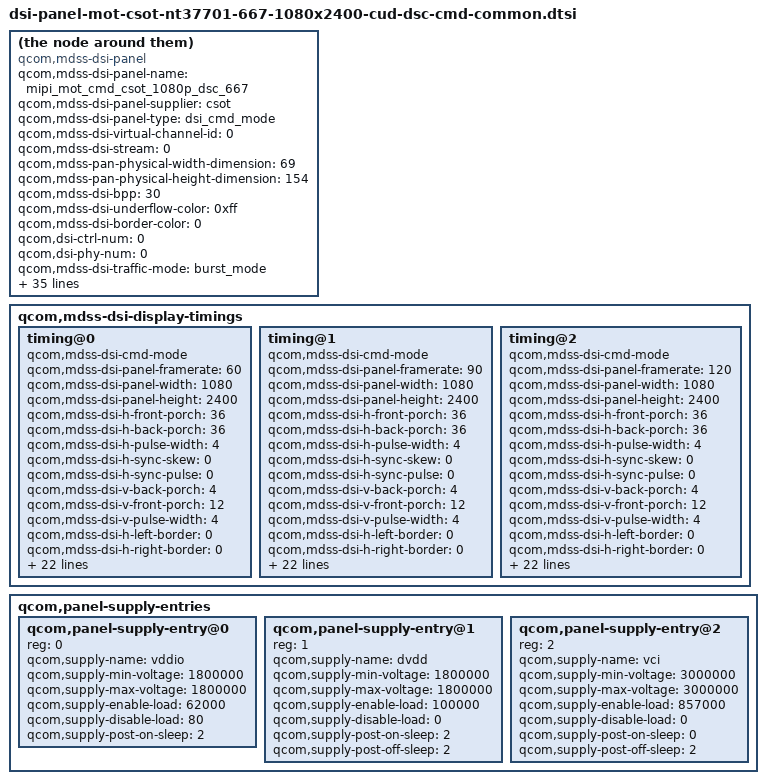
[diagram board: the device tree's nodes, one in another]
/* Copyright (c) 2019-2020, The Linux Foundation. All rights reserved.
 *
 * This program is free software; you can redistribute it and/or modify
 * it under the terms of the GNU General Public License version 2 and
 * only version 2 as published by the Free Software Foundation.
 *
 * This program is distributed in the hope that it will be useful,
 * but WITHOUT ANY WARRANTY; without even the implied warranty of
 * MERCHANTABILITY or FITNESS FOR A PARTICULAR PURPOSE.  See the
 * GNU General Public License for more details.
 */

compatible = "qcom,mdss-dsi-panel";
qcom,mdss-dsi-panel-name = "mipi_mot_cmd_csot_1080p_dsc_667";
qcom,mdss-dsi-panel-supplier = "csot";
qcom,mdss-dsi-panel-type = "dsi_cmd_mode";
qcom,mdss-dsi-virtual-channel-id = <0>;
qcom,mdss-dsi-stream = <0>;
qcom,mdss-pan-physical-width-dimension = <69>;
qcom,mdss-pan-physical-height-dimension = <154>;
qcom,mdss-dsi-bpp = <30>;
qcom,mdss-dsi-underflow-color = <0xff>;
qcom,mdss-dsi-border-color = <0>;

qcom,dsi-ctrl-num = <0>;
qcom,dsi-phy-num = <0>;

qcom,mdss-dsi-traffic-mode = "burst_mode";
qcom,mdss-dsi-bllp-eof-power-mode;
qcom,mdss-dsi-bllp-power-mode;
qcom,mdss-dsi-lane-0-state;
qcom,mdss-dsi-lane-1-state;
qcom,mdss-dsi-lane-2-state;
qcom,mdss-dsi-lane-3-state;

qcom,mdss-dsi-dma-trigger = "trigger_sw";
qcom,mdss-dsi-mdp-trigger = "none";
qcom,mdss-dsi-reset-sequence = <0 11>, <1 1>, <0 1>, <1 11>;
qcom,mdss-dsi-lp11-init;
qcom,mdss-dsi-tx-eot-append;
qcom,mdss-dsi-te-pin-select = <1>;
qcom,mdss-dsi-te-dcs-command = <1>;

qcom,mdss-dsi-te-using-te-pin;

//qcom,esd-check-enabled;
qcom,mdss-dsi-panel-status-check-mode = "te_chk_reg_rd";
qcom,mdss-dsi-panel-status-command = [06 01 00 01 00 00 01 0a];
qcom,mdss-dsi-panel-status-command-state = "dsi_lp_mode";
qcom,mdss-dsi-panel-status-value = <0x9c>;
qcom,mdss-dsi-panel-status-read-length = <1>;

qcom,bklt-dcs-2bytes-enabled;
qcom,mdss-dsi-bl-min-level = <3>;
qcom,mdss-dsi-bl-max-level = <2047>;
qcom,mdss-dsi-bl-default-level = <1024>;
qcom,mdss-brightness-max-level = <2047>;
qcom,mdss-dsi-bl-pmic-control-type = "bl_ctrl_dcs";

qcom,mdss-dsi-hbm-on-command = [
		39 01 00 00 00 00 03 51 0F FF];
qcom,mdss-dsi-hbm-off-command = [
		39 01 00 00 00 00 03 51 07 FF];

//qcom,mdss-dsi-acl-on-command = [
//		39 01 00 00 00 00 06 F0 55 AA 52 08 00
//		15 00 00 00 00 00 02 B0 0C
//		15 01 00 00 00 00 02 55 05];
//qcom,mdss-dsi-acl-off-command = [
//		15 01 00 00 00 00 02 55 00];

qcom,mdss-dsi-panel-hbm-is-51cmd;

qcom,mdss-dsi-display-timings {
	timing@0{
		/* 60 FPS */
		qcom,mdss-dsi-cmd-mode;
		qcom,mdss-dsi-panel-framerate = <60>;
		qcom,mdss-dsi-panel-width = <1080>;
		qcom,mdss-dsi-panel-height = <2400>;
		qcom,mdss-dsi-h-front-porch = <36>;
		qcom,mdss-dsi-h-back-porch = <36>;
		qcom,mdss-dsi-h-pulse-width = <4>;
		qcom,mdss-dsi-h-sync-skew = <0>;
		qcom,mdss-dsi-h-sync-pulse = <0>;
		qcom,mdss-dsi-v-back-porch = <4>;
		qcom,mdss-dsi-v-front-porch = <12>;
		qcom,mdss-dsi-v-pulse-width = <4>;
		qcom,mdss-dsi-h-left-border = <0>;
		qcom,mdss-dsi-h-right-border = <0>;
		qcom,mdss-dsi-v-top-border = <0>;
		qcom,mdss-dsi-v-bottom-border = <0>;
		qcom,mdss-dsi-panel-jitter = <0x20 0xa>;
		//qcom,mdss-mdp-transfer-time-us = <6000>;
		qcom,mdss-dsi-panel-clockrate = <458250000>;
		qcom,mdss-dsi-timing-switch-command = [
			39 01 00 00 00 00 06 F0 55 AA 52 08 02
			15 01 00 00 00 00 02 6F 03
			15 01 00 00 00 00 02 BF 02
			15 01 00 00 10 00 02 2F 01
		];
		qcom,mdss-dsi-on-command = [
			39 01 00 00 00 00 06 F0 55 AA 52 08 00
			15 01 00 00 00 00 02 6F 06
			39 01 00 00 00 00 04 B5 4E 19 50
			15 01 00 00 00 00 02 6F 0D
			15 01 00 00 00 00 02 B5 50
			15 01 00 00 00 00 02 6F 10
			39 01 00 00 00 00 06 B5 19 19 19 19 19

			//CUP enable
			15 01 00 00 00 00 02 99 10

			39 01 00 00 00 00 06 F0 55 AA 52 08 09
			//39 01 00 00 00 00 19 B0 00
			15 01 00 00 00 00 02 B0 01
			39 01 00 00 00 00 19 B1 00 00 00 00 00 00 00 00 00 00 00 00 00 00 00 00 00 00 00 00 00 00 00 00
			15 01 00 00 00 00 02 6F 18
			39 01 00 00 00 00 19 B1 00 00 00 00 00 00 00 00 00 00 00 00 00 00 00 00 00 00 00 00 00 00 00 00
			15 01 00 00 00 00 02 6F 30
			39 01 00 00 00 00 19 B1 00 00 00 00 00 00 00 00 00 00 00 00 00 00 00 00 00 00 00 00 00 00 00 00
			15 01 00 00 00 00 02 6F 48
			39 01 00 00 00 00 19 B1 00 00 00 00 00 00 00 00 00 00 00 00 00 00 00 00 00 00 00 00 00 00 00 00
			15 01 00 00 00 00 02 6F 60
			39 01 00 00 00 00 19 B1 00 00 00 00 00 00 00 00 00 00 00 00 00 00 00 00 00 00 00 00 00 00 00 00
			15 01 00 00 00 00 02 6F 78
			39 01 00 00 00 00 19 B1 00 00 00 00 00 00 00 00 00 00 00 00 00 00 00 00 00 00 00 00 00 00 00 00
			15 01 00 00 00 00 02 6F 90
			39 01 00 00 00 00 19 B1 00 00 00 00 00 00 00 00 00 00 00 00 00 00 00 00 00 00 00 00 00 00 00 00
			15 01 00 00 00 00 02 6F A8
			39 01 00 00 00 00 19 B1 00 00 00 00 00 00 00 00 00 00 00 00 00 00 00 00 00 00 00 00 00 00 00 00
			15 01 00 00 00 00 02 6F C0
			39 01 00 00 00 00 19 B1 00 00 00 00 00 00 00 00 00 00 00 00 00 00 00 00 00 00 00 00 00 00 00 00
			15 01 00 00 00 00 02 6F D8
			39 01 00 00 00 00 19 B1 00 00 00 00 00 00 00 00 00 00 00 00 00 00 00 00 00 00 00 00 00 00 00 00
			15 01 00 00 00 00 02 6F F0
			39 01 00 00 00 00 0D B1 00 00 00 00 00 00 00 00 00 00 00 00
			39 01 00 00 00 00 19 B2 00 00 00 00 00 00 00 00 00 00 00 00 00 00 00 00 00 00 00 00 00 00 00 00
			15 01 00 00 00 00 02 6F 18
			39 01 00 00 00 00 19 B2 00 00 00 00 00 00 00 00 00 00 00 00 00 00 00 00 00 00 00 00 00 00 00 00
			15 01 00 00 00 00 02 6F 30
			39 01 00 00 00 00 19 B2 00 00 00 00 00 00 00 00 00 00 00 00 00 00 00 00 00 00 00 00 00 00 00 00
			15 01 00 00 00 00 02 6F 48
			39 01 00 00 00 00 19 B2 00 00 00 00 00 00 00 00 00 00 00 00 00 00 00 00 00 00 00 00 00 00 00 00
			15 01 00 00 00 00 02 6F 60
			39 01 00 00 00 00 19 B2 00 00 00 00 00 00 00 00 00 00 00 00 00 00 00 00 00 00 00 00 00 00 00 00
			15 01 00 00 00 00 02 6F 78
			39 01 00 00 00 00 19 B2 00 00 00 00 00 00 00 00 00 00 00 00 00 00 00 00 00 00 00 00 00 00 00 00
			15 01 00 00 00 00 02 6F 90
			39 01 00 00 00 00 19 B2 00 00 00 00 00 00 00 00 00 00 00 00 00 00 00 00 00 00 00 00 00 00 00 00
			15 01 00 00 00 00 02 6F A8
			39 01 00 00 00 00 19 B2 00 00 00 00 00 00 00 00 00 00 00 00 00 00 00 00 00 00 00 00 00 00 00 00
			15 01 00 00 00 00 02 6F C0
			39 01 00 00 00 00 19 B2 00 00 00 00 00 00 00 00 00 00 00 00 00 00 00 00 00 00 00 00 00 00 00 00
			15 01 00 00 00 00 02 6F D8
			39 01 00 00 00 00 19 B2 00 00 00 00 00 00 00 00 00 00 00 00 00 00 00 00 00 00 00 00 00 00 00 00
			15 01 00 00 00 00 02 6F F0
			39 01 00 00 00 00 0D B2 00 00 00 00 00 00 00 00 00 00 00 00
			39 01 00 00 00 00 19 B3 00 00 00 00 00 00 00 00 00 00 00 00 00 00 00 00 00 00 00 00 00 00 00 00
			15 01 00 00 00 00 02 6F 18
			39 01 00 00 00 00 19 B3 00 00 00 00 00 00 00 00 00 00 00 00 00 00 00 00 00 00 00 00 00 00 00 00
			15 01 00 00 00 00 02 6F 30
			39 01 00 00 00 00 19 B3 00 00 00 00 00 00 00 00 00 00 00 00 00 00 00 00 00 00 00 00 00 00 00 00
			15 01 00 00 00 00 02 6F 48
			39 01 00 00 00 00 19 B3 00 00 00 00 00 00 00 00 00 00 00 00 00 00 00 00 00 00 00 00 00 00 00 00
			15 01 00 00 00 00 02 6F 60
			39 01 00 00 00 00 19 B3 00 00 00 00 00 00 00 00 00 00 00 00 00 00 00 00 00 00 00 00 00 00 00 00
			15 01 00 00 00 00 02 6F 78
			39 01 00 00 00 00 19 B3 00 00 00 00 00 00 00 00 00 00 00 00 00 00 00 00 00 00 00 00 00 00 00 00
			15 01 00 00 00 00 02 6F 90
			39 01 00 00 00 00 19 B3 00 00 00 00 00 00 00 00 00 00 00 00 00 00 00 00 00 00 00 00 00 00 00 00
			15 01 00 00 00 00 02 6F A8
			39 01 00 00 00 00 19 B3 00 00 00 00 00 00 00 00 00 00 00 00 00 00 00 00 00 00 00 00 00 00 00 00
			15 01 00 00 00 00 02 6F C0
			39 01 00 00 00 00 19 B3 00 00 00 00 00 00 00 00 00 00 00 00 00 00 00 00 00 00 00 00 00 00 00 00
			15 01 00 00 00 00 02 6F D8
			39 01 00 00 00 00 19 B3 00 00 00 00 00 00 00 00 00 00 00 00 00 00 00 00 00 00 00 00 00 00 00 00
			15 01 00 00 00 00 02 6F F0
			39 01 00 00 00 00 0D B3 00 00 00 00 00 00 00 00 00 00 00 00
			39 01 00 00 00 00 19 B4 00 00 00 00 00 00 00 00 00 00 00 00 00 00 00 00 00 00 00 00 00 00 00 00
			15 01 00 00 00 00 02 6F 18
			39 01 00 00 00 00 19 B4 00 00 00 00 00 00 00 00 00 00 00 00 00 00 00 00 00 00 00 00 00 00 00 00
			15 01 00 00 00 00 02 6F 30
			39 01 00 00 00 00 19 B4 00 00 00 00 00 00 00 00 00 00 00 00 00 00 00 00 00 00 00 00 00 00 00 00
			15 01 00 00 00 00 02 6F 48
			39 01 00 00 00 00 19 B4 00 00 00 00 00 00 00 00 00 00 00 00 00 00 00 00 00 00 00 00 00 00 00 00
			15 01 00 00 00 00 02 6F 60
			39 01 00 00 00 00 19 B4 00 00 00 00 00 00 00 00 00 00 00 00 00 00 00 00 00 00 00 00 00 00 00 00
			15 01 00 00 00 00 02 6F 78
			39 01 00 00 00 00 19 B4 00 00 00 00 00 00 00 00 00 00 00 00 00 00 00 00 00 00 00 00 00 00 00 00
			15 01 00 00 00 00 02 6F 90
			39 01 00 00 00 00 19 B4 00 00 00 00 00 00 00 00 00 00 00 00 00 00 00 00 00 00 00 00 00 00 00 00
			15 01 00 00 00 00 02 6F A8
			39 01 00 00 00 00 19 B4 00 00 00 00 00 00 00 00 00 00 00 00 00 00 00 00 00 00 00 00 00 00 00 00
			15 01 00 00 00 00 02 6F C0
			39 01 00 00 00 00 19 B4 00 00 00 00 00 00 00 00 00 00 00 00 00 00 00 00 00 00 00 00 00 00 00 00
			15 01 00 00 00 00 02 6F D8
			39 01 00 00 00 00 19 B4 00 00 00 00 00 00 00 00 00 00 00 00 00 00 00 00 00 00 00 00 00 00 00 00
			15 01 00 00 00 00 02 6F F0
			39 01 00 00 00 00 0D B4 00 00 00 00 00 00 00 00 00 00 00 00
			39 01 00 00 00 00 19 B5 00 00 00 00 00 00 00 00 00 00 00 00 00 00 00 00 00 00 00 00 00 00 00 00
			15 01 00 00 00 00 02 6F 18
			39 01 00 00 00 00 19 B5 00 00 00 00 00 00 00 00 00 00 00 00 00 00 00 00 00 00 00 00 00 00 00 00
			15 01 00 00 00 00 02 6F 30
			39 01 00 00 00 00 19 B5 00 00 00 00 00 00 00 00 00 00 00 00 00 00 00 00 00 00 00 00 00 00 00 00
			15 01 00 00 00 00 02 6F 48
			39 01 00 00 00 00 19 B5 00 00 00 00 00 00 00 00 00 00 00 00 00 00 00 00 00 00 00 00 00 00 00 00
			15 01 00 00 00 00 02 6F 60
			39 01 00 00 00 00 19 B5 00 00 00 00 00 00 00 00 00 00 00 00 00 00 00 00 00 00 00 00 00 00 00 00
			15 01 00 00 00 00 02 6F 78
			39 01 00 00 00 00 19 B5 00 00 00 00 00 00 00 00 00 00 00 00 00 00 00 00 00 00 00 00 00 00 00 00
			15 01 00 00 00 00 02 6F 90
			39 01 00 00 00 00 19 B5 00 00 00 00 00 00 00 00 00 00 00 00 00 00 00 00 00 00 00 00 00 00 00 00
			15 01 00 00 00 00 02 6F A8
			39 01 00 00 00 00 19 B5 00 00 00 00 00 00 00 00 00 00 00 00 00 00 00 00 00 00 00 00 00 00 00 00
			15 01 00 00 00 00 02 6F C0
			39 01 00 00 00 00 19 B5 00 00 00 00 00 00 00 00 00 00 00 00 00 00 00 00 00 00 00 00 00 00 00 00
			15 01 00 00 00 00 02 6F D8
			39 01 00 00 00 00 19 B5 00 00 00 00 00 00 00 00 00 00 00 00 00 00 00 00 00 00 00 00 00 00 00 00
			15 01 00 00 00 00 02 6F F0
			39 01 00 00 00 00 0D B5 00 00 00 00 00 00 00 00 00 00 00 00
			39 01 00 00 00 00 19 B6 00 00 00 00 00 00 00 00 00 00 00 00 00 00 00 00 00 00 00 00 00 00 00 00
			15 01 00 00 00 00 02 6F 18
			39 01 00 00 00 00 19 B6 00 00 00 00 00 00 00 00 00 00 00 00 00 00 00 00 00 00 00 00 00 00 00 00
			15 01 00 00 00 00 02 6F 30
			39 01 00 00 00 00 19 B6 00 00 00 00 00 00 00 00 00 00 00 00 00 00 00 00 00 00 00 00 00 00 00 00
			15 01 00 00 00 00 02 6F 48
			39 01 00 00 00 00 19 B6 00 00 00 00 00 00 00 00 00 00 00 00 00 00 00 00 00 00 00 00 00 00 00 00
			15 01 00 00 00 00 02 6F 60
			39 01 00 00 00 00 19 B6 00 00 00 00 00 00 00 00 00 00 00 00 00 00 00 00 00 00 00 00 00 00 00 00
			15 01 00 00 00 00 02 6F 78
			39 01 00 00 00 00 19 B6 00 00 00 00 00 00 00 00 00 00 00 00 00 00 00 00 00 00 00 00 00 00 00 00
			15 01 00 00 00 00 02 6F 90
			39 01 00 00 00 00 19 B6 00 00 00 00 00 00 00 00 00 00 00 00 00 00 00 00 00 00 00 00 00 00 00 00
			15 01 00 00 00 00 02 6F A8
			39 01 00 00 00 00 19 B6 00 00 00 00 00 00 00 00 00 00 00 00 00 00 00 00 00 00 00 00 00 00 00 00
			15 01 00 00 00 00 02 6F C0
			39 01 00 00 00 00 19 B6 00 00 00 00 00 00 00 00 00 00 00 00 00 00 00 00 00 00 00 00 00 00 00 00
			15 01 00 00 00 00 02 6F D8
			39 01 00 00 00 00 19 B6 00 00 00 00 00 00 00 00 00 00 00 00 00 00 00 00 00 00 00 00 00 00 00 00
			15 01 00 00 00 00 02 6F F0
			39 01 00 00 00 00 0D B6 00 00 00 00 00 00 00 00 00 00 00 00
			39 01 00 00 00 00 19 B7 00 00 00 00 00 00 00 00 00 00 00 00 00 00 00 00 00 00 00 00 00 00 00 00
			15 01 00 00 00 00 02 6F 18
			39 01 00 00 00 00 19 B7 00 00 00 00 00 00 00 00 00 00 00 00 00 00 00 00 00 00 00 00 00 00 00 00
			15 01 00 00 00 00 02 6F 30
			39 01 00 00 00 00 19 B7 00 00 00 00 00 00 00 00 00 00 00 00 00 00 00 00 00 00 00 00 00 00 00 00
			15 01 00 00 00 00 02 6F 48
			39 01 00 00 00 00 19 B7 00 00 00 00 00 00 00 00 00 00 00 00 00 00 00 00 00 00 00 00 00 00 00 00
			15 01 00 00 00 00 02 6F 60
			39 01 00 00 00 00 19 B7 00 00 00 00 00 00 00 00 00 00 00 00 00 00 00 00 00 00 00 00 00 00 00 00
			15 01 00 00 00 00 02 6F 78
			39 01 00 00 00 00 19 B7 00 00 00 00 00 00 00 00 00 00 00 00 00 00 00 00 00 00 00 00 00 00 00 00
			15 01 00 00 00 00 02 6F 90
			39 01 00 00 00 00 19 B7 00 00 00 00 00 00 00 00 00 00 00 00 00 00 00 00 00 00 00 00 00 00 00 00
			15 01 00 00 00 00 02 6F A8
			39 01 00 00 00 00 19 B7 00 00 00 00 00 00 00 00 00 00 00 00 00 00 00 00 00 00 00 00 00 00 00 00
			15 01 00 00 00 00 02 6F C0
			39 01 00 00 00 00 19 B7 00 00 00 00 00 00 00 00 00 00 00 00 00 00 00 00 00 00 00 00 00 00 00 00
			15 01 00 00 00 00 02 6F D8
			39 01 00 00 00 00 19 B7 00 00 00 00 00 00 00 00 00 00 00 00 00 00 00 00 00 00 00 00 00 00 00 00
			15 01 00 00 00 00 02 6F F0
			39 01 00 00 00 00 0D B7 00 00 00 00 00 00 00 00 00 00 00 00

			39 01 00 00 00 00 19 BA 00 00 00 00 00 00 00 00 00 00 00 00 00 00 00 00 00 00 00 00 00 00 00 00
			15 01 00 00 00 00 02 6F 18
			39 01 00 00 00 00 19 BA 00 00 00 00 00 00 00 00 00 00 00 00 00 00 00 00 00 00 00 00 00 00 00 00
			15 01 00 00 00 00 02 6F 30
			39 01 00 00 00 00 19 BA 00 00 00 00 00 00 00 00 00 00 00 00 00 00 00 00 00 00 00 00 00 00 00 00
			15 01 00 00 00 00 02 6F 48
			39 01 00 00 00 00 19 BA 00 00 00 00 00 00 00 00 00 00 00 00 00 00 00 00 00 00 00 00 00 00 00 00
			15 01 00 00 00 00 02 6F 60
			39 01 00 00 00 00 19 BA 00 00 00 00 00 00 00 00 00 00 00 00 00 00 00 00 00 00 00 00 00 00 00 00
			15 01 00 00 00 00 02 6F 78
			39 01 00 00 00 00 19 BA 00 00 00 00 00 00 00 00 00 00 00 00 00 00 00 00 00 00 00 00 00 00 00 00
			15 01 00 00 00 00 02 6F 90
			39 01 00 00 00 00 19 BA 00 00 00 00 00 00 00 00 00 00 00 00 00 00 00 00 00 00 00 00 00 00 00 00
			15 01 00 00 00 00 02 6F A8
			39 01 00 00 00 00 19 BA 00 00 00 00 00 00 00 00 00 00 00 00 00 00 00 00 00 00 00 00 00 00 00 00
			15 01 00 00 00 00 02 6F C0
			39 01 00 00 00 00 19 BA 00 00 00 00 00 00 00 00 00 00 00 00 00 00 00 00 00 00 00 00 00 00 00 00
			15 01 00 00 00 00 02 6F D8
			39 01 00 00 00 00 19 BA 00 00 00 00 00 00 00 00 00 00 00 00 00 00 00 00 00 00 00 00 00 00 00 00
			15 01 00 00 00 00 02 6F F0
			39 01 00 00 00 00 0D BA 00 00 00 00 00 00 00 00 00 00 00 00
			39 01 00 00 00 00 19 BB 00 00 00 00 00 00 00 00 00 00 00 00 00 00 00 00 00 00 00 00 00 00 00 00
			15 01 00 00 00 00 02 6F 18
			39 01 00 00 00 00 19 BB 00 00 00 00 00 00 00 00 00 00 00 00 00 00 00 00 00 00 00 00 00 00 00 00
			15 01 00 00 00 00 02 6F 30
			39 01 00 00 00 00 19 BB 00 00 00 00 00 00 00 00 00 00 00 00 00 00 00 00 00 00 00 00 00 00 00 00
			15 01 00 00 00 00 02 6F 48
			39 01 00 00 00 00 19 BB 00 00 00 00 00 00 00 00 00 00 00 00 00 00 00 00 00 00 00 00 00 00 00 00
			15 01 00 00 00 00 02 6F 60
			39 01 00 00 00 00 19 BB 00 00 00 00 00 00 00 00 00 00 00 00 00 00 00 00 00 00 00 00 00 00 00 00
			15 01 00 00 00 00 02 6F 78
			39 01 00 00 00 00 19 BB 00 00 00 00 00 00 00 00 00 00 00 00 00 00 00 00 00 00 00 00 00 00 00 00
			15 01 00 00 00 00 02 6F 90
			39 01 00 00 00 00 19 BB 00 00 00 00 00 00 00 00 00 00 00 00 00 00 00 00 00 00 00 00 00 00 00 00
			15 01 00 00 00 00 02 6F A8
			39 01 00 00 00 00 19 BB 00 00 00 00 00 00 00 00 00 00 00 00 00 00 00 00 00 00 00 00 00 00 00 00
			15 01 00 00 00 00 02 6F C0
			39 01 00 00 00 00 19 BB 00 00 00 00 00 00 00 00 00 00 00 00 00 00 00 00 00 00 00 00 00 00 00 00
			15 01 00 00 00 00 02 6F D8
			39 01 00 00 00 00 19 BB 00 00 00 00 00 00 00 00 00 00 00 00 00 00 00 00 00 00 00 00 00 00 00 00
			15 01 00 00 00 00 02 6F F0
			39 01 00 00 00 00 0D BB 00 00 00 00 00 00 00 00 00 00 00 00
			39 01 00 00 00 00 19 BC 00 00 00 00 00 00 00 00 00 00 00 00 00 00 00 00 00 00 00 00 00 00 00 00
			15 01 00 00 00 00 02 6F 18
			39 01 00 00 00 00 19 BC 00 00 00 00 00 00 00 00 00 00 00 00 00 00 00 00 00 00 00 00 00 00 00 00
			15 01 00 00 00 00 02 6F 30
			39 01 00 00 00 00 19 BC 00 00 00 00 00 00 00 00 00 00 00 00 00 00 00 00 00 00 00 00 00 00 00 00
			15 01 00 00 00 00 02 6F 48
			39 01 00 00 00 00 19 BC 00 00 00 00 00 00 00 00 00 00 00 00 00 00 00 00 00 00 00 00 00 00 00 00
			15 01 00 00 00 00 02 6F 60
			39 01 00 00 00 00 19 BC 00 00 00 00 00 00 00 00 00 00 00 00 00 00 00 00 00 00 00 00 00 00 00 00
			15 01 00 00 00 00 02 6F 78
			39 01 00 00 00 00 19 BC 00 00 00 00 00 00 00 00 00 00 00 00 00 00 00 00 00 00 00 00 00 00 00 00
			15 01 00 00 00 00 02 6F 90
			39 01 00 00 00 00 19 BC 00 00 00 00 00 00 00 00 00 00 00 00 00 00 00 00 00 00 00 00 00 00 00 00
			15 01 00 00 00 00 02 6F A8
			39 01 00 00 00 00 19 BC 00 00 00 00 00 00 00 00 00 00 00 00 00 00 00 00 00 00 00 00 00 00 00 00
			15 01 00 00 00 00 02 6F C0
			39 01 00 00 00 00 19 BC 00 00 00 00 00 00 00 00 00 00 00 00 00 00 00 00 00 00 00 00 00 00 00 00
			15 01 00 00 00 00 02 6F D8
			39 01 00 00 00 00 19 BC 00 00 00 00 00 00 00 00 00 00 00 00 00 00 00 00 00 00 00 00 00 00 00 00
			15 01 00 00 00 00 02 6F F0
			39 01 00 00 00 00 0D BC 00 00 00 00 00 00 00 00 00 00 00 00
			39 01 00 00 00 00 19 BD 00 00 00 00 00 00 00 00 00 00 00 00 00 00 00 00 00 00 00 00 00 00 00 00
			15 01 00 00 00 00 02 6F 18
			39 01 00 00 00 00 19 BD 00 00 00 00 00 00 00 00 00 00 00 00 00 00 00 00 00 00 00 00 00 00 00 00
			15 01 00 00 00 00 02 6F 30
			39 01 00 00 00 00 19 BD 00 00 00 00 00 00 00 00 00 00 00 00 00 00 00 00 00 00 00 00 00 00 00 00
			15 01 00 00 00 00 02 6F 48
			39 01 00 00 00 00 19 BD 00 00 00 00 00 00 00 00 00 00 00 00 00 00 00 00 00 00 00 00 00 00 00 00
			15 01 00 00 00 00 02 6F 60
			39 01 00 00 00 00 19 BD 00 00 00 00 00 00 00 00 00 00 00 00 00 00 00 00 00 00 00 00 00 00 00 00
			15 01 00 00 00 00 02 6F 78
			39 01 00 00 00 00 19 BD 00 00 00 00 00 00 00 00 00 00 00 00 00 00 00 00 00 00 00 00 00 00 00 00
			15 01 00 00 00 00 02 6F 90
			39 01 00 00 00 00 19 BD 00 00 00 00 00 00 00 00 00 00 00 00 00 00 00 00 00 00 00 00 00 00 00 00
			15 01 00 00 00 00 02 6F A8
			39 01 00 00 00 00 19 BD 00 00 00 00 00 00 00 00 00 00 00 00 00 00 00 00 00 00 00 00 00 00 00 00
			15 01 00 00 00 00 02 6F C0
			39 01 00 00 00 00 19 BD 00 00 00 00 00 00 00 00 00 00 00 00 00 00 00 00 00 00 00 00 00 00 00 00
			15 01 00 00 00 00 02 6F D8
			39 01 00 00 00 00 19 BD 00 00 00 00 00 00 00 00 00 00 00 00 00 00 00 00 00 00 00 00 00 00 00 00
			15 01 00 00 00 00 02 6F F0
			39 01 00 00 00 00 0D BD 00 00 00 00 00 00 00 00 00 00 00 00
			39 01 00 00 00 00 19 BE 00 00 00 00 00 00 00 00 00 00 00 00 00 00 00 00 00 00 00 00 00 00 00 00
			15 01 00 00 00 00 02 6F 18
			39 01 00 00 00 00 19 BE 00 00 00 00 00 00 00 00 00 00 00 00 00 00 00 00 00 00 00 00 00 00 00 00
			15 01 00 00 00 00 02 6F 30
			39 01 00 00 00 00 19 BE 00 00 00 00 00 00 00 00 00 00 00 00 00 00 00 00 00 00 00 00 00 00 00 00
			15 01 00 00 00 00 02 6F 48
			39 01 00 00 00 00 19 BE 00 00 00 00 00 00 00 00 00 00 00 00 00 00 00 00 00 00 00 00 00 00 00 00
			15 01 00 00 00 00 02 6F 60
			39 01 00 00 00 00 19 BE 00 00 00 00 00 00 00 00 00 00 00 00 00 00 00 00 00 00 00 00 00 00 00 00
			15 01 00 00 00 00 02 6F 78
			39 01 00 00 00 00 19 BE 00 00 00 00 00 00 00 00 00 00 00 00 00 00 00 00 00 00 00 00 00 00 00 00
			15 01 00 00 00 00 02 6F 90
			39 01 00 00 00 00 19 BE 00 00 00 00 00 00 00 00 00 00 00 00 00 00 00 00 00 00 00 00 00 00 00 00
			15 01 00 00 00 00 02 6F A8
			39 01 00 00 00 00 19 BE 00 00 00 00 00 00 00 00 00 00 00 00 00 00 00 00 00 00 00 00 00 00 00 00
			15 01 00 00 00 00 02 6F C0
			39 01 00 00 00 00 19 BE 00 00 00 00 00 00 00 00 00 00 00 00 00 00 00 00 00 00 00 00 00 00 00 00
			15 01 00 00 00 00 02 6F D8
			39 01 00 00 00 00 19 BE 00 00 00 00 00 00 00 00 00 00 00 00 00 00 00 00 00 00 00 00 00 00 00 00
			15 01 00 00 00 00 02 6F F0
			39 01 00 00 00 00 0D BE 00 00 00 00 00 00 00 00 00 00 00 00
			39 01 00 00 00 00 19 BF 00 00 00 00 00 00 00 00 00 00 00 00 00 00 00 00 00 00 00 00 00 00 00 00
			15 01 00 00 00 00 02 6F 18
			39 01 00 00 00 00 19 BF 00 00 00 00 00 00 00 00 00 00 00 00 00 00 00 00 00 00 00 00 00 00 00 00
			15 01 00 00 00 00 02 6F 30
			39 01 00 00 00 00 19 BF 00 00 00 00 00 00 00 00 00 00 00 00 00 00 00 00 00 00 00 00 00 00 00 00
			15 01 00 00 00 00 02 6F 48
			39 01 00 00 00 00 19 BF 00 00 00 00 00 00 00 00 00 00 00 00 00 00 00 00 00 00 00 00 00 00 00 00
			15 01 00 00 00 00 02 6F 60
			39 01 00 00 00 00 19 BF 00 00 00 00 00 00 00 00 00 00 00 00 00 00 00 00 00 00 00 00 00 00 00 00
			15 01 00 00 00 00 02 6F 78
			39 01 00 00 00 00 19 BF 00 00 00 00 00 00 00 00 00 00 00 00 00 00 00 00 00 00 00 00 00 00 00 00
			15 01 00 00 00 00 02 6F 90
			39 01 00 00 00 00 19 BF 00 00 00 00 00 00 00 00 00 00 00 00 00 00 00 00 00 00 00 00 00 00 00 00
			15 01 00 00 00 00 02 6F A8
			39 01 00 00 00 00 19 BF 00 00 00 00 00 00 00 00 00 00 00 00 00 00 00 00 00 00 00 00 00 00 00 00
			15 01 00 00 00 00 02 6F C0
			39 01 00 00 00 00 19 BF 00 00 00 00 00 00 00 00 00 00 00 00 00 00 00 00 00 00 00 00 00 00 00 00
			15 01 00 00 00 00 02 6F D8
			39 01 00 00 00 00 19 BF 00 00 00 00 00 00 00 00 00 00 00 00 00 00 00 00 00 00 00 00 00 00 00 00
			15 01 00 00 00 00 02 6F F0
			39 01 00 00 00 00 0D BF 00 00 00 00 00 00 00 00 00 00 00 00
			39 01 00 00 00 00 19 C0 00 00 00 00 00 00 00 00 00 00 00 00 00 00 00 00 00 00 00 00 00 00 00 00
			15 01 00 00 00 00 02 6F 18
			39 01 00 00 00 00 19 C0 00 00 00 00 00 00 00 00 00 00 00 00 00 00 00 00 00 00 00 00 00 00 00 00
			15 01 00 00 00 00 02 6F 30
			39 01 00 00 00 00 19 C0 00 00 00 00 00 00 00 00 00 00 00 00 00 00 00 00 00 00 00 00 00 00 00 00
			15 01 00 00 00 00 02 6F 48
			39 01 00 00 00 00 19 C0 00 00 00 00 00 00 00 00 00 00 00 00 00 00 00 00 00 00 00 00 00 00 00 00
			15 01 00 00 00 00 02 6F 60
			39 01 00 00 00 00 19 C0 00 00 00 00 00 00 00 00 00 00 00 00 00 00 00 00 00 00 00 00 00 00 00 00
			15 01 00 00 00 00 02 6F 78
			39 01 00 00 00 00 19 C0 00 00 00 00 00 00 00 00 00 00 00 00 00 00 00 00 00 00 00 00 00 00 00 00
			15 01 00 00 00 00 02 6F 90
			39 01 00 00 00 00 19 C0 00 00 00 00 00 00 00 00 00 00 00 00 00 00 00 00 00 00 00 00 00 00 00 00
			15 01 00 00 00 00 02 6F A8
			39 01 00 00 00 00 19 C0 00 00 00 00 00 00 00 00 00 00 00 00 00 00 00 00 00 00 00 00 00 00 00 00
			15 01 00 00 00 00 02 6F C0
			39 01 00 00 00 00 19 C0 00 00 00 00 00 00 00 00 00 00 00 00 00 00 00 00 00 00 00 00 00 00 00 00
			15 01 00 00 00 00 02 6F D8
			39 01 00 00 00 00 19 C0 00 00 00 00 00 00 00 00 00 00 00 00 00 00 00 00 00 00 00 00 00 00 00 00
			15 01 00 00 00 00 02 6F F0
			39 01 00 00 00 00 0D C0 00 00 00 00 00 00 00 00 00 00 00 00

			39 01 00 00 00 00 19 C3 00 00 00 60 90 00 00 00 00 00 10 1F 00 00 00 00 50 21 00 00 00 00 00 00
			15 01 00 00 00 00 02 6F 18
			39 01 00 00 00 00 19 C3 00 00 00 00 00 00 00 00 00 00 00 18 00 00 00 00 00 00 00 00 00 00 00 10
			15 01 00 00 00 00 02 6F 30
			39 01 00 00 00 00 19 C3 00 00 00 00 00 00 00 00 00 00 00 10 00 00 00 00 00 00 00 00 00 00 00 10
			15 01 00 00 00 00 02 6F 48
			39 01 00 00 00 00 19 C3 00 00 00 00 00 00 00 00 00 00 00 08 00 00 00 00 00 00 00 00 00 00 00 08
			15 01 00 00 00 00 02 6F 60
			39 01 00 00 00 00 19 C3 00 00 00 00 00 00 00 00 00 00 00 08 00 00 00 00 00 00 00 00 00 00 00 08
			15 01 00 00 00 00 02 6F 78
			39 01 00 00 00 00 19 C3 00 00 00 00 00 00 00 00 00 00 00 00 00 00 00 00 00 00 00 00 00 00 00 08
			15 01 00 00 00 00 02 6F 90
			39 01 00 00 00 00 19 C3 00 00 00 00 00 00 00 00 00 00 00 00 00 00 00 00 00 00 00 00 00 00 00 08
			15 01 00 00 00 00 02 6F A8
			39 01 00 00 00 00 19 C3 00 00 00 00 00 00 00 00 00 00 00 00 00 00 00 00 00 00 00 00 00 00 00 08
			15 01 00 00 00 00 02 6F C0
			39 01 00 00 00 00 19 C3 00 00 00 00 00 00 00 00 00 00 00 00 00 00 00 00 00 00 00 00 00 00 00 00
			15 01 00 00 00 00 02 6F D8
			39 01 00 00 00 00 19 C3 00 00 00 00 00 00 00 00 00 00 00 08 00 00 00 00 00 00 00 00 00 00 00 00
			15 01 00 00 00 00 02 6F F0
			39 01 00 00 00 00 0D C3 00 00 00 00 00 00 00 00 00 00 00 00
			39 01 00 00 00 00 19 C4 00 00 00 00 00 00 00 00 00 00 00 00 00 00 00 00 00 00 00 00 00 00 00 00
			15 01 00 00 00 00 02 6F 18
			39 01 00 00 00 00 19 C4 00 00 00 00 00 00 00 00 00 00 00 00 00 00 00 00 00 00 00 00 00 00 00 00
			15 01 00 00 00 00 02 6F 30
			39 01 00 00 00 00 19 C4 00 00 00 00 00 00 00 00 00 00 00 00 00 00 00 00 00 00 00 00 00 00 00 08
			15 01 00 00 00 00 02 6F 48
			39 01 00 00 00 00 19 C4 00 00 00 00 00 00 00 00 00 00 00 00 00 00 00 00 00 00 00 00 00 00 00 00
			15 01 00 00 00 00 02 6F 60
			39 01 00 00 00 00 19 C4 00 00 00 00 00 00 00 00 00 00 00 08 00 00 00 00 00 00 00 00 00 00 00 00
			15 01 00 00 00 00 02 6F 78
			39 01 00 00 00 00 19 C4 00 00 00 00 00 00 00 00 00 00 00 08 00 00 00 00 00 00 00 00 00 00 00 00
			15 01 00 00 00 00 02 6F 90
			39 01 00 00 00 00 19 C4 00 00 00 00 00 00 00 00 00 00 00 08 00 00 00 00 00 00 00 00 00 00 00 00
			15 01 00 00 00 00 02 6F A8
			39 01 00 00 00 00 19 C4 00 00 00 00 00 00 00 00 00 00 00 08 00 00 00 00 00 00 00 00 00 00 00 08
			15 01 00 00 00 00 02 6F C0
			39 01 00 00 00 00 19 C4 00 00 00 00 00 00 00 00 00 00 00 08 00 00 00 00 00 00 00 00 00 00 00 08
			15 01 00 00 00 00 02 6F D8
			39 01 00 00 00 00 19 C4 00 00 00 00 00 00 00 00 00 00 00 10 00 00 00 00 00 00 00 00 00 00 00 10
			15 01 00 00 00 00 02 6F F0
			39 01 00 00 00 00 0D C4 00 00 00 00 00 00 00 00 00 00 00 10
			39 01 00 00 00 00 19 C5 00 00 00 00 00 00 00 00 00 00 00 18 00 00 00 00 00 00 00 00 00 00 00 00
			15 01 00 00 00 00 02 6F 18
			39 01 00 00 00 00 19 C5 00 00 00 00 00 00 00 00 00 00 00 00 00 00 00 00 00 00 00 00 00 00 00 00
			15 01 00 00 00 00 02 6F 30
			39 01 00 00 00 00 19 C5 00 00 00 00 00 00 00 00 00 00 00 00 00 00 00 00 00 00 00 00 00 00 00 00
			15 01 00 00 00 00 02 6F 48
			39 01 00 00 00 00 19 C5 00 00 00 00 00 00 00 00 00 00 00 00 00 00 00 00 00 00 00 00 00 00 00 00
			15 01 00 00 00 00 02 6F 60
			39 01 00 00 00 00 19 C5 00 00 00 00 00 00 00 00 00 00 00 00 00 00 00 00 00 00 00 00 00 00 00 00
			15 01 00 00 00 00 02 6F 78
			39 01 00 00 00 00 19 C5 00 00 00 00 00 00 00 00 00 00 00 00 00 00 00 00 00 00 00 00 00 00 00 00
			15 01 00 00 00 00 02 6F 90
			39 01 00 00 00 00 19 C5 00 00 00 00 00 00 00 00 00 00 00 00 00 00 00 00 00 00 00 00 00 00 00 00
			15 01 00 00 00 00 02 6F A8
			39 01 00 00 00 00 19 C5 00 00 00 00 00 00 00 00 00 00 00 00 00 00 00 00 00 00 00 00 00 00 00 00
			15 01 00 00 00 00 02 6F C0
			39 01 00 00 00 00 19 C5 00 00 00 00 00 00 00 00 00 00 00 00 00 00 00 00 00 00 00 00 00 00 00 00
			15 01 00 00 00 00 02 6F D8
			39 01 00 00 00 00 19 C5 00 00 00 00 00 00 00 00 00 00 00 00 00 00 00 00 00 00 00 00 00 00 00 00
			15 01 00 00 00 00 02 6F F0
			39 01 00 00 00 00 0D C5 00 00 00 00 00 00 00 00 00 00 00 00
			39 01 00 00 00 00 19 C6 00 00 00 00 00 00 00 00 00 00 00 00 00 00 00 00 00 00 00 00 00 00 00 00
			15 01 00 00 00 00 02 6F 18
			39 01 00 00 00 00 19 C6 00 00 00 00 00 00 00 00 00 00 00 00 00 00 00 00 00 00 00 00 00 00 00 00
			15 01 00 00 00 00 02 6F 30
			39 01 00 00 00 00 19 C6 00 00 00 00 00 00 00 00 00 00 00 00 00 00 00 00 00 00 00 00 00 00 00 00
			15 01 00 00 00 00 02 6F 48
			39 01 00 00 00 00 19 C6 00 00 00 00 00 00 00 00 00 00 00 00 00 00 00 00 00 00 00 00 00 00 00 00
			15 01 00 00 00 00 02 6F 60
			39 01 00 00 00 00 19 C6 00 00 00 00 00 00 00 00 00 00 00 00 00 00 00 00 00 00 00 00 00 00 00 00
			15 01 00 00 00 00 02 6F 78
			39 01 00 00 00 00 19 C6 00 00 00 00 00 00 00 00 00 00 00 00 00 00 00 00 00 00 00 00 00 00 00 00
			15 01 00 00 00 00 02 6F 90
			39 01 00 00 00 00 19 C6 00 00 00 00 00 00 00 00 00 00 00 00 00 00 00 00 00 00 00 00 00 00 00 00
			15 01 00 00 00 00 02 6F A8
			39 01 00 00 00 00 19 C6 00 00 00 00 00 00 00 00 00 00 00 00 00 00 00 00 00 00 00 00 00 00 00 00
			15 01 00 00 00 00 02 6F C0
			39 01 00 00 00 00 19 C6 00 00 00 00 00 00 00 00 00 00 00 00 00 00 00 00 00 00 00 00 00 00 00 00
			15 01 00 00 00 00 02 6F D8
			39 01 00 00 00 00 19 C6 00 00 00 00 00 00 00 00 00 00 00 00 00 00 00 00 00 00 00 00 00 00 00 00
			15 01 00 00 00 00 02 6F F0
			39 01 00 00 00 00 0D C6 00 00 00 00 00 00 00 00 00 00 00 00
			39 01 00 00 00 00 19 C7 00 00 00 00 00 00 00 00 00 00 00 00 00 00 00 00 00 00 00 00 00 00 00 00
			15 01 00 00 00 00 02 6F 18
			39 01 00 00 00 00 19 C7 00 00 00 00 00 00 00 00 00 00 00 00 00 00 00 00 00 00 00 00 00 00 00 00
			15 01 00 00 00 00 02 6F 30
			39 01 00 00 00 00 19 C7 00 00 00 00 00 00 00 00 00 00 00 00 00 00 00 00 00 00 00 00 00 00 00 00
			15 01 00 00 00 00 02 6F 48
			39 01 00 00 00 00 19 C7 00 00 00 00 00 00 00 00 00 00 00 00 00 00 00 00 00 00 00 00 00 00 00 00
			15 01 00 00 00 00 02 6F 60
			39 01 00 00 00 00 19 C7 00 00 00 00 00 00 00 00 00 00 00 00 00 00 00 00 00 00 00 00 00 00 00 00
			15 01 00 00 00 00 02 6F 78
			39 01 00 00 00 00 19 C7 00 00 00 00 00 00 00 00 00 00 00 00 00 00 00 00 00 00 00 00 00 00 00 00
			15 01 00 00 00 00 02 6F 90
			39 01 00 00 00 00 19 C7 00 00 00 00 00 00 00 00 00 00 00 00 00 00 00 00 00 00 00 00 00 00 00 00
			15 01 00 00 00 00 02 6F A8
			39 01 00 00 00 00 19 C7 00 00 00 00 00 00 00 00 00 00 00 00 00 00 00 00 00 00 00 00 00 00 00 00
			15 01 00 00 00 00 02 6F C0
			39 01 00 00 00 00 19 C7 00 00 00 00 00 00 00 00 00 00 00 00 00 00 00 00 00 00 00 00 00 00 00 00
			15 01 00 00 00 00 02 6F D8
			39 01 00 00 00 00 19 C7 00 00 00 00 00 00 00 00 00 00 00 00 00 00 00 00 00 00 00 00 00 00 00 00
			15 01 00 00 00 00 02 6F F0
			39 01 00 00 00 00 0D C7 00 00 00 00 00 00 00 00 00 00 00 00
			39 01 00 00 00 00 19 C8 00 00 00 00 00 00 00 00 00 00 00 00 00 00 00 00 00 00 00 00 00 00 00 00
			15 01 00 00 00 00 02 6F 18
			39 01 00 00 00 00 19 C8 00 00 00 00 00 00 00 00 00 00 00 00 00 00 00 00 00 00 00 00 00 00 00 00
			15 01 00 00 00 00 02 6F 30
			39 01 00 00 00 00 19 C8 00 00 00 00 00 00 00 00 00 00 00 00 00 00 00 00 00 00 00 00 00 00 00 00
			15 01 00 00 00 00 02 6F 48
			39 01 00 00 00 00 19 C8 00 00 00 00 00 00 00 00 00 00 00 00 00 00 00 00 00 00 00 00 00 00 00 00
			15 01 00 00 00 00 02 6F 60
			39 01 00 00 00 00 19 C8 00 00 00 00 00 00 00 00 00 00 00 00 00 00 00 00 00 00 00 00 00 00 00 00
			15 01 00 00 00 00 02 6F 78
			39 01 00 00 00 00 19 C8 00 00 00 00 00 00 00 00 00 00 00 00 00 00 00 00 00 00 00 00 00 00 00 00
			15 01 00 00 00 00 02 6F 90
			39 01 00 00 00 00 19 C8 00 00 00 00 00 00 00 00 00 00 00 00 00 00 00 00 00 00 00 00 00 00 00 00
			15 01 00 00 00 00 02 6F A8
			39 01 00 00 00 00 19 C8 00 00 00 00 00 00 00 00 00 00 00 00 00 00 00 00 00 00 00 00 00 00 00 00
			15 01 00 00 00 00 02 6F C0
			39 01 00 00 00 00 19 C8 00 00 00 00 00 00 00 00 00 00 00 00 00 00 00 00 00 00 00 00 00 00 00 00
			15 01 00 00 00 00 02 6F D8
			39 01 00 00 00 00 19 C8 00 00 00 00 00 00 00 00 00 00 00 00 00 00 00 00 00 00 00 00 00 00 00 00
			15 01 00 00 00 00 02 6F F0
			39 01 00 00 00 00 0D C8 00 00 00 00 00 00 00 00 00 00 00 00
			39 01 00 00 00 00 19 C9 00 00 00 00 00 00 00 00 00 00 00 00 00 00 00 00 00 00 00 00 00 00 00 00
			15 01 00 00 00 00 02 6F 18
			39 01 00 00 00 00 19 C9 00 00 00 00 00 00 00 00 00 00 00 00 00 00 00 00 00 00 00 00 00 00 00 00
			15 01 00 00 00 00 02 6F 30
			39 01 00 00 00 00 19 C9 00 00 00 00 00 00 00 00 00 00 00 00 00 00 00 00 00 00 00 00 00 00 00 00
			15 01 00 00 00 00 02 6F 48
			39 01 00 00 00 00 19 C9 00 00 00 00 00 00 00 00 00 00 00 00 00 00 00 00 00 00 00 00 00 00 00 00
			15 01 00 00 00 00 02 6F 60
			39 01 00 00 00 00 19 C9 00 00 00 00 00 00 00 00 00 00 00 00 00 00 00 00 00 00 00 00 00 00 00 00
			15 01 00 00 00 00 02 6F 78
			39 01 00 00 00 00 19 C9 00 00 00 00 00 00 00 00 00 00 00 00 00 00 00 00 00 00 00 00 00 00 00 00
			15 01 00 00 00 00 02 6F 90
			39 01 00 00 00 00 19 C9 00 00 00 00 00 00 00 00 00 00 00 00 00 00 00 00 00 00 00 00 00 00 00 00
			15 01 00 00 00 00 02 6F A8
			39 01 00 00 00 00 19 C9 00 00 00 00 00 00 00 00 00 00 00 00 00 00 00 00 00 00 00 00 00 00 00 00
			15 01 00 00 00 00 02 6F C0
			39 01 00 00 00 00 19 C9 00 00 00 00 00 00 00 00 00 00 00 00 00 00 00 00 00 00 00 00 00 00 00 00
			15 01 00 00 00 00 02 6F D8
			39 01 00 00 00 00 19 C9 00 00 00 00 00 00 00 00 00 00 00 00 00 00 00 00 00 00 00 00 00 00 00 00
			15 01 00 00 00 00 02 6F F0
			39 01 00 00 00 00 0D C9 00 00 00 00 00 00 00 00 00 00 00 00

			39 01 00 00 00 00 19 CC 00 00 00 60 90 00 00 00 00 00 80 24 00 00 00 00 40 22 00 00 00 00 00 00
			15 01 00 00 00 00 02 6F 18
			39 01 00 00 00 00 19 CC 00 00 00 00 00 00 00 00 00 00 00 18 00 00 00 00 00 00 00 00 00 00 00 10
			15 01 00 00 00 00 02 6F 30
			39 01 00 00 00 00 19 CC 00 00 00 00 00 00 00 00 00 00 00 10 00 00 00 00 00 00 00 00 00 00 00 10
			15 01 00 00 00 00 02 6F 48
			39 01 00 00 00 00 19 CC 00 00 00 00 00 00 00 00 00 00 00 08 00 00 00 00 00 00 00 00 00 00 00 08
			15 01 00 00 00 00 02 6F 60
			39 01 00 00 00 00 19 CC 00 00 00 00 00 00 00 00 00 00 00 08 00 00 00 00 00 00 00 00 00 00 00 08
			15 01 00 00 00 00 02 6F 78
			39 01 00 00 00 00 19 CC 00 00 00 00 00 00 00 00 00 00 00 00 00 00 00 00 00 00 00 00 00 00 00 08
			15 01 00 00 00 00 02 6F 90
			39 01 00 00 00 00 19 CC 00 00 00 00 00 00 00 00 00 00 00 00 00 00 00 00 00 00 00 00 00 00 00 08
			15 01 00 00 00 00 02 6F A8
			39 01 00 00 00 00 19 CC 00 00 00 00 00 00 00 00 00 00 00 00 00 00 00 00 00 00 00 00 00 00 00 08
			15 01 00 00 00 00 02 6F C0
			39 01 00 00 00 00 19 CC 00 00 00 00 00 00 00 00 00 00 00 00 00 00 00 00 00 00 00 00 00 00 00 00
			15 01 00 00 00 00 02 6F D8
			39 01 00 00 00 00 19 CC 00 00 00 00 00 00 00 00 00 00 00 08 00 00 00 00 00 00 00 00 00 00 00 00
			15 01 00 00 00 00 02 6F F0
			39 01 00 00 00 00 0D CC 00 00 00 00 00 00 00 00 00 00 00 00
			39 01 00 00 00 00 19 CD 00 00 00 00 00 00 00 00 00 00 00 00 00 00 00 00 00 00 00 00 00 00 00 00
			15 01 00 00 00 00 02 6F 18
			39 01 00 00 00 00 19 CD 00 00 00 00 00 00 00 00 00 00 00 00 00 00 00 00 00 00 00 00 00 00 00 00
			15 01 00 00 00 00 02 6F 30
			39 01 00 00 00 00 19 CD 00 00 00 00 00 00 00 00 00 00 00 00 00 00 00 00 00 00 00 00 00 00 00 08
			15 01 00 00 00 00 02 6F 48
			39 01 00 00 00 00 19 CD 00 00 00 00 00 00 00 00 00 00 00 00 00 00 00 00 00 00 00 00 00 00 00 00
			15 01 00 00 00 00 02 6F 60
			39 01 00 00 00 00 19 CD 00 00 00 00 00 00 00 00 00 00 00 08 00 00 00 00 00 00 00 00 00 00 00 00
			15 01 00 00 00 00 02 6F 78
			39 01 00 00 00 00 19 CD 00 00 00 00 00 00 00 00 00 00 00 08 00 00 00 00 00 00 00 00 00 00 00 00
			15 01 00 00 00 00 02 6F 90
			39 01 00 00 00 00 19 CD 00 00 00 00 00 00 00 00 00 00 00 08 00 00 00 00 00 00 00 00 00 00 00 00
			15 01 00 00 00 00 02 6F A8
			39 01 00 00 00 00 19 CD 00 00 00 00 00 00 00 00 00 00 00 08 00 00 00 00 00 00 00 00 00 00 00 08
			15 01 00 00 00 00 02 6F C0
			39 01 00 00 00 00 19 CD 00 00 00 00 00 00 00 00 00 00 00 08 00 00 00 00 00 00 00 00 00 00 00 08
			15 01 00 00 00 00 02 6F D8
			39 01 00 00 00 00 19 CD 00 00 00 00 00 00 00 00 00 00 00 10 00 00 00 00 00 00 00 00 00 00 00 10
			15 01 00 00 00 00 02 6F F0
			39 01 00 00 00 00 0D CD 00 00 00 00 00 00 00 00 00 00 00 10
			39 01 00 00 00 00 19 CE 00 00 00 00 00 00 00 00 00 00 00 18 00 00 00 00 00 00 00 00 00 00 00 00
			15 01 00 00 00 00 02 6F 18
			39 01 00 00 00 00 19 CE 00 00 00 00 00 00 00 00 00 00 00 00 00 00 00 00 00 00 00 00 00 00 00 00
			15 01 00 00 00 00 02 6F 30
			39 01 00 00 00 00 19 CE 00 00 00 00 00 00 00 00 00 00 00 00 00 00 00 00 00 00 00 00 00 00 00 00
			15 01 00 00 00 00 02 6F 48
			39 01 00 00 00 00 19 CE 00 00 00 00 00 00 00 00 00 00 00 00 00 00 00 00 00 00 00 00 00 00 00 00
			15 01 00 00 00 00 02 6F 60
			39 01 00 00 00 00 19 CE 00 00 00 00 00 00 00 00 00 00 00 00 00 00 00 00 00 00 00 00 00 00 00 00
			15 01 00 00 00 00 02 6F 78
			39 01 00 00 00 00 19 CE 00 00 00 00 00 00 00 00 00 00 00 00 00 00 00 00 00 00 00 00 00 00 00 00
			15 01 00 00 00 00 02 6F 90
			39 01 00 00 00 00 19 CE 00 00 00 00 00 00 00 00 00 00 00 00 00 00 00 00 00 00 00 00 00 00 00 00
			15 01 00 00 00 00 02 6F A8
			39 01 00 00 00 00 19 CE 00 00 00 00 00 00 00 00 00 00 00 00 00 00 00 00 00 00 00 00 00 00 00 00
			15 01 00 00 00 00 02 6F C0
			39 01 00 00 00 00 19 CE 00 00 00 00 00 00 00 00 00 00 00 00 00 00 00 00 00 00 00 00 00 00 00 00
			15 01 00 00 00 00 02 6F D8
			39 01 00 00 00 00 19 CE 00 00 00 00 00 00 00 00 00 00 00 00 00 00 00 00 00 00 00 00 00 00 00 00
			15 01 00 00 00 00 02 6F F0
			39 01 00 00 00 00 0D CE 00 00 00 00 00 00 00 00 00 00 00 00
			39 01 00 00 00 00 19 CF 00 00 00 00 00 00 00 00 00 00 00 00 00 00 00 00 00 00 00 00 00 00 00 00
			15 01 00 00 00 00 02 6F 18
			39 01 00 00 00 00 19 CF 00 00 00 00 00 00 00 00 00 00 00 00 00 00 00 00 00 00 00 00 00 00 00 00
			15 01 00 00 00 00 02 6F 30
			39 01 00 00 00 00 19 CF 00 00 00 00 00 00 00 00 00 00 00 00 00 00 00 00 00 00 00 00 00 00 00 00
			15 01 00 00 00 00 02 6F 48
			39 01 00 00 00 00 19 CF 00 00 00 00 00 00 00 00 00 00 00 00 00 00 00 00 00 00 00 00 00 00 00 00
			15 01 00 00 00 00 02 6F 60
			39 01 00 00 00 00 19 CF 00 00 00 00 00 00 00 00 00 00 00 00 00 00 00 00 00 00 00 00 00 00 00 00
			15 01 00 00 00 00 02 6F 78
			39 01 00 00 00 00 19 CF 00 00 00 00 00 00 00 00 00 00 00 00 00 00 00 00 00 00 00 00 00 00 00 00
			15 01 00 00 00 00 02 6F 90
			39 01 00 00 00 00 19 CF 00 00 00 00 00 00 00 00 00 00 00 00 00 00 00 00 00 00 00 00 00 00 00 00
			15 01 00 00 00 00 02 6F A8
			39 01 00 00 00 00 19 CF 00 00 00 00 00 00 00 00 00 00 00 00 00 00 00 00 00 00 00 00 00 00 00 00
			15 01 00 00 00 00 02 6F C0
			39 01 00 00 00 00 19 CF 00 00 00 00 00 00 00 00 00 00 00 00 00 00 00 00 00 00 00 00 00 00 00 00
			15 01 00 00 00 00 02 6F D8
			39 01 00 00 00 00 19 CF 00 00 00 00 00 00 00 00 00 00 00 00 00 00 00 00 00 00 00 00 00 00 00 00
			15 01 00 00 00 00 02 6F F0
			39 01 00 00 00 00 0D CF 00 00 00 00 00 00 00 00 00 00 00 00
			39 01 00 00 00 00 19 D0 00 00 00 00 00 00 00 00 00 00 00 00 00 00 00 00 00 00 00 00 00 00 00 00
			15 01 00 00 00 00 02 6F 18
			39 01 00 00 00 00 19 D0 00 00 00 00 00 00 00 00 00 00 00 00 00 00 00 00 00 00 00 00 00 00 00 00
			15 01 00 00 00 00 02 6F 30
			39 01 00 00 00 00 19 D0 00 00 00 00 00 00 00 00 00 00 00 00 00 00 00 00 00 00 00 00 00 00 00 00
			15 01 00 00 00 00 02 6F 48
			39 01 00 00 00 00 19 D0 00 00 00 00 00 00 00 00 00 00 00 00 00 00 00 00 00 00 00 00 00 00 00 00
			15 01 00 00 00 00 02 6F 60
			39 01 00 00 00 00 19 D0 00 00 00 00 00 00 00 00 00 00 00 00 00 00 00 00 00 00 00 00 00 00 00 00
			15 01 00 00 00 00 02 6F 78
			39 01 00 00 00 00 19 D0 00 00 00 00 00 00 00 00 00 00 00 00 00 00 00 00 00 00 00 00 00 00 00 00
			15 01 00 00 00 00 02 6F 90
			39 01 00 00 00 00 19 D0 00 00 00 00 00 00 00 00 00 00 00 00 00 00 00 00 00 00 00 00 00 00 00 00
			15 01 00 00 00 00 02 6F A8
			39 01 00 00 00 00 19 D0 00 00 00 00 00 00 00 00 00 00 00 00 00 00 00 00 00 00 00 00 00 00 00 00
			15 01 00 00 00 00 02 6F C0
			39 01 00 00 00 00 19 D0 00 00 00 00 00 00 00 00 00 00 00 00 00 00 00 00 00 00 00 00 00 00 00 00
			15 01 00 00 00 00 02 6F D8
			39 01 00 00 00 00 19 D0 00 00 00 00 00 00 00 00 00 00 00 00 00 00 00 00 00 00 00 00 00 00 00 00
			15 01 00 00 00 00 02 6F F0
			39 01 00 00 00 00 0D D0 00 00 00 00 00 00 00 00 00 00 00 00
			39 01 00 00 00 00 19 D1 00 00 00 00 00 00 00 00 00 00 00 00 00 00 00 00 00 00 00 00 00 00 00 00
			15 01 00 00 00 00 02 6F 18
			39 01 00 00 00 00 19 D1 00 00 00 00 00 00 00 00 00 00 00 00 00 00 00 00 00 00 00 00 00 00 00 00
			15 01 00 00 00 00 02 6F 30
			39 01 00 00 00 00 19 D1 00 00 00 00 00 00 00 00 00 00 00 00 00 00 00 00 00 00 00 00 00 00 00 00
			15 01 00 00 00 00 02 6F 48
			39 01 00 00 00 00 19 D1 00 00 00 00 00 00 00 00 00 00 00 00 00 00 00 00 00 00 00 00 00 00 00 00
			15 01 00 00 00 00 02 6F 60
			39 01 00 00 00 00 19 D1 00 00 00 00 00 00 00 00 00 00 00 00 00 00 00 00 00 00 00 00 00 00 00 00
			15 01 00 00 00 00 02 6F 78
			39 01 00 00 00 00 19 D1 00 00 00 00 00 00 00 00 00 00 00 00 00 00 00 00 00 00 00 00 00 00 00 00
			15 01 00 00 00 00 02 6F 90
			39 01 00 00 00 00 19 D1 00 00 00 00 00 00 00 00 00 00 00 00 00 00 00 00 00 00 00 00 00 00 00 00
			15 01 00 00 00 00 02 6F A8
			39 01 00 00 00 00 19 D1 00 00 00 00 00 00 00 00 00 00 00 00 00 00 00 00 00 00 00 00 00 00 00 00
			15 01 00 00 00 00 02 6F C0
			39 01 00 00 00 00 19 D1 00 00 00 00 00 00 00 00 00 00 00 00 00 00 00 00 00 00 00 00 00 00 00 00
			15 01 00 00 00 00 02 6F D8
			39 01 00 00 00 00 19 D1 00 00 00 00 00 00 00 00 00 00 00 00 00 00 00 00 00 00 00 00 00 00 00 00
			15 01 00 00 00 00 02 6F F0
			39 01 00 00 00 00 0D D1 00 00 00 00 00 00 00 00 00 00 00 00
			39 01 00 00 00 00 19 D2 00 00 00 00 00 00 00 00 00 00 00 00 00 00 00 00 00 00 00 00 00 00 00 00
			15 01 00 00 00 00 02 6F 18
			39 01 00 00 00 00 19 D2 00 00 00 00 00 00 00 00 00 00 00 00 00 00 00 00 00 00 00 00 00 00 00 00
			15 01 00 00 00 00 02 6F 30
			39 01 00 00 00 00 19 D2 00 00 00 00 00 00 00 00 00 00 00 00 00 00 00 00 00 00 00 00 00 00 00 00
			15 01 00 00 00 00 02 6F 48
			39 01 00 00 00 00 19 D2 00 00 00 00 00 00 00 00 00 00 00 00 00 00 00 00 00 00 00 00 00 00 00 00
			15 01 00 00 00 00 02 6F 60
			39 01 00 00 00 00 19 D2 00 00 00 00 00 00 00 00 00 00 00 00 00 00 00 00 00 00 00 00 00 00 00 00
			15 01 00 00 00 00 02 6F 78
			39 01 00 00 00 00 19 D2 00 00 00 00 00 00 00 00 00 00 00 00 00 00 00 00 00 00 00 00 00 00 00 00
			15 01 00 00 00 00 02 6F 90
			39 01 00 00 00 00 19 D2 00 00 00 00 00 00 00 00 00 00 00 00 00 00 00 00 00 00 00 00 00 00 00 00
			15 01 00 00 00 00 02 6F A8
			39 01 00 00 00 00 19 D2 00 00 00 00 00 00 00 00 00 00 00 00 00 00 00 00 00 00 00 00 00 00 00 00
			15 01 00 00 00 00 02 6F C0
			39 01 00 00 00 00 19 D2 00 00 00 00 00 00 00 00 00 00 00 00 00 00 00 00 00 00 00 00 00 00 00 00
			15 01 00 00 00 00 02 6F D8
			39 01 00 00 00 00 19 D2 00 00 00 00 00 00 00 00 00 00 00 00 00 00 00 00 00 00 00 00 00 00 00 00
			15 01 00 00 00 00 02 6F F0
			39 01 00 00 00 00 0D D2 00 00 00 00 00 00 00 00 00 00 00 00

			15 01 00 00 00 00 02 B0 00
			39 01 00 00 00 00 19 D5 80 00 48 00 FF FF FF FF 00 00 00 00 00 00 00 00 00 00 00 00 00 00 00 00
			15 01 00 00 00 00 02 6F 18
			39 01 00 00 00 00 19 D5 00 00 00 00 00 00 00 00 00 0B 5E 00 0B 5E 00 0B 5E 00 0B 5E 00 0B 5E 00
			15 01 00 00 00 00 02 6F 30
			39 01 00 00 00 00 19 D5 0B 5E 00 0B 5E 00 0B 5E 00 69 3C 00 00 00 00 08 61 00 0B 5E 00 0B 5E 00
			15 01 00 00 00 00 02 6F 48
			39 01 00 00 00 00 19 D5 0B 5E 00 0B 5E 00 0B 5E 00 0B 5E 00 0B 5E 00 0B 5E 00 3C 00 08 61 46 64

			39 01 00 00 00 00 19 D6 55 55 55 55 55 55 55 55 55 55 55 55 55 55 55 55 55 55 55 55 55 55 55 55
			15 01 00 00 00 00 02 6F 18
			39 01 00 00 00 00 19 D6 55 55 55 55 55 55 55 55 55 55 55 55 55 55 55 55 55 55 55 55 55 55 55 55
			15 01 00 00 00 00 02 6F 30
			39 01 00 00 00 00 19 D6 55 55 55 55 55 55 55 55 55 55 55 55 55 55 55 55 80 80 80 00 00 00 FF FF
			15 01 00 00 00 00 02 6F 48
			39 01 00 00 00 00 19 D6 FF 45 45 45 45 45 45 45 45 45 45 45 45 45 45 45 45 45 45 45 45 45 00 00
			15 01 00 00 00 00 02 6F 60
			39 01 00 00 00 00 19 D6 00 3C 3C 3C 33 33 33 2B 2B 2B 22 22 22 19 19 19 11 11 11 08 08 08 00 00
			15 01 00 00 00 00 02 6F 78
			39 01 00 00 00 00 19 D6 00 00 00 00 00 00 00 00 00 00 00 00 00 00 00 00 00 00 00 00 00 00 00 00
			15 01 00 00 00 00 02 6F 90
			15 01 00 00 00 00 02 D6 00
			39 01 00 00 00 00 19 D7 55 55 55 55 55 55 55 55 55 55 55 55 55 55 55 55 54 54 00 00 54 54 00 00
			15 01 00 00 00 00 02 6F 18
			39 01 00 00 00 00 19 D7 54 54 AA AA 54 54 00 80 15 55 15 45 55 05 05 05 50 50 50 50 50 50 50 50
			15 01 00 00 00 00 02 6F 30
			39 01 00 00 00 00 19 D7 00 00 55 55 00 00 55 55 55 55 00 00 55 55 00 00 00 00 00 00 00 00 00 00
			15 01 00 00 00 00 02 6F 48
			39 01 00 00 00 00 19 D7 00 00 00 00 00 00 00 00 00 00 00 00 00 00 00 00 00 00 00 00 00 00 00 00
			15 01 00 00 00 00 02 6F 60
			39 01 00 00 00 00 19 D7 00 00 00 00 00 00 00 00 00 00 00 00 00 00 00 00 00 00 00 00 00 00 00 00
			15 01 00 00 00 00 02 6F 78
			39 01 00 00 00 00 09 D7 00 00 00 00 00 00 00 00
			39 01 00 00 00 00 19 D8 BD FF FD FF FD FF F7 FF F7 FF F7 FF FF FF FF FF FF FF 00 00 00 E6 E6 E6
			15 01 00 00 00 00 02 6F 18
			39 01 00 00 00 00 19 D8 00 00 00 00 00 00 00 00 00 00 00 00 F9 00 00 00 00 00 00 00 00 00 00 00
			15 01 00 00 00 00 02 6F 30
			39 01 00 00 00 00 19 D8 00 00 00 00 00 00 00 00 00 00 00 00 00 00 00 00 00 00 00 00 00 00 00 00
			15 01 00 00 00 00 02 6F 48
			39 01 00 00 00 00 19 D8 00 00 00 FF FF FF 00 00 00 00 00 00 00 00 00 00 00 00 00 00 00 00 00 00
			15 01 00 00 00 00 02 6F 60
			39 01 00 00 00 00 19 D8 00 00 00 00 00 00 00 00 00 00 00 00 00 00 00 00 00 00 00 00 00 00 00 00
			15 01 00 00 00 00 02 6F 78
			39 01 00 00 00 00 19 D8 00 00 00 00 00 00 00 00 00 00 00 00 00 00 00 00 00 00 00 00 00 00 00 00
			15 01 00 00 00 00 02 6F 90
			39 01 00 00 00 00 13 D8 00 00 00 00 00 00 00 00 00 00 00 00 00 00 00 00 00 00
			39 01 00 00 00 00 19 D9 FC 00 8A AA 1A AA AA 98 AA AA 9A AA AA 9A A8 AA AA 06 AA AA 62 AA 8A 8A
			15 01 00 00 00 00 02 6F 18
			39 01 00 00 00 00 19 D9 9A 9A 8A 8A 00 00 00 00 00 00 00 00 00 00 00 00 00 00 00 00 00 00 00 00
			15 01 00 00 00 00 02 6F 30
			39 01 00 00 00 00 09 D9 00 00 00 00 00 00 00 00

			//SPR setting for L area
			39 01 00 00 00 00 06 F0 55 AA 52 08 07
			15 01 00 00 00 00 02 BE 90
			15 01 00 00 00 00 02 6F 03
			39 01 00 00 00 00 07 BE 22 22 22 00 00 00
			15 01 00 00 00 00 02 6F 09
			39 01 00 00 00 00 0D BE 05 05 03 04 03 05 04 04 04 04 04 04

			15 01 00 00 00 00 02 90 01
			39 01 00 00 00 00 13 91 AB 28 00 0C C2 00 03 1C 01 7E 00 0F 08 BB 04 3D 10 F0
			15 01 00 00 00 00 02 03 01
			15 01 00 00 00 00 02 2C 00
			39 01 00 00 00 00 03 51 00 00
			15 01 00 00 00 00 02 53 20
			15 01 00 00 00 00 02 35 00
			39 01 00 00 00 00 05 2A 00 00 04 37
			39 01 00 00 00 00 05 2B 00 00 09 5F
			39 01 00 00 00 00 06 F0 55 AA 52 08 02
			15 01 00 00 00 00 02 6F 03
			15 01 00 00 00 00 02 BF 02
			15 01 00 00 00 00 02 2F 01
			05 01 00 00 78 00 01 11
			05 01 00 00 00 00 01 29];	/* display on */
		qcom,mdss-dsi-off-command = [
			05 01 00 00 00 00 01 28		/* display_off */
			05 01 00 00 78 00 01 10];	/* enter sleep mode */

		qcom,mdss-dsi-on-command-state = "dsi_lp_mode";
		qcom,mdss-dsi-off-command-state = "dsi_lp_mode";
		qcom,mdss-dsi-timing-switch-command-state = "dsi_lp_mode";

		qcom,compression-mode = "dsc";
		qcom,mdss-dsc-version = <0x11>;
		qcom,mdss-dsc-slice-height = <12>;
		qcom,mdss-dsc-slice-width = <1080>;
		qcom,mdss-dsc-slice-per-pkt = <1>;
		qcom,mdss-dsc-bit-per-component = <10>;
		qcom,mdss-dsc-bit-per-pixel = <10>;
		qcom,mdss-dsc-block-prediction-enable;
	};

	timing@1{
		/* 90 FPS */
		qcom,mdss-dsi-cmd-mode;
		qcom,mdss-dsi-panel-framerate = <90>;
		qcom,mdss-dsi-panel-width = <1080>;
		qcom,mdss-dsi-panel-height = <2400>;
		qcom,mdss-dsi-h-front-porch = <36>;
		qcom,mdss-dsi-h-back-porch = <36>;
		qcom,mdss-dsi-h-pulse-width = <4>;
		qcom,mdss-dsi-h-sync-skew = <0>;
		qcom,mdss-dsi-h-sync-pulse = <0>;
		qcom,mdss-dsi-v-back-porch = <4>;
		qcom,mdss-dsi-v-front-porch = <12>;
		qcom,mdss-dsi-v-pulse-width = <4>;
		qcom,mdss-dsi-h-left-border = <0>;
		qcom,mdss-dsi-h-right-border = <0>;
		qcom,mdss-dsi-v-top-border = <0>;
		qcom,mdss-dsi-v-bottom-border = <0>;
		qcom,mdss-dsi-panel-jitter = <0x20 0xa>;
		qcom,mdss-dsi-panel-clockrate = <687380000>;
		qcom,mdss-dsi-timing-switch-command = [
			39 01 00 00 00 00 06 F0 55 AA 52 08 02
			15 01 00 00 00 00 02 6F 03
			15 01 00 00 00 00 02 BF 05
			15 01 00 00 0B 00 02 2F 02
		];
		qcom,mdss-dsi-on-command = [
			39 01 00 00 00 00 06 F0 55 AA 52 08 00
			15 01 00 00 00 00 02 6F 06
			39 01 00 00 00 00 04 B5 4E 19 50
			15 01 00 00 00 00 02 6F 0D
			15 01 00 00 00 00 02 B5 50
			15 01 00 00 00 00 02 6F 10
			39 01 00 00 00 00 06 B5 19 19 19 19 19

			//CUP enable
			15 01 00 00 00 00 02 99 10

			39 01 00 00 00 00 06 F0 55 AA 52 08 09
			//39 01 00 00 00 00 19 B0 00
			15 01 00 00 00 00 02 B0 01
			39 01 00 00 00 00 19 B1 00 00 00 00 00 00 00 00 00 00 00 00 00 00 00 00 00 00 00 00 00 00 00 00
			15 01 00 00 00 00 02 6F 18
			39 01 00 00 00 00 19 B1 00 00 00 00 00 00 00 00 00 00 00 00 00 00 00 00 00 00 00 00 00 00 00 00
			15 01 00 00 00 00 02 6F 30
			39 01 00 00 00 00 19 B1 00 00 00 00 00 00 00 00 00 00 00 00 00 00 00 00 00 00 00 00 00 00 00 00
			15 01 00 00 00 00 02 6F 48
			39 01 00 00 00 00 19 B1 00 00 00 00 00 00 00 00 00 00 00 00 00 00 00 00 00 00 00 00 00 00 00 00
			15 01 00 00 00 00 02 6F 60
			39 01 00 00 00 00 19 B1 00 00 00 00 00 00 00 00 00 00 00 00 00 00 00 00 00 00 00 00 00 00 00 00
			15 01 00 00 00 00 02 6F 78
			39 01 00 00 00 00 19 B1 00 00 00 00 00 00 00 00 00 00 00 00 00 00 00 00 00 00 00 00 00 00 00 00
			15 01 00 00 00 00 02 6F 90
			39 01 00 00 00 00 19 B1 00 00 00 00 00 00 00 00 00 00 00 00 00 00 00 00 00 00 00 00 00 00 00 00
			15 01 00 00 00 00 02 6F A8
			39 01 00 00 00 00 19 B1 00 00 00 00 00 00 00 00 00 00 00 00 00 00 00 00 00 00 00 00 00 00 00 00
			15 01 00 00 00 00 02 6F C0
			39 01 00 00 00 00 19 B1 00 00 00 00 00 00 00 00 00 00 00 00 00 00 00 00 00 00 00 00 00 00 00 00
			15 01 00 00 00 00 02 6F D8
			39 01 00 00 00 00 19 B1 00 00 00 00 00 00 00 00 00 00 00 00 00 00 00 00 00 00 00 00 00 00 00 00
			15 01 00 00 00 00 02 6F F0
			39 01 00 00 00 00 0D B1 00 00 00 00 00 00 00 00 00 00 00 00
			39 01 00 00 00 00 19 B2 00 00 00 00 00 00 00 00 00 00 00 00 00 00 00 00 00 00 00 00 00 00 00 00
			15 01 00 00 00 00 02 6F 18
			39 01 00 00 00 00 19 B2 00 00 00 00 00 00 00 00 00 00 00 00 00 00 00 00 00 00 00 00 00 00 00 00
			15 01 00 00 00 00 02 6F 30
			39 01 00 00 00 00 19 B2 00 00 00 00 00 00 00 00 00 00 00 00 00 00 00 00 00 00 00 00 00 00 00 00
			15 01 00 00 00 00 02 6F 48
			39 01 00 00 00 00 19 B2 00 00 00 00 00 00 00 00 00 00 00 00 00 00 00 00 00 00 00 00 00 00 00 00
			15 01 00 00 00 00 02 6F 60
			39 01 00 00 00 00 19 B2 00 00 00 00 00 00 00 00 00 00 00 00 00 00 00 00 00 00 00 00 00 00 00 00
			15 01 00 00 00 00 02 6F 78
			39 01 00 00 00 00 19 B2 00 00 00 00 00 00 00 00 00 00 00 00 00 00 00 00 00 00 00 00 00 00 00 00
			15 01 00 00 00 00 02 6F 90
			39 01 00 00 00 00 19 B2 00 00 00 00 00 00 00 00 00 00 00 00 00 00 00 00 00 00 00 00 00 00 00 00
			15 01 00 00 00 00 02 6F A8
			39 01 00 00 00 00 19 B2 00 00 00 00 00 00 00 00 00 00 00 00 00 00 00 00 00 00 00 00 00 00 00 00
			15 01 00 00 00 00 02 6F C0
			39 01 00 00 00 00 19 B2 00 00 00 00 00 00 00 00 00 00 00 00 00 00 00 00 00 00 00 00 00 00 00 00
			15 01 00 00 00 00 02 6F D8
			39 01 00 00 00 00 19 B2 00 00 00 00 00 00 00 00 00 00 00 00 00 00 00 00 00 00 00 00 00 00 00 00
			15 01 00 00 00 00 02 6F F0
			39 01 00 00 00 00 0D B2 00 00 00 00 00 00 00 00 00 00 00 00
			39 01 00 00 00 00 19 B3 00 00 00 00 00 00 00 00 00 00 00 00 00 00 00 00 00 00 00 00 00 00 00 00
			15 01 00 00 00 00 02 6F 18
			39 01 00 00 00 00 19 B3 00 00 00 00 00 00 00 00 00 00 00 00 00 00 00 00 00 00 00 00 00 00 00 00
			15 01 00 00 00 00 02 6F 30
			39 01 00 00 00 00 19 B3 00 00 00 00 00 00 00 00 00 00 00 00 00 00 00 00 00 00 00 00 00 00 00 00
			15 01 00 00 00 00 02 6F 48
			39 01 00 00 00 00 19 B3 00 00 00 00 00 00 00 00 00 00 00 00 00 00 00 00 00 00 00 00 00 00 00 00
			15 01 00 00 00 00 02 6F 60
			39 01 00 00 00 00 19 B3 00 00 00 00 00 00 00 00 00 00 00 00 00 00 00 00 00 00 00 00 00 00 00 00
			15 01 00 00 00 00 02 6F 78
			39 01 00 00 00 00 19 B3 00 00 00 00 00 00 00 00 00 00 00 00 00 00 00 00 00 00 00 00 00 00 00 00
			15 01 00 00 00 00 02 6F 90
			39 01 00 00 00 00 19 B3 00 00 00 00 00 00 00 00 00 00 00 00 00 00 00 00 00 00 00 00 00 00 00 00
			15 01 00 00 00 00 02 6F A8
			39 01 00 00 00 00 19 B3 00 00 00 00 00 00 00 00 00 00 00 00 00 00 00 00 00 00 00 00 00 00 00 00
			15 01 00 00 00 00 02 6F C0
			39 01 00 00 00 00 19 B3 00 00 00 00 00 00 00 00 00 00 00 00 00 00 00 00 00 00 00 00 00 00 00 00
			15 01 00 00 00 00 02 6F D8
			39 01 00 00 00 00 19 B3 00 00 00 00 00 00 00 00 00 00 00 00 00 00 00 00 00 00 00 00 00 00 00 00
			15 01 00 00 00 00 02 6F F0
			39 01 00 00 00 00 0D B3 00 00 00 00 00 00 00 00 00 00 00 00
			39 01 00 00 00 00 19 B4 00 00 00 00 00 00 00 00 00 00 00 00 00 00 00 00 00 00 00 00 00 00 00 00
			15 01 00 00 00 00 02 6F 18
			39 01 00 00 00 00 19 B4 00 00 00 00 00 00 00 00 00 00 00 00 00 00 00 00 00 00 00 00 00 00 00 00
			15 01 00 00 00 00 02 6F 30
			39 01 00 00 00 00 19 B4 00 00 00 00 00 00 00 00 00 00 00 00 00 00 00 00 00 00 00 00 00 00 00 00
			15 01 00 00 00 00 02 6F 48
			39 01 00 00 00 00 19 B4 00 00 00 00 00 00 00 00 00 00 00 00 00 00 00 00 00 00 00 00 00 00 00 00
			15 01 00 00 00 00 02 6F 60
			39 01 00 00 00 00 19 B4 00 00 00 00 00 00 00 00 00 00 00 00 00 00 00 00 00 00 00 00 00 00 00 00
			15 01 00 00 00 00 02 6F 78
			39 01 00 00 00 00 19 B4 00 00 00 00 00 00 00 00 00 00 00 00 00 00 00 00 00 00 00 00 00 00 00 00
			15 01 00 00 00 00 02 6F 90
			39 01 00 00 00 00 19 B4 00 00 00 00 00 00 00 00 00 00 00 00 00 00 00 00 00 00 00 00 00 00 00 00
			15 01 00 00 00 00 02 6F A8
			39 01 00 00 00 00 19 B4 00 00 00 00 00 00 00 00 00 00 00 00 00 00 00 00 00 00 00 00 00 00 00 00
			15 01 00 00 00 00 02 6F C0
			39 01 00 00 00 00 19 B4 00 00 00 00 00 00 00 00 00 00 00 00 00 00 00 00 00 00 00 00 00 00 00 00
			15 01 00 00 00 00 02 6F D8
			39 01 00 00 00 00 19 B4 00 00 00 00 00 00 00 00 00 00 00 00 00 00 00 00 00 00 00 00 00 00 00 00
			15 01 00 00 00 00 02 6F F0
			39 01 00 00 00 00 0D B4 00 00 00 00 00 00 00 00 00 00 00 00
			39 01 00 00 00 00 19 B5 00 00 00 00 00 00 00 00 00 00 00 00 00 00 00 00 00 00 00 00 00 00 00 00
			15 01 00 00 00 00 02 6F 18
			39 01 00 00 00 00 19 B5 00 00 00 00 00 00 00 00 00 00 00 00 00 00 00 00 00 00 00 00 00 00 00 00
			15 01 00 00 00 00 02 6F 30
			39 01 00 00 00 00 19 B5 00 00 00 00 00 00 00 00 00 00 00 00 00 00 00 00 00 00 00 00 00 00 00 00
			15 01 00 00 00 00 02 6F 48
			39 01 00 00 00 00 19 B5 00 00 00 00 00 00 00 00 00 00 00 00 00 00 00 00 00 00 00 00 00 00 00 00
			15 01 00 00 00 00 02 6F 60
			39 01 00 00 00 00 19 B5 00 00 00 00 00 00 00 00 00 00 00 00 00 00 00 00 00 00 00 00 00 00 00 00
			15 01 00 00 00 00 02 6F 78
			39 01 00 00 00 00 19 B5 00 00 00 00 00 00 00 00 00 00 00 00 00 00 00 00 00 00 00 00 00 00 00 00
			15 01 00 00 00 00 02 6F 90
			39 01 00 00 00 00 19 B5 00 00 00 00 00 00 00 00 00 00 00 00 00 00 00 00 00 00 00 00 00 00 00 00
			15 01 00 00 00 00 02 6F A8
			39 01 00 00 00 00 19 B5 00 00 00 00 00 00 00 00 00 00 00 00 00 00 00 00 00 00 00 00 00 00 00 00
			15 01 00 00 00 00 02 6F C0
			39 01 00 00 00 00 19 B5 00 00 00 00 00 00 00 00 00 00 00 00 00 00 00 00 00 00 00 00 00 00 00 00
			15 01 00 00 00 00 02 6F D8
			39 01 00 00 00 00 19 B5 00 00 00 00 00 00 00 00 00 00 00 00 00 00 00 00 00 00 00 00 00 00 00 00
			15 01 00 00 00 00 02 6F F0
			39 01 00 00 00 00 0D B5 00 00 00 00 00 00 00 00 00 00 00 00
			39 01 00 00 00 00 19 B6 00 00 00 00 00 00 00 00 00 00 00 00 00 00 00 00 00 00 00 00 00 00 00 00
			15 01 00 00 00 00 02 6F 18
			39 01 00 00 00 00 19 B6 00 00 00 00 00 00 00 00 00 00 00 00 00 00 00 00 00 00 00 00 00 00 00 00
			15 01 00 00 00 00 02 6F 30
			39 01 00 00 00 00 19 B6 00 00 00 00 00 00 00 00 00 00 00 00 00 00 00 00 00 00 00 00 00 00 00 00
			15 01 00 00 00 00 02 6F 48
			39 01 00 00 00 00 19 B6 00 00 00 00 00 00 00 00 00 00 00 00 00 00 00 00 00 00 00 00 00 00 00 00
			15 01 00 00 00 00 02 6F 60
			39 01 00 00 00 00 19 B6 00 00 00 00 00 00 00 00 00 00 00 00 00 00 00 00 00 00 00 00 00 00 00 00
			15 01 00 00 00 00 02 6F 78
			39 01 00 00 00 00 19 B6 00 00 00 00 00 00 00 00 00 00 00 00 00 00 00 00 00 00 00 00 00 00 00 00
			15 01 00 00 00 00 02 6F 90
			39 01 00 00 00 00 19 B6 00 00 00 00 00 00 00 00 00 00 00 00 00 00 00 00 00 00 00 00 00 00 00 00
			15 01 00 00 00 00 02 6F A8
			39 01 00 00 00 00 19 B6 00 00 00 00 00 00 00 00 00 00 00 00 00 00 00 00 00 00 00 00 00 00 00 00
			15 01 00 00 00 00 02 6F C0
			39 01 00 00 00 00 19 B6 00 00 00 00 00 00 00 00 00 00 00 00 00 00 00 00 00 00 00 00 00 00 00 00
			15 01 00 00 00 00 02 6F D8
			39 01 00 00 00 00 19 B6 00 00 00 00 00 00 00 00 00 00 00 00 00 00 00 00 00 00 00 00 00 00 00 00
			15 01 00 00 00 00 02 6F F0
			39 01 00 00 00 00 0D B6 00 00 00 00 00 00 00 00 00 00 00 00
			39 01 00 00 00 00 19 B7 00 00 00 00 00 00 00 00 00 00 00 00 00 00 00 00 00 00 00 00 00 00 00 00
			15 01 00 00 00 00 02 6F 18
			39 01 00 00 00 00 19 B7 00 00 00 00 00 00 00 00 00 00 00 00 00 00 00 00 00 00 00 00 00 00 00 00
			15 01 00 00 00 00 02 6F 30
			39 01 00 00 00 00 19 B7 00 00 00 00 00 00 00 00 00 00 00 00 00 00 00 00 00 00 00 00 00 00 00 00
			15 01 00 00 00 00 02 6F 48
			39 01 00 00 00 00 19 B7 00 00 00 00 00 00 00 00 00 00 00 00 00 00 00 00 00 00 00 00 00 00 00 00
			15 01 00 00 00 00 02 6F 60
			39 01 00 00 00 00 19 B7 00 00 00 00 00 00 00 00 00 00 00 00 00 00 00 00 00 00 00 00 00 00 00 00
			15 01 00 00 00 00 02 6F 78
			39 01 00 00 00 00 19 B7 00 00 00 00 00 00 00 00 00 00 00 00 00 00 00 00 00 00 00 00 00 00 00 00
			15 01 00 00 00 00 02 6F 90
			39 01 00 00 00 00 19 B7 00 00 00 00 00 00 00 00 00 00 00 00 00 00 00 00 00 00 00 00 00 00 00 00
			15 01 00 00 00 00 02 6F A8
			39 01 00 00 00 00 19 B7 00 00 00 00 00 00 00 00 00 00 00 00 00 00 00 00 00 00 00 00 00 00 00 00
			15 01 00 00 00 00 02 6F C0
			39 01 00 00 00 00 19 B7 00 00 00 00 00 00 00 00 00 00 00 00 00 00 00 00 00 00 00 00 00 00 00 00
			15 01 00 00 00 00 02 6F D8
			39 01 00 00 00 00 19 B7 00 00 00 00 00 00 00 00 00 00 00 00 00 00 00 00 00 00 00 00 00 00 00 00
			15 01 00 00 00 00 02 6F F0
			39 01 00 00 00 00 0D B7 00 00 00 00 00 00 00 00 00 00 00 00

			39 01 00 00 00 00 19 BA 00 00 00 00 00 00 00 00 00 00 00 00 00 00 00 00 00 00 00 00 00 00 00 00
			15 01 00 00 00 00 02 6F 18
			39 01 00 00 00 00 19 BA 00 00 00 00 00 00 00 00 00 00 00 00 00 00 00 00 00 00 00 00 00 00 00 00
			15 01 00 00 00 00 02 6F 30
			39 01 00 00 00 00 19 BA 00 00 00 00 00 00 00 00 00 00 00 00 00 00 00 00 00 00 00 00 00 00 00 00
			15 01 00 00 00 00 02 6F 48
			39 01 00 00 00 00 19 BA 00 00 00 00 00 00 00 00 00 00 00 00 00 00 00 00 00 00 00 00 00 00 00 00
			15 01 00 00 00 00 02 6F 60
			39 01 00 00 00 00 19 BA 00 00 00 00 00 00 00 00 00 00 00 00 00 00 00 00 00 00 00 00 00 00 00 00
			15 01 00 00 00 00 02 6F 78
			39 01 00 00 00 00 19 BA 00 00 00 00 00 00 00 00 00 00 00 00 00 00 00 00 00 00 00 00 00 00 00 00
			15 01 00 00 00 00 02 6F 90
			39 01 00 00 00 00 19 BA 00 00 00 00 00 00 00 00 00 00 00 00 00 00 00 00 00 00 00 00 00 00 00 00
			15 01 00 00 00 00 02 6F A8
			39 01 00 00 00 00 19 BA 00 00 00 00 00 00 00 00 00 00 00 00 00 00 00 00 00 00 00 00 00 00 00 00
			15 01 00 00 00 00 02 6F C0
			39 01 00 00 00 00 19 BA 00 00 00 00 00 00 00 00 00 00 00 00 00 00 00 00 00 00 00 00 00 00 00 00
			15 01 00 00 00 00 02 6F D8
			39 01 00 00 00 00 19 BA 00 00 00 00 00 00 00 00 00 00 00 00 00 00 00 00 00 00 00 00 00 00 00 00
			15 01 00 00 00 00 02 6F F0
			39 01 00 00 00 00 0D BA 00 00 00 00 00 00 00 00 00 00 00 00
			39 01 00 00 00 00 19 BB 00 00 00 00 00 00 00 00 00 00 00 00 00 00 00 00 00 00 00 00 00 00 00 00
			15 01 00 00 00 00 02 6F 18
			39 01 00 00 00 00 19 BB 00 00 00 00 00 00 00 00 00 00 00 00 00 00 00 00 00 00 00 00 00 00 00 00
			15 01 00 00 00 00 02 6F 30
			39 01 00 00 00 00 19 BB 00 00 00 00 00 00 00 00 00 00 00 00 00 00 00 00 00 00 00 00 00 00 00 00
			15 01 00 00 00 00 02 6F 48
			39 01 00 00 00 00 19 BB 00 00 00 00 00 00 00 00 00 00 00 00 00 00 00 00 00 00 00 00 00 00 00 00
			15 01 00 00 00 00 02 6F 60
			39 01 00 00 00 00 19 BB 00 00 00 00 00 00 00 00 00 00 00 00 00 00 00 00 00 00 00 00 00 00 00 00
			15 01 00 00 00 00 02 6F 78
			39 01 00 00 00 00 19 BB 00 00 00 00 00 00 00 00 00 00 00 00 00 00 00 00 00 00 00 00 00 00 00 00
			15 01 00 00 00 00 02 6F 90
			39 01 00 00 00 00 19 BB 00 00 00 00 00 00 00 00 00 00 00 00 00 00 00 00 00 00 00 00 00 00 00 00
			15 01 00 00 00 00 02 6F A8
			39 01 00 00 00 00 19 BB 00 00 00 00 00 00 00 00 00 00 00 00 00 00 00 00 00 00 00 00 00 00 00 00
			15 01 00 00 00 00 02 6F C0
			39 01 00 00 00 00 19 BB 00 00 00 00 00 00 00 00 00 00 00 00 00 00 00 00 00 00 00 00 00 00 00 00
			15 01 00 00 00 00 02 6F D8
			39 01 00 00 00 00 19 BB 00 00 00 00 00 00 00 00 00 00 00 00 00 00 00 00 00 00 00 00 00 00 00 00
			15 01 00 00 00 00 02 6F F0
			39 01 00 00 00 00 0D BB 00 00 00 00 00 00 00 00 00 00 00 00
			39 01 00 00 00 00 19 BC 00 00 00 00 00 00 00 00 00 00 00 00 00 00 00 00 00 00 00 00 00 00 00 00
			15 01 00 00 00 00 02 6F 18
			39 01 00 00 00 00 19 BC 00 00 00 00 00 00 00 00 00 00 00 00 00 00 00 00 00 00 00 00 00 00 00 00
			15 01 00 00 00 00 02 6F 30
			39 01 00 00 00 00 19 BC 00 00 00 00 00 00 00 00 00 00 00 00 00 00 00 00 00 00 00 00 00 00 00 00
			15 01 00 00 00 00 02 6F 48
			39 01 00 00 00 00 19 BC 00 00 00 00 00 00 00 00 00 00 00 00 00 00 00 00 00 00 00 00 00 00 00 00
			15 01 00 00 00 00 02 6F 60
			39 01 00 00 00 00 19 BC 00 00 00 00 00 00 00 00 00 00 00 00 00 00 00 00 00 00 00 00 00 00 00 00
			15 01 00 00 00 00 02 6F 78
			39 01 00 00 00 00 19 BC 00 00 00 00 00 00 00 00 00 00 00 00 00 00 00 00 00 00 00 00 00 00 00 00
			15 01 00 00 00 00 02 6F 90
			39 01 00 00 00 00 19 BC 00 00 00 00 00 00 00 00 00 00 00 00 00 00 00 00 00 00 00 00 00 00 00 00
			15 01 00 00 00 00 02 6F A8
			39 01 00 00 00 00 19 BC 00 00 00 00 00 00 00 00 00 00 00 00 00 00 00 00 00 00 00 00 00 00 00 00
			15 01 00 00 00 00 02 6F C0
			39 01 00 00 00 00 19 BC 00 00 00 00 00 00 00 00 00 00 00 00 00 00 00 00 00 00 00 00 00 00 00 00
			15 01 00 00 00 00 02 6F D8
			39 01 00 00 00 00 19 BC 00 00 00 00 00 00 00 00 00 00 00 00 00 00 00 00 00 00 00 00 00 00 00 00
			15 01 00 00 00 00 02 6F F0
			39 01 00 00 00 00 0D BC 00 00 00 00 00 00 00 00 00 00 00 00
			39 01 00 00 00 00 19 BD 00 00 00 00 00 00 00 00 00 00 00 00 00 00 00 00 00 00 00 00 00 00 00 00
			15 01 00 00 00 00 02 6F 18
			39 01 00 00 00 00 19 BD 00 00 00 00 00 00 00 00 00 00 00 00 00 00 00 00 00 00 00 00 00 00 00 00
			15 01 00 00 00 00 02 6F 30
			39 01 00 00 00 00 19 BD 00 00 00 00 00 00 00 00 00 00 00 00 00 00 00 00 00 00 00 00 00 00 00 00
			15 01 00 00 00 00 02 6F 48
			39 01 00 00 00 00 19 BD 00 00 00 00 00 00 00 00 00 00 00 00 00 00 00 00 00 00 00 00 00 00 00 00
			15 01 00 00 00 00 02 6F 60
			39 01 00 00 00 00 19 BD 00 00 00 00 00 00 00 00 00 00 00 00 00 00 00 00 00 00 00 00 00 00 00 00
			15 01 00 00 00 00 02 6F 78
			39 01 00 00 00 00 19 BD 00 00 00 00 00 00 00 00 00 00 00 00 00 00 00 00 00 00 00 00 00 00 00 00
			15 01 00 00 00 00 02 6F 90
			39 01 00 00 00 00 19 BD 00 00 00 00 00 00 00 00 00 00 00 00 00 00 00 00 00 00 00 00 00 00 00 00
			15 01 00 00 00 00 02 6F A8
			39 01 00 00 00 00 19 BD 00 00 00 00 00 00 00 00 00 00 00 00 00 00 00 00 00 00 00 00 00 00 00 00
			15 01 00 00 00 00 02 6F C0
			39 01 00 00 00 00 19 BD 00 00 00 00 00 00 00 00 00 00 00 00 00 00 00 00 00 00 00 00 00 00 00 00
			15 01 00 00 00 00 02 6F D8
			39 01 00 00 00 00 19 BD 00 00 00 00 00 00 00 00 00 00 00 00 00 00 00 00 00 00 00 00 00 00 00 00
			15 01 00 00 00 00 02 6F F0
			39 01 00 00 00 00 0D BD 00 00 00 00 00 00 00 00 00 00 00 00
			39 01 00 00 00 00 19 BE 00 00 00 00 00 00 00 00 00 00 00 00 00 00 00 00 00 00 00 00 00 00 00 00
			15 01 00 00 00 00 02 6F 18
			39 01 00 00 00 00 19 BE 00 00 00 00 00 00 00 00 00 00 00 00 00 00 00 00 00 00 00 00 00 00 00 00
			15 01 00 00 00 00 02 6F 30
			39 01 00 00 00 00 19 BE 00 00 00 00 00 00 00 00 00 00 00 00 00 00 00 00 00 00 00 00 00 00 00 00
			15 01 00 00 00 00 02 6F 48
			39 01 00 00 00 00 19 BE 00 00 00 00 00 00 00 00 00 00 00 00 00 00 00 00 00 00 00 00 00 00 00 00
			15 01 00 00 00 00 02 6F 60
			39 01 00 00 00 00 19 BE 00 00 00 00 00 00 00 00 00 00 00 00 00 00 00 00 00 00 00 00 00 00 00 00
			15 01 00 00 00 00 02 6F 78
			39 01 00 00 00 00 19 BE 00 00 00 00 00 00 00 00 00 00 00 00 00 00 00 00 00 00 00 00 00 00 00 00
			15 01 00 00 00 00 02 6F 90
			39 01 00 00 00 00 19 BE 00 00 00 00 00 00 00 00 00 00 00 00 00 00 00 00 00 00 00 00 00 00 00 00
			15 01 00 00 00 00 02 6F A8
			39 01 00 00 00 00 19 BE 00 00 00 00 00 00 00 00 00 00 00 00 00 00 00 00 00 00 00 00 00 00 00 00
			15 01 00 00 00 00 02 6F C0
			39 01 00 00 00 00 19 BE 00 00 00 00 00 00 00 00 00 00 00 00 00 00 00 00 00 00 00 00 00 00 00 00
			15 01 00 00 00 00 02 6F D8
			39 01 00 00 00 00 19 BE 00 00 00 00 00 00 00 00 00 00 00 00 00 00 00 00 00 00 00 00 00 00 00 00
			15 01 00 00 00 00 02 6F F0
			39 01 00 00 00 00 0D BE 00 00 00 00 00 00 00 00 00 00 00 00
			39 01 00 00 00 00 19 BF 00 00 00 00 00 00 00 00 00 00 00 00 00 00 00 00 00 00 00 00 00 00 00 00
			15 01 00 00 00 00 02 6F 18
			39 01 00 00 00 00 19 BF 00 00 00 00 00 00 00 00 00 00 00 00 00 00 00 00 00 00 00 00 00 00 00 00
			15 01 00 00 00 00 02 6F 30
			39 01 00 00 00 00 19 BF 00 00 00 00 00 00 00 00 00 00 00 00 00 00 00 00 00 00 00 00 00 00 00 00
			15 01 00 00 00 00 02 6F 48
			39 01 00 00 00 00 19 BF 00 00 00 00 00 00 00 00 00 00 00 00 00 00 00 00 00 00 00 00 00 00 00 00
			15 01 00 00 00 00 02 6F 60
			39 01 00 00 00 00 19 BF 00 00 00 00 00 00 00 00 00 00 00 00 00 00 00 00 00 00 00 00 00 00 00 00
			15 01 00 00 00 00 02 6F 78
			39 01 00 00 00 00 19 BF 00 00 00 00 00 00 00 00 00 00 00 00 00 00 00 00 00 00 00 00 00 00 00 00
			15 01 00 00 00 00 02 6F 90
			39 01 00 00 00 00 19 BF 00 00 00 00 00 00 00 00 00 00 00 00 00 00 00 00 00 00 00 00 00 00 00 00
			15 01 00 00 00 00 02 6F A8
			39 01 00 00 00 00 19 BF 00 00 00 00 00 00 00 00 00 00 00 00 00 00 00 00 00 00 00 00 00 00 00 00
			15 01 00 00 00 00 02 6F C0
			39 01 00 00 00 00 19 BF 00 00 00 00 00 00 00 00 00 00 00 00 00 00 00 00 00 00 00 00 00 00 00 00
			15 01 00 00 00 00 02 6F D8
			39 01 00 00 00 00 19 BF 00 00 00 00 00 00 00 00 00 00 00 00 00 00 00 00 00 00 00 00 00 00 00 00
			15 01 00 00 00 00 02 6F F0
			39 01 00 00 00 00 0D BF 00 00 00 00 00 00 00 00 00 00 00 00
			39 01 00 00 00 00 19 C0 00 00 00 00 00 00 00 00 00 00 00 00 00 00 00 00 00 00 00 00 00 00 00 00
			15 01 00 00 00 00 02 6F 18
			39 01 00 00 00 00 19 C0 00 00 00 00 00 00 00 00 00 00 00 00 00 00 00 00 00 00 00 00 00 00 00 00
			15 01 00 00 00 00 02 6F 30
			39 01 00 00 00 00 19 C0 00 00 00 00 00 00 00 00 00 00 00 00 00 00 00 00 00 00 00 00 00 00 00 00
			15 01 00 00 00 00 02 6F 48
			39 01 00 00 00 00 19 C0 00 00 00 00 00 00 00 00 00 00 00 00 00 00 00 00 00 00 00 00 00 00 00 00
			15 01 00 00 00 00 02 6F 60
			39 01 00 00 00 00 19 C0 00 00 00 00 00 00 00 00 00 00 00 00 00 00 00 00 00 00 00 00 00 00 00 00
			15 01 00 00 00 00 02 6F 78
			39 01 00 00 00 00 19 C0 00 00 00 00 00 00 00 00 00 00 00 00 00 00 00 00 00 00 00 00 00 00 00 00
			15 01 00 00 00 00 02 6F 90
			39 01 00 00 00 00 19 C0 00 00 00 00 00 00 00 00 00 00 00 00 00 00 00 00 00 00 00 00 00 00 00 00
			15 01 00 00 00 00 02 6F A8
			39 01 00 00 00 00 19 C0 00 00 00 00 00 00 00 00 00 00 00 00 00 00 00 00 00 00 00 00 00 00 00 00
			15 01 00 00 00 00 02 6F C0
			39 01 00 00 00 00 19 C0 00 00 00 00 00 00 00 00 00 00 00 00 00 00 00 00 00 00 00 00 00 00 00 00
			15 01 00 00 00 00 02 6F D8
			39 01 00 00 00 00 19 C0 00 00 00 00 00 00 00 00 00 00 00 00 00 00 00 00 00 00 00 00 00 00 00 00
			15 01 00 00 00 00 02 6F F0
			39 01 00 00 00 00 0D C0 00 00 00 00 00 00 00 00 00 00 00 00

			39 01 00 00 00 00 19 C3 00 00 00 60 90 00 00 00 00 00 10 1F 00 00 00 00 50 21 00 00 00 00 00 00
			15 01 00 00 00 00 02 6F 18
			39 01 00 00 00 00 19 C3 00 00 00 00 00 00 00 00 00 00 00 18 00 00 00 00 00 00 00 00 00 00 00 10
			15 01 00 00 00 00 02 6F 30
			39 01 00 00 00 00 19 C3 00 00 00 00 00 00 00 00 00 00 00 10 00 00 00 00 00 00 00 00 00 00 00 10
			15 01 00 00 00 00 02 6F 48
			39 01 00 00 00 00 19 C3 00 00 00 00 00 00 00 00 00 00 00 08 00 00 00 00 00 00 00 00 00 00 00 08
			15 01 00 00 00 00 02 6F 60
			39 01 00 00 00 00 19 C3 00 00 00 00 00 00 00 00 00 00 00 08 00 00 00 00 00 00 00 00 00 00 00 08
			15 01 00 00 00 00 02 6F 78
			39 01 00 00 00 00 19 C3 00 00 00 00 00 00 00 00 00 00 00 00 00 00 00 00 00 00 00 00 00 00 00 08
			15 01 00 00 00 00 02 6F 90
			39 01 00 00 00 00 19 C3 00 00 00 00 00 00 00 00 00 00 00 00 00 00 00 00 00 00 00 00 00 00 00 08
			15 01 00 00 00 00 02 6F A8
			39 01 00 00 00 00 19 C3 00 00 00 00 00 00 00 00 00 00 00 00 00 00 00 00 00 00 00 00 00 00 00 08
			15 01 00 00 00 00 02 6F C0
			39 01 00 00 00 00 19 C3 00 00 00 00 00 00 00 00 00 00 00 00 00 00 00 00 00 00 00 00 00 00 00 00
			15 01 00 00 00 00 02 6F D8
			39 01 00 00 00 00 19 C3 00 00 00 00 00 00 00 00 00 00 00 08 00 00 00 00 00 00 00 00 00 00 00 00
			15 01 00 00 00 00 02 6F F0
			39 01 00 00 00 00 0D C3 00 00 00 00 00 00 00 00 00 00 00 00
			39 01 00 00 00 00 19 C4 00 00 00 00 00 00 00 00 00 00 00 00 00 00 00 00 00 00 00 00 00 00 00 00
			15 01 00 00 00 00 02 6F 18
			39 01 00 00 00 00 19 C4 00 00 00 00 00 00 00 00 00 00 00 00 00 00 00 00 00 00 00 00 00 00 00 00
			15 01 00 00 00 00 02 6F 30
			39 01 00 00 00 00 19 C4 00 00 00 00 00 00 00 00 00 00 00 00 00 00 00 00 00 00 00 00 00 00 00 08
			15 01 00 00 00 00 02 6F 48
			39 01 00 00 00 00 19 C4 00 00 00 00 00 00 00 00 00 00 00 00 00 00 00 00 00 00 00 00 00 00 00 00
			15 01 00 00 00 00 02 6F 60
			39 01 00 00 00 00 19 C4 00 00 00 00 00 00 00 00 00 00 00 08 00 00 00 00 00 00 00 00 00 00 00 00
			15 01 00 00 00 00 02 6F 78
			39 01 00 00 00 00 19 C4 00 00 00 00 00 00 00 00 00 00 00 08 00 00 00 00 00 00 00 00 00 00 00 00
			15 01 00 00 00 00 02 6F 90
			39 01 00 00 00 00 19 C4 00 00 00 00 00 00 00 00 00 00 00 08 00 00 00 00 00 00 00 00 00 00 00 00
			15 01 00 00 00 00 02 6F A8
			39 01 00 00 00 00 19 C4 00 00 00 00 00 00 00 00 00 00 00 08 00 00 00 00 00 00 00 00 00 00 00 08
			15 01 00 00 00 00 02 6F C0
			39 01 00 00 00 00 19 C4 00 00 00 00 00 00 00 00 00 00 00 08 00 00 00 00 00 00 00 00 00 00 00 08
			15 01 00 00 00 00 02 6F D8
			39 01 00 00 00 00 19 C4 00 00 00 00 00 00 00 00 00 00 00 10 00 00 00 00 00 00 00 00 00 00 00 10
			15 01 00 00 00 00 02 6F F0
			39 01 00 00 00 00 0D C4 00 00 00 00 00 00 00 00 00 00 00 10
			39 01 00 00 00 00 19 C5 00 00 00 00 00 00 00 00 00 00 00 18 00 00 00 00 00 00 00 00 00 00 00 00
			15 01 00 00 00 00 02 6F 18
			39 01 00 00 00 00 19 C5 00 00 00 00 00 00 00 00 00 00 00 00 00 00 00 00 00 00 00 00 00 00 00 00
			15 01 00 00 00 00 02 6F 30
			39 01 00 00 00 00 19 C5 00 00 00 00 00 00 00 00 00 00 00 00 00 00 00 00 00 00 00 00 00 00 00 00
			15 01 00 00 00 00 02 6F 48
			39 01 00 00 00 00 19 C5 00 00 00 00 00 00 00 00 00 00 00 00 00 00 00 00 00 00 00 00 00 00 00 00
			15 01 00 00 00 00 02 6F 60
			39 01 00 00 00 00 19 C5 00 00 00 00 00 00 00 00 00 00 00 00 00 00 00 00 00 00 00 00 00 00 00 00
			15 01 00 00 00 00 02 6F 78
			39 01 00 00 00 00 19 C5 00 00 00 00 00 00 00 00 00 00 00 00 00 00 00 00 00 00 00 00 00 00 00 00
			15 01 00 00 00 00 02 6F 90
			39 01 00 00 00 00 19 C5 00 00 00 00 00 00 00 00 00 00 00 00 00 00 00 00 00 00 00 00 00 00 00 00
			15 01 00 00 00 00 02 6F A8
			39 01 00 00 00 00 19 C5 00 00 00 00 00 00 00 00 00 00 00 00 00 00 00 00 00 00 00 00 00 00 00 00
			15 01 00 00 00 00 02 6F C0
			39 01 00 00 00 00 19 C5 00 00 00 00 00 00 00 00 00 00 00 00 00 00 00 00 00 00 00 00 00 00 00 00
			15 01 00 00 00 00 02 6F D8
			39 01 00 00 00 00 19 C5 00 00 00 00 00 00 00 00 00 00 00 00 00 00 00 00 00 00 00 00 00 00 00 00
			15 01 00 00 00 00 02 6F F0
			39 01 00 00 00 00 0D C5 00 00 00 00 00 00 00 00 00 00 00 00
			39 01 00 00 00 00 19 C6 00 00 00 00 00 00 00 00 00 00 00 00 00 00 00 00 00 00 00 00 00 00 00 00
			15 01 00 00 00 00 02 6F 18
			39 01 00 00 00 00 19 C6 00 00 00 00 00 00 00 00 00 00 00 00 00 00 00 00 00 00 00 00 00 00 00 00
			15 01 00 00 00 00 02 6F 30
			39 01 00 00 00 00 19 C6 00 00 00 00 00 00 00 00 00 00 00 00 00 00 00 00 00 00 00 00 00 00 00 00
			15 01 00 00 00 00 02 6F 48
			39 01 00 00 00 00 19 C6 00 00 00 00 00 00 00 00 00 00 00 00 00 00 00 00 00 00 00 00 00 00 00 00
			15 01 00 00 00 00 02 6F 60
			39 01 00 00 00 00 19 C6 00 00 00 00 00 00 00 00 00 00 00 00 00 00 00 00 00 00 00 00 00 00 00 00
			15 01 00 00 00 00 02 6F 78
			39 01 00 00 00 00 19 C6 00 00 00 00 00 00 00 00 00 00 00 00 00 00 00 00 00 00 00 00 00 00 00 00
			15 01 00 00 00 00 02 6F 90
			39 01 00 00 00 00 19 C6 00 00 00 00 00 00 00 00 00 00 00 00 00 00 00 00 00 00 00 00 00 00 00 00
			15 01 00 00 00 00 02 6F A8
			39 01 00 00 00 00 19 C6 00 00 00 00 00 00 00 00 00 00 00 00 00 00 00 00 00 00 00 00 00 00 00 00
			15 01 00 00 00 00 02 6F C0
			39 01 00 00 00 00 19 C6 00 00 00 00 00 00 00 00 00 00 00 00 00 00 00 00 00 00 00 00 00 00 00 00
			15 01 00 00 00 00 02 6F D8
			39 01 00 00 00 00 19 C6 00 00 00 00 00 00 00 00 00 00 00 00 00 00 00 00 00 00 00 00 00 00 00 00
			15 01 00 00 00 00 02 6F F0
			39 01 00 00 00 00 0D C6 00 00 00 00 00 00 00 00 00 00 00 00
			39 01 00 00 00 00 19 C7 00 00 00 00 00 00 00 00 00 00 00 00 00 00 00 00 00 00 00 00 00 00 00 00
			15 01 00 00 00 00 02 6F 18
			39 01 00 00 00 00 19 C7 00 00 00 00 00 00 00 00 00 00 00 00 00 00 00 00 00 00 00 00 00 00 00 00
			15 01 00 00 00 00 02 6F 30
			39 01 00 00 00 00 19 C7 00 00 00 00 00 00 00 00 00 00 00 00 00 00 00 00 00 00 00 00 00 00 00 00
			15 01 00 00 00 00 02 6F 48
			39 01 00 00 00 00 19 C7 00 00 00 00 00 00 00 00 00 00 00 00 00 00 00 00 00 00 00 00 00 00 00 00
			15 01 00 00 00 00 02 6F 60
			39 01 00 00 00 00 19 C7 00 00 00 00 00 00 00 00 00 00 00 00 00 00 00 00 00 00 00 00 00 00 00 00
			15 01 00 00 00 00 02 6F 78
			39 01 00 00 00 00 19 C7 00 00 00 00 00 00 00 00 00 00 00 00 00 00 00 00 00 00 00 00 00 00 00 00
			15 01 00 00 00 00 02 6F 90
			39 01 00 00 00 00 19 C7 00 00 00 00 00 00 00 00 00 00 00 00 00 00 00 00 00 00 00 00 00 00 00 00
			15 01 00 00 00 00 02 6F A8
			39 01 00 00 00 00 19 C7 00 00 00 00 00 00 00 00 00 00 00 00 00 00 00 00 00 00 00 00 00 00 00 00
			15 01 00 00 00 00 02 6F C0
			39 01 00 00 00 00 19 C7 00 00 00 00 00 00 00 00 00 00 00 00 00 00 00 00 00 00 00 00 00 00 00 00
			15 01 00 00 00 00 02 6F D8
			39 01 00 00 00 00 19 C7 00 00 00 00 00 00 00 00 00 00 00 00 00 00 00 00 00 00 00 00 00 00 00 00
			15 01 00 00 00 00 02 6F F0
			39 01 00 00 00 00 0D C7 00 00 00 00 00 00 00 00 00 00 00 00
			39 01 00 00 00 00 19 C8 00 00 00 00 00 00 00 00 00 00 00 00 00 00 00 00 00 00 00 00 00 00 00 00
			15 01 00 00 00 00 02 6F 18
			39 01 00 00 00 00 19 C8 00 00 00 00 00 00 00 00 00 00 00 00 00 00 00 00 00 00 00 00 00 00 00 00
			15 01 00 00 00 00 02 6F 30
			39 01 00 00 00 00 19 C8 00 00 00 00 00 00 00 00 00 00 00 00 00 00 00 00 00 00 00 00 00 00 00 00
			15 01 00 00 00 00 02 6F 48
			39 01 00 00 00 00 19 C8 00 00 00 00 00 00 00 00 00 00 00 00 00 00 00 00 00 00 00 00 00 00 00 00
			15 01 00 00 00 00 02 6F 60
			39 01 00 00 00 00 19 C8 00 00 00 00 00 00 00 00 00 00 00 00 00 00 00 00 00 00 00 00 00 00 00 00
			15 01 00 00 00 00 02 6F 78
			39 01 00 00 00 00 19 C8 00 00 00 00 00 00 00 00 00 00 00 00 00 00 00 00 00 00 00 00 00 00 00 00
			15 01 00 00 00 00 02 6F 90
			39 01 00 00 00 00 19 C8 00 00 00 00 00 00 00 00 00 00 00 00 00 00 00 00 00 00 00 00 00 00 00 00
			15 01 00 00 00 00 02 6F A8
			39 01 00 00 00 00 19 C8 00 00 00 00 00 00 00 00 00 00 00 00 00 00 00 00 00 00 00 00 00 00 00 00
			15 01 00 00 00 00 02 6F C0
			39 01 00 00 00 00 19 C8 00 00 00 00 00 00 00 00 00 00 00 00 00 00 00 00 00 00 00 00 00 00 00 00
			15 01 00 00 00 00 02 6F D8
			39 01 00 00 00 00 19 C8 00 00 00 00 00 00 00 00 00 00 00 00 00 00 00 00 00 00 00 00 00 00 00 00
			15 01 00 00 00 00 02 6F F0
			39 01 00 00 00 00 0D C8 00 00 00 00 00 00 00 00 00 00 00 00
			39 01 00 00 00 00 19 C9 00 00 00 00 00 00 00 00 00 00 00 00 00 00 00 00 00 00 00 00 00 00 00 00
			15 01 00 00 00 00 02 6F 18
			39 01 00 00 00 00 19 C9 00 00 00 00 00 00 00 00 00 00 00 00 00 00 00 00 00 00 00 00 00 00 00 00
			15 01 00 00 00 00 02 6F 30
			39 01 00 00 00 00 19 C9 00 00 00 00 00 00 00 00 00 00 00 00 00 00 00 00 00 00 00 00 00 00 00 00
			15 01 00 00 00 00 02 6F 48
			39 01 00 00 00 00 19 C9 00 00 00 00 00 00 00 00 00 00 00 00 00 00 00 00 00 00 00 00 00 00 00 00
			15 01 00 00 00 00 02 6F 60
			39 01 00 00 00 00 19 C9 00 00 00 00 00 00 00 00 00 00 00 00 00 00 00 00 00 00 00 00 00 00 00 00
			15 01 00 00 00 00 02 6F 78
			39 01 00 00 00 00 19 C9 00 00 00 00 00 00 00 00 00 00 00 00 00 00 00 00 00 00 00 00 00 00 00 00
			15 01 00 00 00 00 02 6F 90
			39 01 00 00 00 00 19 C9 00 00 00 00 00 00 00 00 00 00 00 00 00 00 00 00 00 00 00 00 00 00 00 00
			15 01 00 00 00 00 02 6F A8
			39 01 00 00 00 00 19 C9 00 00 00 00 00 00 00 00 00 00 00 00 00 00 00 00 00 00 00 00 00 00 00 00
			15 01 00 00 00 00 02 6F C0
			39 01 00 00 00 00 19 C9 00 00 00 00 00 00 00 00 00 00 00 00 00 00 00 00 00 00 00 00 00 00 00 00
			15 01 00 00 00 00 02 6F D8
			39 01 00 00 00 00 19 C9 00 00 00 00 00 00 00 00 00 00 00 00 00 00 00 00 00 00 00 00 00 00 00 00
			15 01 00 00 00 00 02 6F F0
			39 01 00 00 00 00 0D C9 00 00 00 00 00 00 00 00 00 00 00 00

			39 01 00 00 00 00 19 CC 00 00 00 60 90 00 00 00 00 00 80 24 00 00 00 00 40 22 00 00 00 00 00 00
			15 01 00 00 00 00 02 6F 18
			39 01 00 00 00 00 19 CC 00 00 00 00 00 00 00 00 00 00 00 18 00 00 00 00 00 00 00 00 00 00 00 10
			15 01 00 00 00 00 02 6F 30
			39 01 00 00 00 00 19 CC 00 00 00 00 00 00 00 00 00 00 00 10 00 00 00 00 00 00 00 00 00 00 00 10
			15 01 00 00 00 00 02 6F 48
			39 01 00 00 00 00 19 CC 00 00 00 00 00 00 00 00 00 00 00 08 00 00 00 00 00 00 00 00 00 00 00 08
			15 01 00 00 00 00 02 6F 60
			39 01 00 00 00 00 19 CC 00 00 00 00 00 00 00 00 00 00 00 08 00 00 00 00 00 00 00 00 00 00 00 08
			15 01 00 00 00 00 02 6F 78
			39 01 00 00 00 00 19 CC 00 00 00 00 00 00 00 00 00 00 00 00 00 00 00 00 00 00 00 00 00 00 00 08
			15 01 00 00 00 00 02 6F 90
			39 01 00 00 00 00 19 CC 00 00 00 00 00 00 00 00 00 00 00 00 00 00 00 00 00 00 00 00 00 00 00 08
			15 01 00 00 00 00 02 6F A8
			39 01 00 00 00 00 19 CC 00 00 00 00 00 00 00 00 00 00 00 00 00 00 00 00 00 00 00 00 00 00 00 08
			15 01 00 00 00 00 02 6F C0
			39 01 00 00 00 00 19 CC 00 00 00 00 00 00 00 00 00 00 00 00 00 00 00 00 00 00 00 00 00 00 00 00
			15 01 00 00 00 00 02 6F D8
			39 01 00 00 00 00 19 CC 00 00 00 00 00 00 00 00 00 00 00 08 00 00 00 00 00 00 00 00 00 00 00 00
			15 01 00 00 00 00 02 6F F0
			39 01 00 00 00 00 0D CC 00 00 00 00 00 00 00 00 00 00 00 00
			39 01 00 00 00 00 19 CD 00 00 00 00 00 00 00 00 00 00 00 00 00 00 00 00 00 00 00 00 00 00 00 00
			15 01 00 00 00 00 02 6F 18
			39 01 00 00 00 00 19 CD 00 00 00 00 00 00 00 00 00 00 00 00 00 00 00 00 00 00 00 00 00 00 00 00
			15 01 00 00 00 00 02 6F 30
			39 01 00 00 00 00 19 CD 00 00 00 00 00 00 00 00 00 00 00 00 00 00 00 00 00 00 00 00 00 00 00 08
			15 01 00 00 00 00 02 6F 48
			39 01 00 00 00 00 19 CD 00 00 00 00 00 00 00 00 00 00 00 00 00 00 00 00 00 00 00 00 00 00 00 00
			15 01 00 00 00 00 02 6F 60
			39 01 00 00 00 00 19 CD 00 00 00 00 00 00 00 00 00 00 00 08 00 00 00 00 00 00 00 00 00 00 00 00
			15 01 00 00 00 00 02 6F 78
			39 01 00 00 00 00 19 CD 00 00 00 00 00 00 00 00 00 00 00 08 00 00 00 00 00 00 00 00 00 00 00 00
			15 01 00 00 00 00 02 6F 90
			39 01 00 00 00 00 19 CD 00 00 00 00 00 00 00 00 00 00 00 08 00 00 00 00 00 00 00 00 00 00 00 00
			15 01 00 00 00 00 02 6F A8
			39 01 00 00 00 00 19 CD 00 00 00 00 00 00 00 00 00 00 00 08 00 00 00 00 00 00 00 00 00 00 00 08
			15 01 00 00 00 00 02 6F C0
			39 01 00 00 00 00 19 CD 00 00 00 00 00 00 00 00 00 00 00 08 00 00 00 00 00 00 00 00 00 00 00 08
			15 01 00 00 00 00 02 6F D8
			39 01 00 00 00 00 19 CD 00 00 00 00 00 00 00 00 00 00 00 10 00 00 00 00 00 00 00 00 00 00 00 10
			15 01 00 00 00 00 02 6F F0
			39 01 00 00 00 00 0D CD 00 00 00 00 00 00 00 00 00 00 00 10
			39 01 00 00 00 00 19 CE 00 00 00 00 00 00 00 00 00 00 00 18 00 00 00 00 00 00 00 00 00 00 00 00
			15 01 00 00 00 00 02 6F 18
			39 01 00 00 00 00 19 CE 00 00 00 00 00 00 00 00 00 00 00 00 00 00 00 00 00 00 00 00 00 00 00 00
			15 01 00 00 00 00 02 6F 30
			39 01 00 00 00 00 19 CE 00 00 00 00 00 00 00 00 00 00 00 00 00 00 00 00 00 00 00 00 00 00 00 00
			15 01 00 00 00 00 02 6F 48
			39 01 00 00 00 00 19 CE 00 00 00 00 00 00 00 00 00 00 00 00 00 00 00 00 00 00 00 00 00 00 00 00
			15 01 00 00 00 00 02 6F 60
			39 01 00 00 00 00 19 CE 00 00 00 00 00 00 00 00 00 00 00 00 00 00 00 00 00 00 00 00 00 00 00 00
			15 01 00 00 00 00 02 6F 78
			39 01 00 00 00 00 19 CE 00 00 00 00 00 00 00 00 00 00 00 00 00 00 00 00 00 00 00 00 00 00 00 00
			15 01 00 00 00 00 02 6F 90
			39 01 00 00 00 00 19 CE 00 00 00 00 00 00 00 00 00 00 00 00 00 00 00 00 00 00 00 00 00 00 00 00
			15 01 00 00 00 00 02 6F A8
			39 01 00 00 00 00 19 CE 00 00 00 00 00 00 00 00 00 00 00 00 00 00 00 00 00 00 00 00 00 00 00 00
			15 01 00 00 00 00 02 6F C0
			39 01 00 00 00 00 19 CE 00 00 00 00 00 00 00 00 00 00 00 00 00 00 00 00 00 00 00 00 00 00 00 00
			15 01 00 00 00 00 02 6F D8
			39 01 00 00 00 00 19 CE 00 00 00 00 00 00 00 00 00 00 00 00 00 00 00 00 00 00 00 00 00 00 00 00
			15 01 00 00 00 00 02 6F F0
			39 01 00 00 00 00 0D CE 00 00 00 00 00 00 00 00 00 00 00 00
			39 01 00 00 00 00 19 CF 00 00 00 00 00 00 00 00 00 00 00 00 00 00 00 00 00 00 00 00 00 00 00 00
			15 01 00 00 00 00 02 6F 18
			39 01 00 00 00 00 19 CF 00 00 00 00 00 00 00 00 00 00 00 00 00 00 00 00 00 00 00 00 00 00 00 00
			15 01 00 00 00 00 02 6F 30
			39 01 00 00 00 00 19 CF 00 00 00 00 00 00 00 00 00 00 00 00 00 00 00 00 00 00 00 00 00 00 00 00
			15 01 00 00 00 00 02 6F 48
			39 01 00 00 00 00 19 CF 00 00 00 00 00 00 00 00 00 00 00 00 00 00 00 00 00 00 00 00 00 00 00 00
			15 01 00 00 00 00 02 6F 60
			39 01 00 00 00 00 19 CF 00 00 00 00 00 00 00 00 00 00 00 00 00 00 00 00 00 00 00 00 00 00 00 00
			15 01 00 00 00 00 02 6F 78
			39 01 00 00 00 00 19 CF 00 00 00 00 00 00 00 00 00 00 00 00 00 00 00 00 00 00 00 00 00 00 00 00
			15 01 00 00 00 00 02 6F 90
			39 01 00 00 00 00 19 CF 00 00 00 00 00 00 00 00 00 00 00 00 00 00 00 00 00 00 00 00 00 00 00 00
			15 01 00 00 00 00 02 6F A8
			39 01 00 00 00 00 19 CF 00 00 00 00 00 00 00 00 00 00 00 00 00 00 00 00 00 00 00 00 00 00 00 00
			15 01 00 00 00 00 02 6F C0
			39 01 00 00 00 00 19 CF 00 00 00 00 00 00 00 00 00 00 00 00 00 00 00 00 00 00 00 00 00 00 00 00
			15 01 00 00 00 00 02 6F D8
			39 01 00 00 00 00 19 CF 00 00 00 00 00 00 00 00 00 00 00 00 00 00 00 00 00 00 00 00 00 00 00 00
			15 01 00 00 00 00 02 6F F0
			39 01 00 00 00 00 0D CF 00 00 00 00 00 00 00 00 00 00 00 00
			39 01 00 00 00 00 19 D0 00 00 00 00 00 00 00 00 00 00 00 00 00 00 00 00 00 00 00 00 00 00 00 00
			15 01 00 00 00 00 02 6F 18
			39 01 00 00 00 00 19 D0 00 00 00 00 00 00 00 00 00 00 00 00 00 00 00 00 00 00 00 00 00 00 00 00
			15 01 00 00 00 00 02 6F 30
			39 01 00 00 00 00 19 D0 00 00 00 00 00 00 00 00 00 00 00 00 00 00 00 00 00 00 00 00 00 00 00 00
			15 01 00 00 00 00 02 6F 48
			39 01 00 00 00 00 19 D0 00 00 00 00 00 00 00 00 00 00 00 00 00 00 00 00 00 00 00 00 00 00 00 00
			15 01 00 00 00 00 02 6F 60
			39 01 00 00 00 00 19 D0 00 00 00 00 00 00 00 00 00 00 00 00 00 00 00 00 00 00 00 00 00 00 00 00
			15 01 00 00 00 00 02 6F 78
			39 01 00 00 00 00 19 D0 00 00 00 00 00 00 00 00 00 00 00 00 00 00 00 00 00 00 00 00 00 00 00 00
			15 01 00 00 00 00 02 6F 90
			39 01 00 00 00 00 19 D0 00 00 00 00 00 00 00 00 00 00 00 00 00 00 00 00 00 00 00 00 00 00 00 00
			15 01 00 00 00 00 02 6F A8
			39 01 00 00 00 00 19 D0 00 00 00 00 00 00 00 00 00 00 00 00 00 00 00 00 00 00 00 00 00 00 00 00
			15 01 00 00 00 00 02 6F C0
			39 01 00 00 00 00 19 D0 00 00 00 00 00 00 00 00 00 00 00 00 00 00 00 00 00 00 00 00 00 00 00 00
			15 01 00 00 00 00 02 6F D8
			39 01 00 00 00 00 19 D0 00 00 00 00 00 00 00 00 00 00 00 00 00 00 00 00 00 00 00 00 00 00 00 00
			15 01 00 00 00 00 02 6F F0
			39 01 00 00 00 00 0D D0 00 00 00 00 00 00 00 00 00 00 00 00
			39 01 00 00 00 00 19 D1 00 00 00 00 00 00 00 00 00 00 00 00 00 00 00 00 00 00 00 00 00 00 00 00
			15 01 00 00 00 00 02 6F 18
			39 01 00 00 00 00 19 D1 00 00 00 00 00 00 00 00 00 00 00 00 00 00 00 00 00 00 00 00 00 00 00 00
			15 01 00 00 00 00 02 6F 30
			39 01 00 00 00 00 19 D1 00 00 00 00 00 00 00 00 00 00 00 00 00 00 00 00 00 00 00 00 00 00 00 00
			15 01 00 00 00 00 02 6F 48
			39 01 00 00 00 00 19 D1 00 00 00 00 00 00 00 00 00 00 00 00 00 00 00 00 00 00 00 00 00 00 00 00
			15 01 00 00 00 00 02 6F 60
			39 01 00 00 00 00 19 D1 00 00 00 00 00 00 00 00 00 00 00 00 00 00 00 00 00 00 00 00 00 00 00 00
			15 01 00 00 00 00 02 6F 78
			39 01 00 00 00 00 19 D1 00 00 00 00 00 00 00 00 00 00 00 00 00 00 00 00 00 00 00 00 00 00 00 00
			15 01 00 00 00 00 02 6F 90
			39 01 00 00 00 00 19 D1 00 00 00 00 00 00 00 00 00 00 00 00 00 00 00 00 00 00 00 00 00 00 00 00
			15 01 00 00 00 00 02 6F A8
			39 01 00 00 00 00 19 D1 00 00 00 00 00 00 00 00 00 00 00 00 00 00 00 00 00 00 00 00 00 00 00 00
			15 01 00 00 00 00 02 6F C0
			39 01 00 00 00 00 19 D1 00 00 00 00 00 00 00 00 00 00 00 00 00 00 00 00 00 00 00 00 00 00 00 00
			15 01 00 00 00 00 02 6F D8
			39 01 00 00 00 00 19 D1 00 00 00 00 00 00 00 00 00 00 00 00 00 00 00 00 00 00 00 00 00 00 00 00
			15 01 00 00 00 00 02 6F F0
			39 01 00 00 00 00 0D D1 00 00 00 00 00 00 00 00 00 00 00 00
			39 01 00 00 00 00 19 D2 00 00 00 00 00 00 00 00 00 00 00 00 00 00 00 00 00 00 00 00 00 00 00 00
			15 01 00 00 00 00 02 6F 18
			39 01 00 00 00 00 19 D2 00 00 00 00 00 00 00 00 00 00 00 00 00 00 00 00 00 00 00 00 00 00 00 00
			15 01 00 00 00 00 02 6F 30
			39 01 00 00 00 00 19 D2 00 00 00 00 00 00 00 00 00 00 00 00 00 00 00 00 00 00 00 00 00 00 00 00
			15 01 00 00 00 00 02 6F 48
			39 01 00 00 00 00 19 D2 00 00 00 00 00 00 00 00 00 00 00 00 00 00 00 00 00 00 00 00 00 00 00 00
			15 01 00 00 00 00 02 6F 60
			39 01 00 00 00 00 19 D2 00 00 00 00 00 00 00 00 00 00 00 00 00 00 00 00 00 00 00 00 00 00 00 00
			15 01 00 00 00 00 02 6F 78
			39 01 00 00 00 00 19 D2 00 00 00 00 00 00 00 00 00 00 00 00 00 00 00 00 00 00 00 00 00 00 00 00
			15 01 00 00 00 00 02 6F 90
			39 01 00 00 00 00 19 D2 00 00 00 00 00 00 00 00 00 00 00 00 00 00 00 00 00 00 00 00 00 00 00 00
			15 01 00 00 00 00 02 6F A8
			39 01 00 00 00 00 19 D2 00 00 00 00 00 00 00 00 00 00 00 00 00 00 00 00 00 00 00 00 00 00 00 00
			15 01 00 00 00 00 02 6F C0
			39 01 00 00 00 00 19 D2 00 00 00 00 00 00 00 00 00 00 00 00 00 00 00 00 00 00 00 00 00 00 00 00
			15 01 00 00 00 00 02 6F D8
			39 01 00 00 00 00 19 D2 00 00 00 00 00 00 00 00 00 00 00 00 00 00 00 00 00 00 00 00 00 00 00 00
			15 01 00 00 00 00 02 6F F0
			39 01 00 00 00 00 0D D2 00 00 00 00 00 00 00 00 00 00 00 00

			15 01 00 00 00 00 02 B0 00
			39 01 00 00 00 00 19 D5 80 00 48 00 FF FF FF FF 00 00 00 00 00 00 00 00 00 00 00 00 00 00 00 00
			15 01 00 00 00 00 02 6F 18
			39 01 00 00 00 00 19 D5 00 00 00 00 00 00 00 00 00 0B 5E 00 0B 5E 00 0B 5E 00 0B 5E 00 0B 5E 00
			15 01 00 00 00 00 02 6F 30
			39 01 00 00 00 00 19 D5 0B 5E 00 0B 5E 00 0B 5E 00 69 3C 00 00 00 00 08 61 00 0B 5E 00 0B 5E 00
			15 01 00 00 00 00 02 6F 48
			39 01 00 00 00 00 19 D5 0B 5E 00 0B 5E 00 0B 5E 00 0B 5E 00 0B 5E 00 0B 5E 00 3C 00 08 61 46 64

			39 01 00 00 00 00 19 D6 55 55 55 55 55 55 55 55 55 55 55 55 55 55 55 55 55 55 55 55 55 55 55 55
			15 01 00 00 00 00 02 6F 18
			39 01 00 00 00 00 19 D6 55 55 55 55 55 55 55 55 55 55 55 55 55 55 55 55 55 55 55 55 55 55 55 55
			15 01 00 00 00 00 02 6F 30
			39 01 00 00 00 00 19 D6 55 55 55 55 55 55 55 55 55 55 55 55 55 55 55 55 80 80 80 00 00 00 FF FF
			15 01 00 00 00 00 02 6F 48
			39 01 00 00 00 00 19 D6 FF 45 45 45 45 45 45 45 45 45 45 45 45 45 45 45 45 45 45 45 45 45 00 00
			15 01 00 00 00 00 02 6F 60
			39 01 00 00 00 00 19 D6 00 3C 3C 3C 33 33 33 2B 2B 2B 22 22 22 19 19 19 11 11 11 08 08 08 00 00
			15 01 00 00 00 00 02 6F 78
			39 01 00 00 00 00 19 D6 00 00 00 00 00 00 00 00 00 00 00 00 00 00 00 00 00 00 00 00 00 00 00 00
			15 01 00 00 00 00 02 6F 90
			15 01 00 00 00 00 02 D6 00
			39 01 00 00 00 00 19 D7 55 55 55 55 55 55 55 55 55 55 55 55 55 55 55 55 54 54 00 00 54 54 00 00
			15 01 00 00 00 00 02 6F 18
			39 01 00 00 00 00 19 D7 54 54 AA AA 54 54 00 80 15 55 15 45 55 05 05 05 50 50 50 50 50 50 50 50
			15 01 00 00 00 00 02 6F 30
			39 01 00 00 00 00 19 D7 00 00 55 55 00 00 55 55 55 55 00 00 55 55 00 00 00 00 00 00 00 00 00 00
			15 01 00 00 00 00 02 6F 48
			39 01 00 00 00 00 19 D7 00 00 00 00 00 00 00 00 00 00 00 00 00 00 00 00 00 00 00 00 00 00 00 00
			15 01 00 00 00 00 02 6F 60
			39 01 00 00 00 00 19 D7 00 00 00 00 00 00 00 00 00 00 00 00 00 00 00 00 00 00 00 00 00 00 00 00
			15 01 00 00 00 00 02 6F 78
			39 01 00 00 00 00 09 D7 00 00 00 00 00 00 00 00
			39 01 00 00 00 00 19 D8 BD FF FD FF FD FF F7 FF F7 FF F7 FF FF FF FF FF FF FF 00 00 00 E6 E6 E6
			15 01 00 00 00 00 02 6F 18
			39 01 00 00 00 00 19 D8 00 00 00 00 00 00 00 00 00 00 00 00 F9 00 00 00 00 00 00 00 00 00 00 00
			15 01 00 00 00 00 02 6F 30
			39 01 00 00 00 00 19 D8 00 00 00 00 00 00 00 00 00 00 00 00 00 00 00 00 00 00 00 00 00 00 00 00
			15 01 00 00 00 00 02 6F 48
			39 01 00 00 00 00 19 D8 00 00 00 FF FF FF 00 00 00 00 00 00 00 00 00 00 00 00 00 00 00 00 00 00
			15 01 00 00 00 00 02 6F 60
			39 01 00 00 00 00 19 D8 00 00 00 00 00 00 00 00 00 00 00 00 00 00 00 00 00 00 00 00 00 00 00 00
			15 01 00 00 00 00 02 6F 78
			39 01 00 00 00 00 19 D8 00 00 00 00 00 00 00 00 00 00 00 00 00 00 00 00 00 00 00 00 00 00 00 00
			15 01 00 00 00 00 02 6F 90
			39 01 00 00 00 00 13 D8 00 00 00 00 00 00 00 00 00 00 00 00 00 00 00 00 00 00
			39 01 00 00 00 00 19 D9 FC 00 8A AA 1A AA AA 98 AA AA 9A AA AA 9A A8 AA AA 06 AA AA 62 AA 8A 8A
			15 01 00 00 00 00 02 6F 18
			39 01 00 00 00 00 19 D9 9A 9A 8A 8A 00 00 00 00 00 00 00 00 00 00 00 00 00 00 00 00 00 00 00 00
			15 01 00 00 00 00 02 6F 30
			39 01 00 00 00 00 09 D9 00 00 00 00 00 00 00 00

			//SPR setting for L area
			39 01 00 00 00 00 06 F0 55 AA 52 08 07
			15 01 00 00 00 00 02 BE 90
			15 01 00 00 00 00 02 6F 03
			39 01 00 00 00 00 07 BE 22 22 22 00 00 00
			15 01 00 00 00 00 02 6F 09
			39 01 00 00 00 00 0D BE 05 05 03 04 03 05 04 04 04 04 04 04

			15 01 00 00 00 00 02 90 01
			39 01 00 00 00 00 13 91 AB 28 00 0C C2 00 03 1C 01 7E 00 0F 08 BB 04 3D 10 F0
			15 01 00 00 00 00 02 03 01
			15 01 00 00 00 00 02 2C 00
			39 01 00 00 00 00 03 51 00 00
			15 01 00 00 00 00 02 53 20
			15 01 00 00 00 00 02 35 00
			39 01 00 00 00 00 05 2A 00 00 04 37
			39 01 00 00 00 00 05 2B 00 00 09 5F
			39 01 00 00 00 00 06 F0 55 AA 52 08 02
			15 01 00 00 00 00 02 6F 03
			15 01 00 00 00 00 02 BF 05
			15 01 00 00 00 00 02 2F 02
			05 01 00 00 78 00 01 11
			05 01 00 00 00 00 01 29];	/* display on */
		qcom,mdss-dsi-off-command = [
			05 01 00 00 00 00 01 28		/* display_off */
			05 01 00 00 78 00 01 10];	/* enter sleep mode */

		qcom,mdss-dsi-on-command-state = "dsi_lp_mode";
		qcom,mdss-dsi-off-command-state = "dsi_lp_mode";
		qcom,mdss-dsi-timing-switch-command-state = "dsi_lp_mode";

		qcom,compression-mode = "dsc";
		qcom,mdss-dsc-version = <0x11>;
		qcom,mdss-dsc-slice-height = <12>;
		qcom,mdss-dsc-slice-width = <1080>;
		qcom,mdss-dsc-slice-per-pkt = <1>;
		qcom,mdss-dsc-bit-per-component = <10>;
		qcom,mdss-dsc-bit-per-pixel = <10>;
		qcom,mdss-dsc-block-prediction-enable;
	};

	timing@2{
		/* 120 FPS */
		qcom,mdss-dsi-cmd-mode;
		qcom,mdss-dsi-panel-framerate = <120>;
		qcom,mdss-dsi-panel-width = <1080>;
		qcom,mdss-dsi-panel-height = <2400>;
		qcom,mdss-dsi-h-front-porch = <36>;
		qcom,mdss-dsi-h-back-porch = <36>;
		qcom,mdss-dsi-h-pulse-width = <4>;
		qcom,mdss-dsi-h-sync-skew = <0>;
		qcom,mdss-dsi-h-sync-pulse = <0>;
		qcom,mdss-dsi-v-back-porch = <4>;
		qcom,mdss-dsi-v-front-porch = <12>;
		qcom,mdss-dsi-v-pulse-width = <4>;
		qcom,mdss-dsi-h-left-border = <0>;
		qcom,mdss-dsi-h-right-border = <0>;
		qcom,mdss-dsi-v-top-border = <0>;
		qcom,mdss-dsi-v-bottom-border = <0>;
		qcom,mdss-dsi-panel-jitter = <0x20 0xa>;
		qcom,mdss-dsi-panel-clockrate = <1099800000>;
		qcom,mdss-dsi-timing-switch-command = [
			39 01 00 00 00 00 06 F0 55 AA 52 08 02
			15 01 00 00 00 00 02 6F 03
			15 01 00 00 00 00 02 BF 03
			15 01 00 00 08 00 02 2F 03
		];
		qcom,mdss-dsi-on-command = [
			39 01 00 00 00 00 06 F0 55 AA 52 08 00
			15 01 00 00 00 00 02 6F 06
			39 01 00 00 00 00 04 B5 4E 19 50
			15 01 00 00 00 00 02 6F 0D
			15 01 00 00 00 00 02 B5 50
			15 01 00 00 00 00 02 6F 10
			39 01 00 00 00 00 06 B5 19 19 19 19 19

			//CUP enable
			15 01 00 00 00 00 02 99 10

			39 01 00 00 00 00 06 F0 55 AA 52 08 09
			//39 01 00 00 00 00 19 B0 00
			15 01 00 00 00 00 02 B0 01
			39 01 00 00 00 00 19 B1 00 00 00 00 00 00 00 00 00 00 00 00 00 00 00 00 00 00 00 00 00 00 00 00
			15 01 00 00 00 00 02 6F 18
			39 01 00 00 00 00 19 B1 00 00 00 00 00 00 00 00 00 00 00 00 00 00 00 00 00 00 00 00 00 00 00 00
			15 01 00 00 00 00 02 6F 30
			39 01 00 00 00 00 19 B1 00 00 00 00 00 00 00 00 00 00 00 00 00 00 00 00 00 00 00 00 00 00 00 00
			15 01 00 00 00 00 02 6F 48
			39 01 00 00 00 00 19 B1 00 00 00 00 00 00 00 00 00 00 00 00 00 00 00 00 00 00 00 00 00 00 00 00
			15 01 00 00 00 00 02 6F 60
			39 01 00 00 00 00 19 B1 00 00 00 00 00 00 00 00 00 00 00 00 00 00 00 00 00 00 00 00 00 00 00 00
			15 01 00 00 00 00 02 6F 78
			39 01 00 00 00 00 19 B1 00 00 00 00 00 00 00 00 00 00 00 00 00 00 00 00 00 00 00 00 00 00 00 00
			15 01 00 00 00 00 02 6F 90
			39 01 00 00 00 00 19 B1 00 00 00 00 00 00 00 00 00 00 00 00 00 00 00 00 00 00 00 00 00 00 00 00
			15 01 00 00 00 00 02 6F A8
			39 01 00 00 00 00 19 B1 00 00 00 00 00 00 00 00 00 00 00 00 00 00 00 00 00 00 00 00 00 00 00 00
			15 01 00 00 00 00 02 6F C0
			39 01 00 00 00 00 19 B1 00 00 00 00 00 00 00 00 00 00 00 00 00 00 00 00 00 00 00 00 00 00 00 00
			15 01 00 00 00 00 02 6F D8
			39 01 00 00 00 00 19 B1 00 00 00 00 00 00 00 00 00 00 00 00 00 00 00 00 00 00 00 00 00 00 00 00
			15 01 00 00 00 00 02 6F F0
			39 01 00 00 00 00 0D B1 00 00 00 00 00 00 00 00 00 00 00 00
			39 01 00 00 00 00 19 B2 00 00 00 00 00 00 00 00 00 00 00 00 00 00 00 00 00 00 00 00 00 00 00 00
			15 01 00 00 00 00 02 6F 18
			39 01 00 00 00 00 19 B2 00 00 00 00 00 00 00 00 00 00 00 00 00 00 00 00 00 00 00 00 00 00 00 00
			15 01 00 00 00 00 02 6F 30
			39 01 00 00 00 00 19 B2 00 00 00 00 00 00 00 00 00 00 00 00 00 00 00 00 00 00 00 00 00 00 00 00
			15 01 00 00 00 00 02 6F 48
			39 01 00 00 00 00 19 B2 00 00 00 00 00 00 00 00 00 00 00 00 00 00 00 00 00 00 00 00 00 00 00 00
			15 01 00 00 00 00 02 6F 60
			39 01 00 00 00 00 19 B2 00 00 00 00 00 00 00 00 00 00 00 00 00 00 00 00 00 00 00 00 00 00 00 00
			15 01 00 00 00 00 02 6F 78
			39 01 00 00 00 00 19 B2 00 00 00 00 00 00 00 00 00 00 00 00 00 00 00 00 00 00 00 00 00 00 00 00
			15 01 00 00 00 00 02 6F 90
			39 01 00 00 00 00 19 B2 00 00 00 00 00 00 00 00 00 00 00 00 00 00 00 00 00 00 00 00 00 00 00 00
			15 01 00 00 00 00 02 6F A8
			39 01 00 00 00 00 19 B2 00 00 00 00 00 00 00 00 00 00 00 00 00 00 00 00 00 00 00 00 00 00 00 00
			15 01 00 00 00 00 02 6F C0
			39 01 00 00 00 00 19 B2 00 00 00 00 00 00 00 00 00 00 00 00 00 00 00 00 00 00 00 00 00 00 00 00
			15 01 00 00 00 00 02 6F D8
			39 01 00 00 00 00 19 B2 00 00 00 00 00 00 00 00 00 00 00 00 00 00 00 00 00 00 00 00 00 00 00 00
			15 01 00 00 00 00 02 6F F0
			39 01 00 00 00 00 0D B2 00 00 00 00 00 00 00 00 00 00 00 00
			39 01 00 00 00 00 19 B3 00 00 00 00 00 00 00 00 00 00 00 00 00 00 00 00 00 00 00 00 00 00 00 00
			15 01 00 00 00 00 02 6F 18
			39 01 00 00 00 00 19 B3 00 00 00 00 00 00 00 00 00 00 00 00 00 00 00 00 00 00 00 00 00 00 00 00
			15 01 00 00 00 00 02 6F 30
			39 01 00 00 00 00 19 B3 00 00 00 00 00 00 00 00 00 00 00 00 00 00 00 00 00 00 00 00 00 00 00 00
			15 01 00 00 00 00 02 6F 48
			39 01 00 00 00 00 19 B3 00 00 00 00 00 00 00 00 00 00 00 00 00 00 00 00 00 00 00 00 00 00 00 00
			15 01 00 00 00 00 02 6F 60
			39 01 00 00 00 00 19 B3 00 00 00 00 00 00 00 00 00 00 00 00 00 00 00 00 00 00 00 00 00 00 00 00
			15 01 00 00 00 00 02 6F 78
			39 01 00 00 00 00 19 B3 00 00 00 00 00 00 00 00 00 00 00 00 00 00 00 00 00 00 00 00 00 00 00 00
			15 01 00 00 00 00 02 6F 90
			39 01 00 00 00 00 19 B3 00 00 00 00 00 00 00 00 00 00 00 00 00 00 00 00 00 00 00 00 00 00 00 00
			15 01 00 00 00 00 02 6F A8
			39 01 00 00 00 00 19 B3 00 00 00 00 00 00 00 00 00 00 00 00 00 00 00 00 00 00 00 00 00 00 00 00
			15 01 00 00 00 00 02 6F C0
			39 01 00 00 00 00 19 B3 00 00 00 00 00 00 00 00 00 00 00 00 00 00 00 00 00 00 00 00 00 00 00 00
			15 01 00 00 00 00 02 6F D8
			39 01 00 00 00 00 19 B3 00 00 00 00 00 00 00 00 00 00 00 00 00 00 00 00 00 00 00 00 00 00 00 00
			15 01 00 00 00 00 02 6F F0
			39 01 00 00 00 00 0D B3 00 00 00 00 00 00 00 00 00 00 00 00
			39 01 00 00 00 00 19 B4 00 00 00 00 00 00 00 00 00 00 00 00 00 00 00 00 00 00 00 00 00 00 00 00
			15 01 00 00 00 00 02 6F 18
			39 01 00 00 00 00 19 B4 00 00 00 00 00 00 00 00 00 00 00 00 00 00 00 00 00 00 00 00 00 00 00 00
			15 01 00 00 00 00 02 6F 30
			39 01 00 00 00 00 19 B4 00 00 00 00 00 00 00 00 00 00 00 00 00 00 00 00 00 00 00 00 00 00 00 00
			15 01 00 00 00 00 02 6F 48
			39 01 00 00 00 00 19 B4 00 00 00 00 00 00 00 00 00 00 00 00 00 00 00 00 00 00 00 00 00 00 00 00
			15 01 00 00 00 00 02 6F 60
			39 01 00 00 00 00 19 B4 00 00 00 00 00 00 00 00 00 00 00 00 00 00 00 00 00 00 00 00 00 00 00 00
			15 01 00 00 00 00 02 6F 78
			39 01 00 00 00 00 19 B4 00 00 00 00 00 00 00 00 00 00 00 00 00 00 00 00 00 00 00 00 00 00 00 00
			15 01 00 00 00 00 02 6F 90
			39 01 00 00 00 00 19 B4 00 00 00 00 00 00 00 00 00 00 00 00 00 00 00 00 00 00 00 00 00 00 00 00
			15 01 00 00 00 00 02 6F A8
			39 01 00 00 00 00 19 B4 00 00 00 00 00 00 00 00 00 00 00 00 00 00 00 00 00 00 00 00 00 00 00 00
			15 01 00 00 00 00 02 6F C0
			39 01 00 00 00 00 19 B4 00 00 00 00 00 00 00 00 00 00 00 00 00 00 00 00 00 00 00 00 00 00 00 00
			15 01 00 00 00 00 02 6F D8
			39 01 00 00 00 00 19 B4 00 00 00 00 00 00 00 00 00 00 00 00 00 00 00 00 00 00 00 00 00 00 00 00
			15 01 00 00 00 00 02 6F F0
			39 01 00 00 00 00 0D B4 00 00 00 00 00 00 00 00 00 00 00 00
			39 01 00 00 00 00 19 B5 00 00 00 00 00 00 00 00 00 00 00 00 00 00 00 00 00 00 00 00 00 00 00 00
			15 01 00 00 00 00 02 6F 18
			39 01 00 00 00 00 19 B5 00 00 00 00 00 00 00 00 00 00 00 00 00 00 00 00 00 00 00 00 00 00 00 00
			15 01 00 00 00 00 02 6F 30
			39 01 00 00 00 00 19 B5 00 00 00 00 00 00 00 00 00 00 00 00 00 00 00 00 00 00 00 00 00 00 00 00
			15 01 00 00 00 00 02 6F 48
			39 01 00 00 00 00 19 B5 00 00 00 00 00 00 00 00 00 00 00 00 00 00 00 00 00 00 00 00 00 00 00 00
			15 01 00 00 00 00 02 6F 60
			39 01 00 00 00 00 19 B5 00 00 00 00 00 00 00 00 00 00 00 00 00 00 00 00 00 00 00 00 00 00 00 00
			15 01 00 00 00 00 02 6F 78
			39 01 00 00 00 00 19 B5 00 00 00 00 00 00 00 00 00 00 00 00 00 00 00 00 00 00 00 00 00 00 00 00
			15 01 00 00 00 00 02 6F 90
			39 01 00 00 00 00 19 B5 00 00 00 00 00 00 00 00 00 00 00 00 00 00 00 00 00 00 00 00 00 00 00 00
			15 01 00 00 00 00 02 6F A8
			39 01 00 00 00 00 19 B5 00 00 00 00 00 00 00 00 00 00 00 00 00 00 00 00 00 00 00 00 00 00 00 00
			15 01 00 00 00 00 02 6F C0
			39 01 00 00 00 00 19 B5 00 00 00 00 00 00 00 00 00 00 00 00 00 00 00 00 00 00 00 00 00 00 00 00
			15 01 00 00 00 00 02 6F D8
			39 01 00 00 00 00 19 B5 00 00 00 00 00 00 00 00 00 00 00 00 00 00 00 00 00 00 00 00 00 00 00 00
			15 01 00 00 00 00 02 6F F0
			39 01 00 00 00 00 0D B5 00 00 00 00 00 00 00 00 00 00 00 00
			39 01 00 00 00 00 19 B6 00 00 00 00 00 00 00 00 00 00 00 00 00 00 00 00 00 00 00 00 00 00 00 00
			15 01 00 00 00 00 02 6F 18
			39 01 00 00 00 00 19 B6 00 00 00 00 00 00 00 00 00 00 00 00 00 00 00 00 00 00 00 00 00 00 00 00
			15 01 00 00 00 00 02 6F 30
			39 01 00 00 00 00 19 B6 00 00 00 00 00 00 00 00 00 00 00 00 00 00 00 00 00 00 00 00 00 00 00 00
			15 01 00 00 00 00 02 6F 48
			39 01 00 00 00 00 19 B6 00 00 00 00 00 00 00 00 00 00 00 00 00 00 00 00 00 00 00 00 00 00 00 00
			15 01 00 00 00 00 02 6F 60
			39 01 00 00 00 00 19 B6 00 00 00 00 00 00 00 00 00 00 00 00 00 00 00 00 00 00 00 00 00 00 00 00
			15 01 00 00 00 00 02 6F 78
			39 01 00 00 00 00 19 B6 00 00 00 00 00 00 00 00 00 00 00 00 00 00 00 00 00 00 00 00 00 00 00 00
			15 01 00 00 00 00 02 6F 90
			39 01 00 00 00 00 19 B6 00 00 00 00 00 00 00 00 00 00 00 00 00 00 00 00 00 00 00 00 00 00 00 00
			15 01 00 00 00 00 02 6F A8
			39 01 00 00 00 00 19 B6 00 00 00 00 00 00 00 00 00 00 00 00 00 00 00 00 00 00 00 00 00 00 00 00
			15 01 00 00 00 00 02 6F C0
			39 01 00 00 00 00 19 B6 00 00 00 00 00 00 00 00 00 00 00 00 00 00 00 00 00 00 00 00 00 00 00 00
			15 01 00 00 00 00 02 6F D8
			39 01 00 00 00 00 19 B6 00 00 00 00 00 00 00 00 00 00 00 00 00 00 00 00 00 00 00 00 00 00 00 00
			15 01 00 00 00 00 02 6F F0
			39 01 00 00 00 00 0D B6 00 00 00 00 00 00 00 00 00 00 00 00
			39 01 00 00 00 00 19 B7 00 00 00 00 00 00 00 00 00 00 00 00 00 00 00 00 00 00 00 00 00 00 00 00
			15 01 00 00 00 00 02 6F 18
			39 01 00 00 00 00 19 B7 00 00 00 00 00 00 00 00 00 00 00 00 00 00 00 00 00 00 00 00 00 00 00 00
			15 01 00 00 00 00 02 6F 30
			39 01 00 00 00 00 19 B7 00 00 00 00 00 00 00 00 00 00 00 00 00 00 00 00 00 00 00 00 00 00 00 00
			15 01 00 00 00 00 02 6F 48
			39 01 00 00 00 00 19 B7 00 00 00 00 00 00 00 00 00 00 00 00 00 00 00 00 00 00 00 00 00 00 00 00
			15 01 00 00 00 00 02 6F 60
			39 01 00 00 00 00 19 B7 00 00 00 00 00 00 00 00 00 00 00 00 00 00 00 00 00 00 00 00 00 00 00 00
			15 01 00 00 00 00 02 6F 78
			39 01 00 00 00 00 19 B7 00 00 00 00 00 00 00 00 00 00 00 00 00 00 00 00 00 00 00 00 00 00 00 00
			15 01 00 00 00 00 02 6F 90
			39 01 00 00 00 00 19 B7 00 00 00 00 00 00 00 00 00 00 00 00 00 00 00 00 00 00 00 00 00 00 00 00
			15 01 00 00 00 00 02 6F A8
			39 01 00 00 00 00 19 B7 00 00 00 00 00 00 00 00 00 00 00 00 00 00 00 00 00 00 00 00 00 00 00 00
			15 01 00 00 00 00 02 6F C0
			39 01 00 00 00 00 19 B7 00 00 00 00 00 00 00 00 00 00 00 00 00 00 00 00 00 00 00 00 00 00 00 00
			15 01 00 00 00 00 02 6F D8
			39 01 00 00 00 00 19 B7 00 00 00 00 00 00 00 00 00 00 00 00 00 00 00 00 00 00 00 00 00 00 00 00
			15 01 00 00 00 00 02 6F F0
			39 01 00 00 00 00 0D B7 00 00 00 00 00 00 00 00 00 00 00 00

			39 01 00 00 00 00 19 BA 00 00 00 00 00 00 00 00 00 00 00 00 00 00 00 00 00 00 00 00 00 00 00 00
			15 01 00 00 00 00 02 6F 18
			39 01 00 00 00 00 19 BA 00 00 00 00 00 00 00 00 00 00 00 00 00 00 00 00 00 00 00 00 00 00 00 00
			15 01 00 00 00 00 02 6F 30
			39 01 00 00 00 00 19 BA 00 00 00 00 00 00 00 00 00 00 00 00 00 00 00 00 00 00 00 00 00 00 00 00
			15 01 00 00 00 00 02 6F 48
			39 01 00 00 00 00 19 BA 00 00 00 00 00 00 00 00 00 00 00 00 00 00 00 00 00 00 00 00 00 00 00 00
			15 01 00 00 00 00 02 6F 60
			39 01 00 00 00 00 19 BA 00 00 00 00 00 00 00 00 00 00 00 00 00 00 00 00 00 00 00 00 00 00 00 00
			15 01 00 00 00 00 02 6F 78
			39 01 00 00 00 00 19 BA 00 00 00 00 00 00 00 00 00 00 00 00 00 00 00 00 00 00 00 00 00 00 00 00
			15 01 00 00 00 00 02 6F 90
			39 01 00 00 00 00 19 BA 00 00 00 00 00 00 00 00 00 00 00 00 00 00 00 00 00 00 00 00 00 00 00 00
			15 01 00 00 00 00 02 6F A8
			39 01 00 00 00 00 19 BA 00 00 00 00 00 00 00 00 00 00 00 00 00 00 00 00 00 00 00 00 00 00 00 00
			15 01 00 00 00 00 02 6F C0
			39 01 00 00 00 00 19 BA 00 00 00 00 00 00 00 00 00 00 00 00 00 00 00 00 00 00 00 00 00 00 00 00
			15 01 00 00 00 00 02 6F D8
			39 01 00 00 00 00 19 BA 00 00 00 00 00 00 00 00 00 00 00 00 00 00 00 00 00 00 00 00 00 00 00 00
			15 01 00 00 00 00 02 6F F0
			39 01 00 00 00 00 0D BA 00 00 00 00 00 00 00 00 00 00 00 00
			39 01 00 00 00 00 19 BB 00 00 00 00 00 00 00 00 00 00 00 00 00 00 00 00 00 00 00 00 00 00 00 00
			15 01 00 00 00 00 02 6F 18
			39 01 00 00 00 00 19 BB 00 00 00 00 00 00 00 00 00 00 00 00 00 00 00 00 00 00 00 00 00 00 00 00
			15 01 00 00 00 00 02 6F 30
			39 01 00 00 00 00 19 BB 00 00 00 00 00 00 00 00 00 00 00 00 00 00 00 00 00 00 00 00 00 00 00 00
			15 01 00 00 00 00 02 6F 48
			39 01 00 00 00 00 19 BB 00 00 00 00 00 00 00 00 00 00 00 00 00 00 00 00 00 00 00 00 00 00 00 00
			15 01 00 00 00 00 02 6F 60
			39 01 00 00 00 00 19 BB 00 00 00 00 00 00 00 00 00 00 00 00 00 00 00 00 00 00 00 00 00 00 00 00
			15 01 00 00 00 00 02 6F 78
			39 01 00 00 00 00 19 BB 00 00 00 00 00 00 00 00 00 00 00 00 00 00 00 00 00 00 00 00 00 00 00 00
			15 01 00 00 00 00 02 6F 90
			39 01 00 00 00 00 19 BB 00 00 00 00 00 00 00 00 00 00 00 00 00 00 00 00 00 00 00 00 00 00 00 00
			15 01 00 00 00 00 02 6F A8
			39 01 00 00 00 00 19 BB 00 00 00 00 00 00 00 00 00 00 00 00 00 00 00 00 00 00 00 00 00 00 00 00
			15 01 00 00 00 00 02 6F C0
			39 01 00 00 00 00 19 BB 00 00 00 00 00 00 00 00 00 00 00 00 00 00 00 00 00 00 00 00 00 00 00 00
			15 01 00 00 00 00 02 6F D8
			39 01 00 00 00 00 19 BB 00 00 00 00 00 00 00 00 00 00 00 00 00 00 00 00 00 00 00 00 00 00 00 00
			15 01 00 00 00 00 02 6F F0
			39 01 00 00 00 00 0D BB 00 00 00 00 00 00 00 00 00 00 00 00
			39 01 00 00 00 00 19 BC 00 00 00 00 00 00 00 00 00 00 00 00 00 00 00 00 00 00 00 00 00 00 00 00
			15 01 00 00 00 00 02 6F 18
			39 01 00 00 00 00 19 BC 00 00 00 00 00 00 00 00 00 00 00 00 00 00 00 00 00 00 00 00 00 00 00 00
			15 01 00 00 00 00 02 6F 30
			39 01 00 00 00 00 19 BC 00 00 00 00 00 00 00 00 00 00 00 00 00 00 00 00 00 00 00 00 00 00 00 00
			15 01 00 00 00 00 02 6F 48
			39 01 00 00 00 00 19 BC 00 00 00 00 00 00 00 00 00 00 00 00 00 00 00 00 00 00 00 00 00 00 00 00
			15 01 00 00 00 00 02 6F 60
			39 01 00 00 00 00 19 BC 00 00 00 00 00 00 00 00 00 00 00 00 00 00 00 00 00 00 00 00 00 00 00 00
			15 01 00 00 00 00 02 6F 78
			39 01 00 00 00 00 19 BC 00 00 00 00 00 00 00 00 00 00 00 00 00 00 00 00 00 00 00 00 00 00 00 00
			15 01 00 00 00 00 02 6F 90
			39 01 00 00 00 00 19 BC 00 00 00 00 00 00 00 00 00 00 00 00 00 00 00 00 00 00 00 00 00 00 00 00
			15 01 00 00 00 00 02 6F A8
			39 01 00 00 00 00 19 BC 00 00 00 00 00 00 00 00 00 00 00 00 00 00 00 00 00 00 00 00 00 00 00 00
			15 01 00 00 00 00 02 6F C0
			39 01 00 00 00 00 19 BC 00 00 00 00 00 00 00 00 00 00 00 00 00 00 00 00 00 00 00 00 00 00 00 00
			15 01 00 00 00 00 02 6F D8
			39 01 00 00 00 00 19 BC 00 00 00 00 00 00 00 00 00 00 00 00 00 00 00 00 00 00 00 00 00 00 00 00
			15 01 00 00 00 00 02 6F F0
			39 01 00 00 00 00 0D BC 00 00 00 00 00 00 00 00 00 00 00 00
			39 01 00 00 00 00 19 BD 00 00 00 00 00 00 00 00 00 00 00 00 00 00 00 00 00 00 00 00 00 00 00 00
			15 01 00 00 00 00 02 6F 18
			39 01 00 00 00 00 19 BD 00 00 00 00 00 00 00 00 00 00 00 00 00 00 00 00 00 00 00 00 00 00 00 00
			15 01 00 00 00 00 02 6F 30
			39 01 00 00 00 00 19 BD 00 00 00 00 00 00 00 00 00 00 00 00 00 00 00 00 00 00 00 00 00 00 00 00
			15 01 00 00 00 00 02 6F 48
			39 01 00 00 00 00 19 BD 00 00 00 00 00 00 00 00 00 00 00 00 00 00 00 00 00 00 00 00 00 00 00 00
			15 01 00 00 00 00 02 6F 60
			39 01 00 00 00 00 19 BD 00 00 00 00 00 00 00 00 00 00 00 00 00 00 00 00 00 00 00 00 00 00 00 00
			15 01 00 00 00 00 02 6F 78
			39 01 00 00 00 00 19 BD 00 00 00 00 00 00 00 00 00 00 00 00 00 00 00 00 00 00 00 00 00 00 00 00
			15 01 00 00 00 00 02 6F 90
			39 01 00 00 00 00 19 BD 00 00 00 00 00 00 00 00 00 00 00 00 00 00 00 00 00 00 00 00 00 00 00 00
			15 01 00 00 00 00 02 6F A8
			39 01 00 00 00 00 19 BD 00 00 00 00 00 00 00 00 00 00 00 00 00 00 00 00 00 00 00 00 00 00 00 00
			15 01 00 00 00 00 02 6F C0
			39 01 00 00 00 00 19 BD 00 00 00 00 00 00 00 00 00 00 00 00 00 00 00 00 00 00 00 00 00 00 00 00
			15 01 00 00 00 00 02 6F D8
			39 01 00 00 00 00 19 BD 00 00 00 00 00 00 00 00 00 00 00 00 00 00 00 00 00 00 00 00 00 00 00 00
			15 01 00 00 00 00 02 6F F0
			39 01 00 00 00 00 0D BD 00 00 00 00 00 00 00 00 00 00 00 00
			39 01 00 00 00 00 19 BE 00 00 00 00 00 00 00 00 00 00 00 00 00 00 00 00 00 00 00 00 00 00 00 00
			15 01 00 00 00 00 02 6F 18
			39 01 00 00 00 00 19 BE 00 00 00 00 00 00 00 00 00 00 00 00 00 00 00 00 00 00 00 00 00 00 00 00
			15 01 00 00 00 00 02 6F 30
			39 01 00 00 00 00 19 BE 00 00 00 00 00 00 00 00 00 00 00 00 00 00 00 00 00 00 00 00 00 00 00 00
			15 01 00 00 00 00 02 6F 48
			39 01 00 00 00 00 19 BE 00 00 00 00 00 00 00 00 00 00 00 00 00 00 00 00 00 00 00 00 00 00 00 00
			15 01 00 00 00 00 02 6F 60
			39 01 00 00 00 00 19 BE 00 00 00 00 00 00 00 00 00 00 00 00 00 00 00 00 00 00 00 00 00 00 00 00
			15 01 00 00 00 00 02 6F 78
			39 01 00 00 00 00 19 BE 00 00 00 00 00 00 00 00 00 00 00 00 00 00 00 00 00 00 00 00 00 00 00 00
			15 01 00 00 00 00 02 6F 90
			39 01 00 00 00 00 19 BE 00 00 00 00 00 00 00 00 00 00 00 00 00 00 00 00 00 00 00 00 00 00 00 00
			15 01 00 00 00 00 02 6F A8
			39 01 00 00 00 00 19 BE 00 00 00 00 00 00 00 00 00 00 00 00 00 00 00 00 00 00 00 00 00 00 00 00
			15 01 00 00 00 00 02 6F C0
			39 01 00 00 00 00 19 BE 00 00 00 00 00 00 00 00 00 00 00 00 00 00 00 00 00 00 00 00 00 00 00 00
			15 01 00 00 00 00 02 6F D8
			39 01 00 00 00 00 19 BE 00 00 00 00 00 00 00 00 00 00 00 00 00 00 00 00 00 00 00 00 00 00 00 00
			15 01 00 00 00 00 02 6F F0
			39 01 00 00 00 00 0D BE 00 00 00 00 00 00 00 00 00 00 00 00
			39 01 00 00 00 00 19 BF 00 00 00 00 00 00 00 00 00 00 00 00 00 00 00 00 00 00 00 00 00 00 00 00
			15 01 00 00 00 00 02 6F 18
			39 01 00 00 00 00 19 BF 00 00 00 00 00 00 00 00 00 00 00 00 00 00 00 00 00 00 00 00 00 00 00 00
			15 01 00 00 00 00 02 6F 30
			39 01 00 00 00 00 19 BF 00 00 00 00 00 00 00 00 00 00 00 00 00 00 00 00 00 00 00 00 00 00 00 00
			15 01 00 00 00 00 02 6F 48
			39 01 00 00 00 00 19 BF 00 00 00 00 00 00 00 00 00 00 00 00 00 00 00 00 00 00 00 00 00 00 00 00
			15 01 00 00 00 00 02 6F 60
			39 01 00 00 00 00 19 BF 00 00 00 00 00 00 00 00 00 00 00 00 00 00 00 00 00 00 00 00 00 00 00 00
			15 01 00 00 00 00 02 6F 78
			39 01 00 00 00 00 19 BF 00 00 00 00 00 00 00 00 00 00 00 00 00 00 00 00 00 00 00 00 00 00 00 00
			15 01 00 00 00 00 02 6F 90
			39 01 00 00 00 00 19 BF 00 00 00 00 00 00 00 00 00 00 00 00 00 00 00 00 00 00 00 00 00 00 00 00
			15 01 00 00 00 00 02 6F A8
			39 01 00 00 00 00 19 BF 00 00 00 00 00 00 00 00 00 00 00 00 00 00 00 00 00 00 00 00 00 00 00 00
			15 01 00 00 00 00 02 6F C0
			39 01 00 00 00 00 19 BF 00 00 00 00 00 00 00 00 00 00 00 00 00 00 00 00 00 00 00 00 00 00 00 00
			15 01 00 00 00 00 02 6F D8
			39 01 00 00 00 00 19 BF 00 00 00 00 00 00 00 00 00 00 00 00 00 00 00 00 00 00 00 00 00 00 00 00
			15 01 00 00 00 00 02 6F F0
			39 01 00 00 00 00 0D BF 00 00 00 00 00 00 00 00 00 00 00 00
			39 01 00 00 00 00 19 C0 00 00 00 00 00 00 00 00 00 00 00 00 00 00 00 00 00 00 00 00 00 00 00 00
			15 01 00 00 00 00 02 6F 18
			39 01 00 00 00 00 19 C0 00 00 00 00 00 00 00 00 00 00 00 00 00 00 00 00 00 00 00 00 00 00 00 00
			15 01 00 00 00 00 02 6F 30
			39 01 00 00 00 00 19 C0 00 00 00 00 00 00 00 00 00 00 00 00 00 00 00 00 00 00 00 00 00 00 00 00
			15 01 00 00 00 00 02 6F 48
			39 01 00 00 00 00 19 C0 00 00 00 00 00 00 00 00 00 00 00 00 00 00 00 00 00 00 00 00 00 00 00 00
			15 01 00 00 00 00 02 6F 60
			39 01 00 00 00 00 19 C0 00 00 00 00 00 00 00 00 00 00 00 00 00 00 00 00 00 00 00 00 00 00 00 00
			15 01 00 00 00 00 02 6F 78
			39 01 00 00 00 00 19 C0 00 00 00 00 00 00 00 00 00 00 00 00 00 00 00 00 00 00 00 00 00 00 00 00
			15 01 00 00 00 00 02 6F 90
			39 01 00 00 00 00 19 C0 00 00 00 00 00 00 00 00 00 00 00 00 00 00 00 00 00 00 00 00 00 00 00 00
			15 01 00 00 00 00 02 6F A8
			39 01 00 00 00 00 19 C0 00 00 00 00 00 00 00 00 00 00 00 00 00 00 00 00 00 00 00 00 00 00 00 00
			15 01 00 00 00 00 02 6F C0
			39 01 00 00 00 00 19 C0 00 00 00 00 00 00 00 00 00 00 00 00 00 00 00 00 00 00 00 00 00 00 00 00
			15 01 00 00 00 00 02 6F D8
			39 01 00 00 00 00 19 C0 00 00 00 00 00 00 00 00 00 00 00 00 00 00 00 00 00 00 00 00 00 00 00 00
			15 01 00 00 00 00 02 6F F0
			39 01 00 00 00 00 0D C0 00 00 00 00 00 00 00 00 00 00 00 00

			39 01 00 00 00 00 19 C3 00 00 00 60 90 00 00 00 00 00 10 1F 00 00 00 00 50 21 00 00 00 00 00 00
			15 01 00 00 00 00 02 6F 18
			39 01 00 00 00 00 19 C3 00 00 00 00 00 00 00 00 00 00 00 18 00 00 00 00 00 00 00 00 00 00 00 10
			15 01 00 00 00 00 02 6F 30
			39 01 00 00 00 00 19 C3 00 00 00 00 00 00 00 00 00 00 00 10 00 00 00 00 00 00 00 00 00 00 00 10
			15 01 00 00 00 00 02 6F 48
			39 01 00 00 00 00 19 C3 00 00 00 00 00 00 00 00 00 00 00 08 00 00 00 00 00 00 00 00 00 00 00 08
			15 01 00 00 00 00 02 6F 60
			39 01 00 00 00 00 19 C3 00 00 00 00 00 00 00 00 00 00 00 08 00 00 00 00 00 00 00 00 00 00 00 08
			15 01 00 00 00 00 02 6F 78
			39 01 00 00 00 00 19 C3 00 00 00 00 00 00 00 00 00 00 00 00 00 00 00 00 00 00 00 00 00 00 00 08
			15 01 00 00 00 00 02 6F 90
			39 01 00 00 00 00 19 C3 00 00 00 00 00 00 00 00 00 00 00 00 00 00 00 00 00 00 00 00 00 00 00 08
			15 01 00 00 00 00 02 6F A8
			39 01 00 00 00 00 19 C3 00 00 00 00 00 00 00 00 00 00 00 00 00 00 00 00 00 00 00 00 00 00 00 08
			15 01 00 00 00 00 02 6F C0
			39 01 00 00 00 00 19 C3 00 00 00 00 00 00 00 00 00 00 00 00 00 00 00 00 00 00 00 00 00 00 00 00
			15 01 00 00 00 00 02 6F D8
			39 01 00 00 00 00 19 C3 00 00 00 00 00 00 00 00 00 00 00 08 00 00 00 00 00 00 00 00 00 00 00 00
			15 01 00 00 00 00 02 6F F0
			39 01 00 00 00 00 0D C3 00 00 00 00 00 00 00 00 00 00 00 00
			39 01 00 00 00 00 19 C4 00 00 00 00 00 00 00 00 00 00 00 00 00 00 00 00 00 00 00 00 00 00 00 00
			15 01 00 00 00 00 02 6F 18
			39 01 00 00 00 00 19 C4 00 00 00 00 00 00 00 00 00 00 00 00 00 00 00 00 00 00 00 00 00 00 00 00
			15 01 00 00 00 00 02 6F 30
			39 01 00 00 00 00 19 C4 00 00 00 00 00 00 00 00 00 00 00 00 00 00 00 00 00 00 00 00 00 00 00 08
			15 01 00 00 00 00 02 6F 48
			39 01 00 00 00 00 19 C4 00 00 00 00 00 00 00 00 00 00 00 00 00 00 00 00 00 00 00 00 00 00 00 00
			15 01 00 00 00 00 02 6F 60
			39 01 00 00 00 00 19 C4 00 00 00 00 00 00 00 00 00 00 00 08 00 00 00 00 00 00 00 00 00 00 00 00
			15 01 00 00 00 00 02 6F 78
			39 01 00 00 00 00 19 C4 00 00 00 00 00 00 00 00 00 00 00 08 00 00 00 00 00 00 00 00 00 00 00 00
			15 01 00 00 00 00 02 6F 90
			39 01 00 00 00 00 19 C4 00 00 00 00 00 00 00 00 00 00 00 08 00 00 00 00 00 00 00 00 00 00 00 00
			15 01 00 00 00 00 02 6F A8
			39 01 00 00 00 00 19 C4 00 00 00 00 00 00 00 00 00 00 00 08 00 00 00 00 00 00 00 00 00 00 00 08
			15 01 00 00 00 00 02 6F C0
			39 01 00 00 00 00 19 C4 00 00 00 00 00 00 00 00 00 00 00 08 00 00 00 00 00 00 00 00 00 00 00 08
			15 01 00 00 00 00 02 6F D8
			39 01 00 00 00 00 19 C4 00 00 00 00 00 00 00 00 00 00 00 10 00 00 00 00 00 00 00 00 00 00 00 10
			15 01 00 00 00 00 02 6F F0
			39 01 00 00 00 00 0D C4 00 00 00 00 00 00 00 00 00 00 00 10
			39 01 00 00 00 00 19 C5 00 00 00 00 00 00 00 00 00 00 00 18 00 00 00 00 00 00 00 00 00 00 00 00
			15 01 00 00 00 00 02 6F 18
			39 01 00 00 00 00 19 C5 00 00 00 00 00 00 00 00 00 00 00 00 00 00 00 00 00 00 00 00 00 00 00 00
			15 01 00 00 00 00 02 6F 30
			39 01 00 00 00 00 19 C5 00 00 00 00 00 00 00 00 00 00 00 00 00 00 00 00 00 00 00 00 00 00 00 00
			15 01 00 00 00 00 02 6F 48
			39 01 00 00 00 00 19 C5 00 00 00 00 00 00 00 00 00 00 00 00 00 00 00 00 00 00 00 00 00 00 00 00
			15 01 00 00 00 00 02 6F 60
			39 01 00 00 00 00 19 C5 00 00 00 00 00 00 00 00 00 00 00 00 00 00 00 00 00 00 00 00 00 00 00 00
			15 01 00 00 00 00 02 6F 78
			39 01 00 00 00 00 19 C5 00 00 00 00 00 00 00 00 00 00 00 00 00 00 00 00 00 00 00 00 00 00 00 00
			15 01 00 00 00 00 02 6F 90
			39 01 00 00 00 00 19 C5 00 00 00 00 00 00 00 00 00 00 00 00 00 00 00 00 00 00 00 00 00 00 00 00
			15 01 00 00 00 00 02 6F A8
			39 01 00 00 00 00 19 C5 00 00 00 00 00 00 00 00 00 00 00 00 00 00 00 00 00 00 00 00 00 00 00 00
			15 01 00 00 00 00 02 6F C0
			39 01 00 00 00 00 19 C5 00 00 00 00 00 00 00 00 00 00 00 00 00 00 00 00 00 00 00 00 00 00 00 00
			15 01 00 00 00 00 02 6F D8
			39 01 00 00 00 00 19 C5 00 00 00 00 00 00 00 00 00 00 00 00 00 00 00 00 00 00 00 00 00 00 00 00
			15 01 00 00 00 00 02 6F F0
			39 01 00 00 00 00 0D C5 00 00 00 00 00 00 00 00 00 00 00 00
			39 01 00 00 00 00 19 C6 00 00 00 00 00 00 00 00 00 00 00 00 00 00 00 00 00 00 00 00 00 00 00 00
			15 01 00 00 00 00 02 6F 18
			39 01 00 00 00 00 19 C6 00 00 00 00 00 00 00 00 00 00 00 00 00 00 00 00 00 00 00 00 00 00 00 00
			15 01 00 00 00 00 02 6F 30
			39 01 00 00 00 00 19 C6 00 00 00 00 00 00 00 00 00 00 00 00 00 00 00 00 00 00 00 00 00 00 00 00
			15 01 00 00 00 00 02 6F 48
			39 01 00 00 00 00 19 C6 00 00 00 00 00 00 00 00 00 00 00 00 00 00 00 00 00 00 00 00 00 00 00 00
			15 01 00 00 00 00 02 6F 60
			39 01 00 00 00 00 19 C6 00 00 00 00 00 00 00 00 00 00 00 00 00 00 00 00 00 00 00 00 00 00 00 00
			15 01 00 00 00 00 02 6F 78
			39 01 00 00 00 00 19 C6 00 00 00 00 00 00 00 00 00 00 00 00 00 00 00 00 00 00 00 00 00 00 00 00
			15 01 00 00 00 00 02 6F 90
			39 01 00 00 00 00 19 C6 00 00 00 00 00 00 00 00 00 00 00 00 00 00 00 00 00 00 00 00 00 00 00 00
			15 01 00 00 00 00 02 6F A8
			39 01 00 00 00 00 19 C6 00 00 00 00 00 00 00 00 00 00 00 00 00 00 00 00 00 00 00 00 00 00 00 00
			15 01 00 00 00 00 02 6F C0
			39 01 00 00 00 00 19 C6 00 00 00 00 00 00 00 00 00 00 00 00 00 00 00 00 00 00 00 00 00 00 00 00
			15 01 00 00 00 00 02 6F D8
			39 01 00 00 00 00 19 C6 00 00 00 00 00 00 00 00 00 00 00 00 00 00 00 00 00 00 00 00 00 00 00 00
			15 01 00 00 00 00 02 6F F0
			39 01 00 00 00 00 0D C6 00 00 00 00 00 00 00 00 00 00 00 00
			39 01 00 00 00 00 19 C7 00 00 00 00 00 00 00 00 00 00 00 00 00 00 00 00 00 00 00 00 00 00 00 00
			15 01 00 00 00 00 02 6F 18
			39 01 00 00 00 00 19 C7 00 00 00 00 00 00 00 00 00 00 00 00 00 00 00 00 00 00 00 00 00 00 00 00
			15 01 00 00 00 00 02 6F 30
			39 01 00 00 00 00 19 C7 00 00 00 00 00 00 00 00 00 00 00 00 00 00 00 00 00 00 00 00 00 00 00 00
			15 01 00 00 00 00 02 6F 48
			39 01 00 00 00 00 19 C7 00 00 00 00 00 00 00 00 00 00 00 00 00 00 00 00 00 00 00 00 00 00 00 00
			15 01 00 00 00 00 02 6F 60
			39 01 00 00 00 00 19 C7 00 00 00 00 00 00 00 00 00 00 00 00 00 00 00 00 00 00 00 00 00 00 00 00
			15 01 00 00 00 00 02 6F 78
			39 01 00 00 00 00 19 C7 00 00 00 00 00 00 00 00 00 00 00 00 00 00 00 00 00 00 00 00 00 00 00 00
			15 01 00 00 00 00 02 6F 90
			39 01 00 00 00 00 19 C7 00 00 00 00 00 00 00 00 00 00 00 00 00 00 00 00 00 00 00 00 00 00 00 00
			15 01 00 00 00 00 02 6F A8
			39 01 00 00 00 00 19 C7 00 00 00 00 00 00 00 00 00 00 00 00 00 00 00 00 00 00 00 00 00 00 00 00
			15 01 00 00 00 00 02 6F C0
			39 01 00 00 00 00 19 C7 00 00 00 00 00 00 00 00 00 00 00 00 00 00 00 00 00 00 00 00 00 00 00 00
			15 01 00 00 00 00 02 6F D8
			39 01 00 00 00 00 19 C7 00 00 00 00 00 00 00 00 00 00 00 00 00 00 00 00 00 00 00 00 00 00 00 00
			15 01 00 00 00 00 02 6F F0
			39 01 00 00 00 00 0D C7 00 00 00 00 00 00 00 00 00 00 00 00
			39 01 00 00 00 00 19 C8 00 00 00 00 00 00 00 00 00 00 00 00 00 00 00 00 00 00 00 00 00 00 00 00
			15 01 00 00 00 00 02 6F 18
			39 01 00 00 00 00 19 C8 00 00 00 00 00 00 00 00 00 00 00 00 00 00 00 00 00 00 00 00 00 00 00 00
			15 01 00 00 00 00 02 6F 30
			39 01 00 00 00 00 19 C8 00 00 00 00 00 00 00 00 00 00 00 00 00 00 00 00 00 00 00 00 00 00 00 00
			15 01 00 00 00 00 02 6F 48
			39 01 00 00 00 00 19 C8 00 00 00 00 00 00 00 00 00 00 00 00 00 00 00 00 00 00 00 00 00 00 00 00
			15 01 00 00 00 00 02 6F 60
			39 01 00 00 00 00 19 C8 00 00 00 00 00 00 00 00 00 00 00 00 00 00 00 00 00 00 00 00 00 00 00 00
			15 01 00 00 00 00 02 6F 78
			39 01 00 00 00 00 19 C8 00 00 00 00 00 00 00 00 00 00 00 00 00 00 00 00 00 00 00 00 00 00 00 00
			15 01 00 00 00 00 02 6F 90
			39 01 00 00 00 00 19 C8 00 00 00 00 00 00 00 00 00 00 00 00 00 00 00 00 00 00 00 00 00 00 00 00
			15 01 00 00 00 00 02 6F A8
			39 01 00 00 00 00 19 C8 00 00 00 00 00 00 00 00 00 00 00 00 00 00 00 00 00 00 00 00 00 00 00 00
			15 01 00 00 00 00 02 6F C0
			39 01 00 00 00 00 19 C8 00 00 00 00 00 00 00 00 00 00 00 00 00 00 00 00 00 00 00 00 00 00 00 00
			15 01 00 00 00 00 02 6F D8
			39 01 00 00 00 00 19 C8 00 00 00 00 00 00 00 00 00 00 00 00 00 00 00 00 00 00 00 00 00 00 00 00
			15 01 00 00 00 00 02 6F F0
			39 01 00 00 00 00 0D C8 00 00 00 00 00 00 00 00 00 00 00 00
			39 01 00 00 00 00 19 C9 00 00 00 00 00 00 00 00 00 00 00 00 00 00 00 00 00 00 00 00 00 00 00 00
			15 01 00 00 00 00 02 6F 18
			39 01 00 00 00 00 19 C9 00 00 00 00 00 00 00 00 00 00 00 00 00 00 00 00 00 00 00 00 00 00 00 00
			15 01 00 00 00 00 02 6F 30
			39 01 00 00 00 00 19 C9 00 00 00 00 00 00 00 00 00 00 00 00 00 00 00 00 00 00 00 00 00 00 00 00
			15 01 00 00 00 00 02 6F 48
			39 01 00 00 00 00 19 C9 00 00 00 00 00 00 00 00 00 00 00 00 00 00 00 00 00 00 00 00 00 00 00 00
			15 01 00 00 00 00 02 6F 60
			39 01 00 00 00 00 19 C9 00 00 00 00 00 00 00 00 00 00 00 00 00 00 00 00 00 00 00 00 00 00 00 00
			15 01 00 00 00 00 02 6F 78
			39 01 00 00 00 00 19 C9 00 00 00 00 00 00 00 00 00 00 00 00 00 00 00 00 00 00 00 00 00 00 00 00
			15 01 00 00 00 00 02 6F 90
			39 01 00 00 00 00 19 C9 00 00 00 00 00 00 00 00 00 00 00 00 00 00 00 00 00 00 00 00 00 00 00 00
			15 01 00 00 00 00 02 6F A8
			39 01 00 00 00 00 19 C9 00 00 00 00 00 00 00 00 00 00 00 00 00 00 00 00 00 00 00 00 00 00 00 00
			15 01 00 00 00 00 02 6F C0
			39 01 00 00 00 00 19 C9 00 00 00 00 00 00 00 00 00 00 00 00 00 00 00 00 00 00 00 00 00 00 00 00
			15 01 00 00 00 00 02 6F D8
			39 01 00 00 00 00 19 C9 00 00 00 00 00 00 00 00 00 00 00 00 00 00 00 00 00 00 00 00 00 00 00 00
			15 01 00 00 00 00 02 6F F0
			39 01 00 00 00 00 0D C9 00 00 00 00 00 00 00 00 00 00 00 00

			39 01 00 00 00 00 19 CC 00 00 00 60 90 00 00 00 00 00 80 24 00 00 00 00 40 22 00 00 00 00 00 00
			15 01 00 00 00 00 02 6F 18
			39 01 00 00 00 00 19 CC 00 00 00 00 00 00 00 00 00 00 00 18 00 00 00 00 00 00 00 00 00 00 00 10
			15 01 00 00 00 00 02 6F 30
			39 01 00 00 00 00 19 CC 00 00 00 00 00 00 00 00 00 00 00 10 00 00 00 00 00 00 00 00 00 00 00 10
			15 01 00 00 00 00 02 6F 48
			39 01 00 00 00 00 19 CC 00 00 00 00 00 00 00 00 00 00 00 08 00 00 00 00 00 00 00 00 00 00 00 08
			15 01 00 00 00 00 02 6F 60
			39 01 00 00 00 00 19 CC 00 00 00 00 00 00 00 00 00 00 00 08 00 00 00 00 00 00 00 00 00 00 00 08
			15 01 00 00 00 00 02 6F 78
			39 01 00 00 00 00 19 CC 00 00 00 00 00 00 00 00 00 00 00 00 00 00 00 00 00 00 00 00 00 00 00 08
			15 01 00 00 00 00 02 6F 90
			39 01 00 00 00 00 19 CC 00 00 00 00 00 00 00 00 00 00 00 00 00 00 00 00 00 00 00 00 00 00 00 08
			15 01 00 00 00 00 02 6F A8
			39 01 00 00 00 00 19 CC 00 00 00 00 00 00 00 00 00 00 00 00 00 00 00 00 00 00 00 00 00 00 00 08
			15 01 00 00 00 00 02 6F C0
			39 01 00 00 00 00 19 CC 00 00 00 00 00 00 00 00 00 00 00 00 00 00 00 00 00 00 00 00 00 00 00 00
			15 01 00 00 00 00 02 6F D8
			39 01 00 00 00 00 19 CC 00 00 00 00 00 00 00 00 00 00 00 08 00 00 00 00 00 00 00 00 00 00 00 00
			15 01 00 00 00 00 02 6F F0
			39 01 00 00 00 00 0D CC 00 00 00 00 00 00 00 00 00 00 00 00
			39 01 00 00 00 00 19 CD 00 00 00 00 00 00 00 00 00 00 00 00 00 00 00 00 00 00 00 00 00 00 00 00
			15 01 00 00 00 00 02 6F 18
			39 01 00 00 00 00 19 CD 00 00 00 00 00 00 00 00 00 00 00 00 00 00 00 00 00 00 00 00 00 00 00 00
			15 01 00 00 00 00 02 6F 30
			39 01 00 00 00 00 19 CD 00 00 00 00 00 00 00 00 00 00 00 00 00 00 00 00 00 00 00 00 00 00 00 08
			15 01 00 00 00 00 02 6F 48
			39 01 00 00 00 00 19 CD 00 00 00 00 00 00 00 00 00 00 00 00 00 00 00 00 00 00 00 00 00 00 00 00
			15 01 00 00 00 00 02 6F 60
			39 01 00 00 00 00 19 CD 00 00 00 00 00 00 00 00 00 00 00 08 00 00 00 00 00 00 00 00 00 00 00 00
			15 01 00 00 00 00 02 6F 78
			39 01 00 00 00 00 19 CD 00 00 00 00 00 00 00 00 00 00 00 08 00 00 00 00 00 00 00 00 00 00 00 00
			15 01 00 00 00 00 02 6F 90
			39 01 00 00 00 00 19 CD 00 00 00 00 00 00 00 00 00 00 00 08 00 00 00 00 00 00 00 00 00 00 00 00
			15 01 00 00 00 00 02 6F A8
			39 01 00 00 00 00 19 CD 00 00 00 00 00 00 00 00 00 00 00 08 00 00 00 00 00 00 00 00 00 00 00 08
			15 01 00 00 00 00 02 6F C0
			39 01 00 00 00 00 19 CD 00 00 00 00 00 00 00 00 00 00 00 08 00 00 00 00 00 00 00 00 00 00 00 08
			15 01 00 00 00 00 02 6F D8
			39 01 00 00 00 00 19 CD 00 00 00 00 00 00 00 00 00 00 00 10 00 00 00 00 00 00 00 00 00 00 00 10
			15 01 00 00 00 00 02 6F F0
			39 01 00 00 00 00 0D CD 00 00 00 00 00 00 00 00 00 00 00 10
			39 01 00 00 00 00 19 CE 00 00 00 00 00 00 00 00 00 00 00 18 00 00 00 00 00 00 00 00 00 00 00 00
			15 01 00 00 00 00 02 6F 18
			39 01 00 00 00 00 19 CE 00 00 00 00 00 00 00 00 00 00 00 00 00 00 00 00 00 00 00 00 00 00 00 00
			15 01 00 00 00 00 02 6F 30
			39 01 00 00 00 00 19 CE 00 00 00 00 00 00 00 00 00 00 00 00 00 00 00 00 00 00 00 00 00 00 00 00
			15 01 00 00 00 00 02 6F 48
			39 01 00 00 00 00 19 CE 00 00 00 00 00 00 00 00 00 00 00 00 00 00 00 00 00 00 00 00 00 00 00 00
			15 01 00 00 00 00 02 6F 60
			39 01 00 00 00 00 19 CE 00 00 00 00 00 00 00 00 00 00 00 00 00 00 00 00 00 00 00 00 00 00 00 00
			15 01 00 00 00 00 02 6F 78
			39 01 00 00 00 00 19 CE 00 00 00 00 00 00 00 00 00 00 00 00 00 00 00 00 00 00 00 00 00 00 00 00
			15 01 00 00 00 00 02 6F 90
			39 01 00 00 00 00 19 CE 00 00 00 00 00 00 00 00 00 00 00 00 00 00 00 00 00 00 00 00 00 00 00 00
			15 01 00 00 00 00 02 6F A8
			39 01 00 00 00 00 19 CE 00 00 00 00 00 00 00 00 00 00 00 00 00 00 00 00 00 00 00 00 00 00 00 00
			15 01 00 00 00 00 02 6F C0
			39 01 00 00 00 00 19 CE 00 00 00 00 00 00 00 00 00 00 00 00 00 00 00 00 00 00 00 00 00 00 00 00
			15 01 00 00 00 00 02 6F D8
			39 01 00 00 00 00 19 CE 00 00 00 00 00 00 00 00 00 00 00 00 00 00 00 00 00 00 00 00 00 00 00 00
			15 01 00 00 00 00 02 6F F0
			39 01 00 00 00 00 0D CE 00 00 00 00 00 00 00 00 00 00 00 00
			39 01 00 00 00 00 19 CF 00 00 00 00 00 00 00 00 00 00 00 00 00 00 00 00 00 00 00 00 00 00 00 00
			15 01 00 00 00 00 02 6F 18
			39 01 00 00 00 00 19 CF 00 00 00 00 00 00 00 00 00 00 00 00 00 00 00 00 00 00 00 00 00 00 00 00
			15 01 00 00 00 00 02 6F 30
			39 01 00 00 00 00 19 CF 00 00 00 00 00 00 00 00 00 00 00 00 00 00 00 00 00 00 00 00 00 00 00 00
			15 01 00 00 00 00 02 6F 48
			39 01 00 00 00 00 19 CF 00 00 00 00 00 00 00 00 00 00 00 00 00 00 00 00 00 00 00 00 00 00 00 00
			15 01 00 00 00 00 02 6F 60
			39 01 00 00 00 00 19 CF 00 00 00 00 00 00 00 00 00 00 00 00 00 00 00 00 00 00 00 00 00 00 00 00
			15 01 00 00 00 00 02 6F 78
			39 01 00 00 00 00 19 CF 00 00 00 00 00 00 00 00 00 00 00 00 00 00 00 00 00 00 00 00 00 00 00 00
			15 01 00 00 00 00 02 6F 90
			39 01 00 00 00 00 19 CF 00 00 00 00 00 00 00 00 00 00 00 00 00 00 00 00 00 00 00 00 00 00 00 00
			15 01 00 00 00 00 02 6F A8
			39 01 00 00 00 00 19 CF 00 00 00 00 00 00 00 00 00 00 00 00 00 00 00 00 00 00 00 00 00 00 00 00
			15 01 00 00 00 00 02 6F C0
			39 01 00 00 00 00 19 CF 00 00 00 00 00 00 00 00 00 00 00 00 00 00 00 00 00 00 00 00 00 00 00 00
			15 01 00 00 00 00 02 6F D8
			39 01 00 00 00 00 19 CF 00 00 00 00 00 00 00 00 00 00 00 00 00 00 00 00 00 00 00 00 00 00 00 00
			15 01 00 00 00 00 02 6F F0
			39 01 00 00 00 00 0D CF 00 00 00 00 00 00 00 00 00 00 00 00
			39 01 00 00 00 00 19 D0 00 00 00 00 00 00 00 00 00 00 00 00 00 00 00 00 00 00 00 00 00 00 00 00
			15 01 00 00 00 00 02 6F 18
			39 01 00 00 00 00 19 D0 00 00 00 00 00 00 00 00 00 00 00 00 00 00 00 00 00 00 00 00 00 00 00 00
			15 01 00 00 00 00 02 6F 30
			39 01 00 00 00 00 19 D0 00 00 00 00 00 00 00 00 00 00 00 00 00 00 00 00 00 00 00 00 00 00 00 00
			15 01 00 00 00 00 02 6F 48
			39 01 00 00 00 00 19 D0 00 00 00 00 00 00 00 00 00 00 00 00 00 00 00 00 00 00 00 00 00 00 00 00
			15 01 00 00 00 00 02 6F 60
			39 01 00 00 00 00 19 D0 00 00 00 00 00 00 00 00 00 00 00 00 00 00 00 00 00 00 00 00 00 00 00 00
			15 01 00 00 00 00 02 6F 78
			39 01 00 00 00 00 19 D0 00 00 00 00 00 00 00 00 00 00 00 00 00 00 00 00 00 00 00 00 00 00 00 00
			15 01 00 00 00 00 02 6F 90
			39 01 00 00 00 00 19 D0 00 00 00 00 00 00 00 00 00 00 00 00 00 00 00 00 00 00 00 00 00 00 00 00
			15 01 00 00 00 00 02 6F A8
			39 01 00 00 00 00 19 D0 00 00 00 00 00 00 00 00 00 00 00 00 00 00 00 00 00 00 00 00 00 00 00 00
			15 01 00 00 00 00 02 6F C0
			39 01 00 00 00 00 19 D0 00 00 00 00 00 00 00 00 00 00 00 00 00 00 00 00 00 00 00 00 00 00 00 00
			15 01 00 00 00 00 02 6F D8
			39 01 00 00 00 00 19 D0 00 00 00 00 00 00 00 00 00 00 00 00 00 00 00 00 00 00 00 00 00 00 00 00
			15 01 00 00 00 00 02 6F F0
			39 01 00 00 00 00 0D D0 00 00 00 00 00 00 00 00 00 00 00 00
			39 01 00 00 00 00 19 D1 00 00 00 00 00 00 00 00 00 00 00 00 00 00 00 00 00 00 00 00 00 00 00 00
			15 01 00 00 00 00 02 6F 18
			39 01 00 00 00 00 19 D1 00 00 00 00 00 00 00 00 00 00 00 00 00 00 00 00 00 00 00 00 00 00 00 00
			15 01 00 00 00 00 02 6F 30
			39 01 00 00 00 00 19 D1 00 00 00 00 00 00 00 00 00 00 00 00 00 00 00 00 00 00 00 00 00 00 00 00
			15 01 00 00 00 00 02 6F 48
			39 01 00 00 00 00 19 D1 00 00 00 00 00 00 00 00 00 00 00 00 00 00 00 00 00 00 00 00 00 00 00 00
			15 01 00 00 00 00 02 6F 60
			39 01 00 00 00 00 19 D1 00 00 00 00 00 00 00 00 00 00 00 00 00 00 00 00 00 00 00 00 00 00 00 00
			15 01 00 00 00 00 02 6F 78
			39 01 00 00 00 00 19 D1 00 00 00 00 00 00 00 00 00 00 00 00 00 00 00 00 00 00 00 00 00 00 00 00
			15 01 00 00 00 00 02 6F 90
			39 01 00 00 00 00 19 D1 00 00 00 00 00 00 00 00 00 00 00 00 00 00 00 00 00 00 00 00 00 00 00 00
			15 01 00 00 00 00 02 6F A8
			39 01 00 00 00 00 19 D1 00 00 00 00 00 00 00 00 00 00 00 00 00 00 00 00 00 00 00 00 00 00 00 00
			15 01 00 00 00 00 02 6F C0
			39 01 00 00 00 00 19 D1 00 00 00 00 00 00 00 00 00 00 00 00 00 00 00 00 00 00 00 00 00 00 00 00
			15 01 00 00 00 00 02 6F D8
			39 01 00 00 00 00 19 D1 00 00 00 00 00 00 00 00 00 00 00 00 00 00 00 00 00 00 00 00 00 00 00 00
			15 01 00 00 00 00 02 6F F0
			39 01 00 00 00 00 0D D1 00 00 00 00 00 00 00 00 00 00 00 00
			39 01 00 00 00 00 19 D2 00 00 00 00 00 00 00 00 00 00 00 00 00 00 00 00 00 00 00 00 00 00 00 00
			15 01 00 00 00 00 02 6F 18
			39 01 00 00 00 00 19 D2 00 00 00 00 00 00 00 00 00 00 00 00 00 00 00 00 00 00 00 00 00 00 00 00
			15 01 00 00 00 00 02 6F 30
			39 01 00 00 00 00 19 D2 00 00 00 00 00 00 00 00 00 00 00 00 00 00 00 00 00 00 00 00 00 00 00 00
			15 01 00 00 00 00 02 6F 48
			39 01 00 00 00 00 19 D2 00 00 00 00 00 00 00 00 00 00 00 00 00 00 00 00 00 00 00 00 00 00 00 00
			15 01 00 00 00 00 02 6F 60
			39 01 00 00 00 00 19 D2 00 00 00 00 00 00 00 00 00 00 00 00 00 00 00 00 00 00 00 00 00 00 00 00
			15 01 00 00 00 00 02 6F 78
			39 01 00 00 00 00 19 D2 00 00 00 00 00 00 00 00 00 00 00 00 00 00 00 00 00 00 00 00 00 00 00 00
			15 01 00 00 00 00 02 6F 90
			39 01 00 00 00 00 19 D2 00 00 00 00 00 00 00 00 00 00 00 00 00 00 00 00 00 00 00 00 00 00 00 00
			15 01 00 00 00 00 02 6F A8
			39 01 00 00 00 00 19 D2 00 00 00 00 00 00 00 00 00 00 00 00 00 00 00 00 00 00 00 00 00 00 00 00
			15 01 00 00 00 00 02 6F C0
			39 01 00 00 00 00 19 D2 00 00 00 00 00 00 00 00 00 00 00 00 00 00 00 00 00 00 00 00 00 00 00 00
			15 01 00 00 00 00 02 6F D8
			39 01 00 00 00 00 19 D2 00 00 00 00 00 00 00 00 00 00 00 00 00 00 00 00 00 00 00 00 00 00 00 00
			15 01 00 00 00 00 02 6F F0
			39 01 00 00 00 00 0D D2 00 00 00 00 00 00 00 00 00 00 00 00

			15 01 00 00 00 00 02 B0 00
			39 01 00 00 00 00 19 D5 80 00 48 00 FF FF FF FF 00 00 00 00 00 00 00 00 00 00 00 00 00 00 00 00
			15 01 00 00 00 00 02 6F 18
			39 01 00 00 00 00 19 D5 00 00 00 00 00 00 00 00 00 0B 5E 00 0B 5E 00 0B 5E 00 0B 5E 00 0B 5E 00
			15 01 00 00 00 00 02 6F 30
			39 01 00 00 00 00 19 D5 0B 5E 00 0B 5E 00 0B 5E 00 69 3C 00 00 00 00 08 61 00 0B 5E 00 0B 5E 00
			15 01 00 00 00 00 02 6F 48
			39 01 00 00 00 00 19 D5 0B 5E 00 0B 5E 00 0B 5E 00 0B 5E 00 0B 5E 00 0B 5E 00 3C 00 08 61 46 64

			39 01 00 00 00 00 19 D6 55 55 55 55 55 55 55 55 55 55 55 55 55 55 55 55 55 55 55 55 55 55 55 55
			15 01 00 00 00 00 02 6F 18
			39 01 00 00 00 00 19 D6 55 55 55 55 55 55 55 55 55 55 55 55 55 55 55 55 55 55 55 55 55 55 55 55
			15 01 00 00 00 00 02 6F 30
			39 01 00 00 00 00 19 D6 55 55 55 55 55 55 55 55 55 55 55 55 55 55 55 55 80 80 80 00 00 00 FF FF
			15 01 00 00 00 00 02 6F 48
			39 01 00 00 00 00 19 D6 FF 45 45 45 45 45 45 45 45 45 45 45 45 45 45 45 45 45 45 45 45 45 00 00
			15 01 00 00 00 00 02 6F 60
			39 01 00 00 00 00 19 D6 00 3C 3C 3C 33 33 33 2B 2B 2B 22 22 22 19 19 19 11 11 11 08 08 08 00 00
			15 01 00 00 00 00 02 6F 78
			39 01 00 00 00 00 19 D6 00 00 00 00 00 00 00 00 00 00 00 00 00 00 00 00 00 00 00 00 00 00 00 00
			15 01 00 00 00 00 02 6F 90
			15 01 00 00 00 00 02 D6 00
			39 01 00 00 00 00 19 D7 55 55 55 55 55 55 55 55 55 55 55 55 55 55 55 55 54 54 00 00 54 54 00 00
			15 01 00 00 00 00 02 6F 18
			39 01 00 00 00 00 19 D7 54 54 AA AA 54 54 00 80 15 55 15 45 55 05 05 05 50 50 50 50 50 50 50 50
			15 01 00 00 00 00 02 6F 30
			39 01 00 00 00 00 19 D7 00 00 55 55 00 00 55 55 55 55 00 00 55 55 00 00 00 00 00 00 00 00 00 00
			15 01 00 00 00 00 02 6F 48
			39 01 00 00 00 00 19 D7 00 00 00 00 00 00 00 00 00 00 00 00 00 00 00 00 00 00 00 00 00 00 00 00
			15 01 00 00 00 00 02 6F 60
			39 01 00 00 00 00 19 D7 00 00 00 00 00 00 00 00 00 00 00 00 00 00 00 00 00 00 00 00 00 00 00 00
			15 01 00 00 00 00 02 6F 78
			39 01 00 00 00 00 09 D7 00 00 00 00 00 00 00 00
			39 01 00 00 00 00 19 D8 BD FF FD FF FD FF F7 FF F7 FF F7 FF FF FF FF FF FF FF 00 00 00 E6 E6 E6
			15 01 00 00 00 00 02 6F 18
			39 01 00 00 00 00 19 D8 00 00 00 00 00 00 00 00 00 00 00 00 F9 00 00 00 00 00 00 00 00 00 00 00
			15 01 00 00 00 00 02 6F 30
			39 01 00 00 00 00 19 D8 00 00 00 00 00 00 00 00 00 00 00 00 00 00 00 00 00 00 00 00 00 00 00 00
			15 01 00 00 00 00 02 6F 48
			39 01 00 00 00 00 19 D8 00 00 00 FF FF FF 00 00 00 00 00 00 00 00 00 00 00 00 00 00 00 00 00 00
			15 01 00 00 00 00 02 6F 60
			39 01 00 00 00 00 19 D8 00 00 00 00 00 00 00 00 00 00 00 00 00 00 00 00 00 00 00 00 00 00 00 00
			15 01 00 00 00 00 02 6F 78
			39 01 00 00 00 00 19 D8 00 00 00 00 00 00 00 00 00 00 00 00 00 00 00 00 00 00 00 00 00 00 00 00
			15 01 00 00 00 00 02 6F 90
			39 01 00 00 00 00 13 D8 00 00 00 00 00 00 00 00 00 00 00 00 00 00 00 00 00 00
			39 01 00 00 00 00 19 D9 FC 00 8A AA 1A AA AA 98 AA AA 9A AA AA 9A A8 AA AA 06 AA AA 62 AA 8A 8A
			15 01 00 00 00 00 02 6F 18
			39 01 00 00 00 00 19 D9 9A 9A 8A 8A 00 00 00 00 00 00 00 00 00 00 00 00 00 00 00 00 00 00 00 00
			15 01 00 00 00 00 02 6F 30
			39 01 00 00 00 00 09 D9 00 00 00 00 00 00 00 00

			//SPR setting for L area
			39 01 00 00 00 00 06 F0 55 AA 52 08 07
			15 01 00 00 00 00 02 BE 90
			15 01 00 00 00 00 02 6F 03
			39 01 00 00 00 00 07 BE 22 22 22 00 00 00
			15 01 00 00 00 00 02 6F 09
			39 01 00 00 00 00 0D BE 05 05 03 04 03 05 04 04 04 04 04 04

			15 01 00 00 00 00 02 90 01
			39 01 00 00 00 00 13 91 AB 28 00 0C C2 00 03 1C 01 7E 00 0F 08 BB 04 3D 10 F0
			15 01 00 00 00 00 02 03 01
			15 01 00 00 00 00 02 2C 00
			39 01 00 00 00 00 03 51 00 00
			15 01 00 00 00 00 02 53 20
			15 01 00 00 00 00 02 35 00
			39 01 00 00 00 00 05 2A 00 00 04 37
			39 01 00 00 00 00 05 2B 00 00 09 5F
			39 01 00 00 00 00 06 F0 55 AA 52 08 02
			15 01 00 00 00 00 02 6F 03
			15 01 00 00 00 00 02 BF 03
			15 01 00 00 00 00 02 2F 03
			05 01 00 00 78 00 01 11
			05 01 00 00 00 00 01 29];	/* display on */
		qcom,mdss-dsi-off-command = [
			05 01 00 00 00 00 01 28		/* display_off */
			05 01 00 00 78 00 01 10];	/* enter sleep mode */

		qcom,mdss-dsi-on-command-state = "dsi_lp_mode";
		qcom,mdss-dsi-off-command-state = "dsi_lp_mode";
		qcom,mdss-dsi-timing-switch-command-state = "dsi_lp_mode";

		qcom,compression-mode = "dsc";
		qcom,mdss-dsc-version = <0x11>;
		qcom,mdss-dsc-slice-height = <12>;
		qcom,mdss-dsc-slice-width = <1080>;
		qcom,mdss-dsc-slice-per-pkt = <1>;
		qcom,mdss-dsc-bit-per-component = <10>;
		qcom,mdss-dsc-bit-per-pixel = <10>;
		qcom,mdss-dsc-block-prediction-enable;
	};
};

qcom,panel-supply-entries {
	#address-cells = <1>;
	#size-cells = <0>;

	qcom,panel-supply-entry@0 {
		reg = <0>;
		qcom,supply-name = "vddio";
		qcom,supply-min-voltage = <1800000>;
		qcom,supply-max-voltage = <1800000>;
		qcom,supply-enable-load = <62000>;
		qcom,supply-disable-load = <80>;
		qcom,supply-post-on-sleep = <2>;
	};

	qcom,panel-supply-entry@1 {
		reg = <1>;
		qcom,supply-name = "dvdd";
		qcom,supply-min-voltage = <1800000>;
		qcom,supply-max-voltage = <1800000>;
		qcom,supply-enable-load = <100000>;
		qcom,supply-disable-load = <0>;
		qcom,supply-post-on-sleep = <2>;
		qcom,supply-post-off-sleep = <2>;
	};

	qcom,panel-supply-entry@2 {
		reg = <2>;
		qcom,supply-name = "vci";
		qcom,supply-min-voltage = <3000000>;
		qcom,supply-max-voltage = <3000000>;
		qcom,supply-enable-load = <857000>;
		qcom,supply-disable-load = <0>;
		qcom,supply-post-on-sleep = <0>;
		qcom,supply-post-off-sleep = <2>;
	};
};
